VERSION "HNNBNNNYNNNNNNNNNNNNNNNNNNNNNNNNNNNNNNNNNN/4/%%%/4/'%**4NNN///"

NS_ :

BS_:

BU_: BAP_Tester BCM Gateway_Max TSGGen3_BFS TSGGen3_FS TSGGen3_HBFS TSGGen3_HFS WLC_01_CFD

BO_ 2621577104 DIA_VIP_HFS_Resp_FD: 64 BCM
 SG_ DIA_VIP_HFS_Resp_FD_Data : 0|512@1+ (1.0,0.0) [0.0|13407807929942597099574024998205846127479365820592393377723561443721764030073546976801874298166903427690031858186486050853753882811946569946433649006084095] ""  Gateway_Max

BO_ 2549880398 DIA_VIP_Req: 8 Gateway_Max
 SG_ DIA_VIP_Req_Data : 0|64@1+ (1.0,0.0) [0.0|18446744073709551615] ""  BCM

BO_ 2621445710 DIA_VIP_Req_FD: 64 Gateway_Max
 SG_ DIA_VIP_Req_FD_Data : 0|512@1+ (1.0,0.0) [0.0|13407807929942597099574024998205846127479365820592393377723561443721764030073546976801874298166903427690031858186486050853753882811946569946433649006084095] ""  BCM

BO_ 2550011470 DIA_VIP_Resp: 8 BCM
 SG_ DIA_VIP_Resp_Data : 0|64@1+ (1.0,0.0) [0.0|18446744073709551615] ""  Gateway_Max

BO_ 2621576782 DIA_VIP_Resp_FD: 64 BCM
 SG_ DIA_VIP_Resp_FD_Data : 0|512@1+ (1.0,0.0) [0.0|13407807929942597099574024998205846127479365820592393377723561443721764030073546976801874298166903427690031858186486050853753882811946569946433649006084095] ""  Gateway_Max

BO_ 2549880679 DIA_WiBli_L_Req: 8 Gateway_Max
 SG_ DIA_WiBli_L_Req : 0|64@1+ (1.0,0.0) [0.0|18446744073709551615] ""  BCM

BO_ 2550011751 DIA_WiBli_L_Resp: 8 BCM
 SG_ DIA_WiBli_L_Resp : 0|64@1+ (1.0,0.0) [0.0|18446744073709551615] ""  Gateway_Max

BO_ 2549880680 DIA_WiBli_R_Req: 8 Gateway_Max
 SG_ DIA_WiBli_R_Req : 0|64@1+ (1.0,0.0) [0.0|18446744073709551615] ""  BCM

BO_ 2550011752 DIA_WiBli_R_Resp: 8 BCM
 SG_ DIA_WiBli_R_Resp : 0|64@1+ (1.0,0.0) [0.0|18446744073709551615] ""  Gateway_Max

BO_ 2549880321 DIA_WWS_Req: 8 Gateway_Max
 SG_ DIA_WWS_Req_Data : 0|64@1+ (1.0,0.0) [0.0|18446744073709551615] ""  BCM

BO_ 2621445633 DIA_WWS_Req_FD: 64 Gateway_Max
 SG_ DIA_WWS_Req_FD_Data : 0|512@1+ (1.0,0.0) [0.0|13407807929942597099574024998205846127479365820592393377723561443721764030073546976801874298166903427690031858186486050853753882811946569946433649006084095] ""  BCM

BO_ 2550011393 DIA_WWS_Resp: 8 BCM
 SG_ DIA_WWS_Resp_Data : 0|64@1+ (1.0,0.0) [0.0|18446744073709551615] ""  Gateway_Max

BO_ 2621576705 DIA_WWS_Resp_FD: 64 BCM
 SG_ DIA_WWS_Resp_FD_Data : 0|512@1+ (1.0,0.0) [0.0|13407807929942597099574024998205846127479365820592393377723561443721764030073546976801874298166903427690031858186486050853753882811946569946433649006084095] ""  Gateway_Max

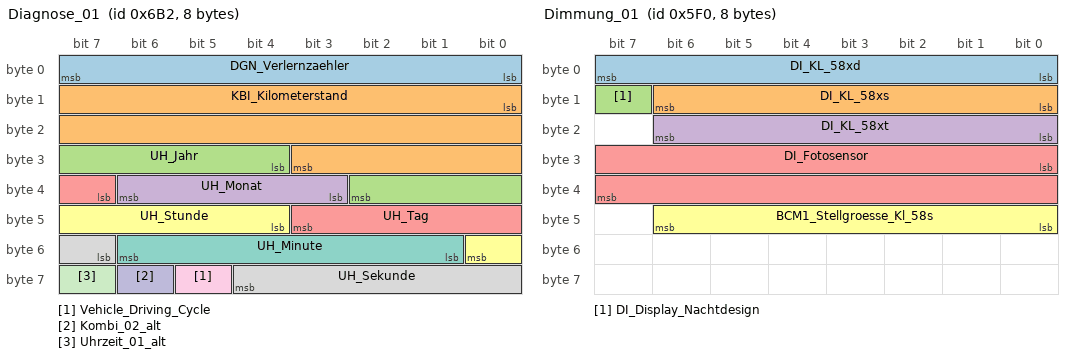
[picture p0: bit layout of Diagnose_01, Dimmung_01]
BO_ 1714 Diagnose_01: 8 Gateway_Max
 SG_ DGN_Verlernzaehler : 0|8@1+ (1,0) [0|254] ""  BCM,TSGGen3_BFS,TSGGen3_FS,TSGGen3_HBFS,TSGGen3_HFS,WLC_01_CFD
 SG_ KBI_Kilometerstand : 8|20@1+ (1,0) [0|1048573] "Unit_KiloMeter"  BCM,TSGGen3_BFS,TSGGen3_FS,TSGGen3_HBFS,TSGGen3_HFS,WLC_01_CFD
 SG_ UH_Jahr : 28|7@1+ (1,2000) [2000|2127] "Unit_Year"  BCM,TSGGen3_BFS,TSGGen3_FS,TSGGen3_HBFS,TSGGen3_HFS,WLC_01_CFD
 SG_ UH_Monat : 35|4@1+ (1,0) [1|12] "Unit_Month"  BCM,TSGGen3_BFS,TSGGen3_FS,TSGGen3_HBFS,TSGGen3_HFS,WLC_01_CFD
 SG_ UH_Tag : 39|5@1+ (1,0) [1|31] "Unit_Day"  BCM,TSGGen3_BFS,TSGGen3_FS,TSGGen3_HBFS,TSGGen3_HFS,WLC_01_CFD
 SG_ UH_Stunde : 44|5@1+ (1,0) [0|23] "Unit_Hours"  BCM,TSGGen3_BFS,TSGGen3_FS,TSGGen3_HBFS,TSGGen3_HFS,WLC_01_CFD
 SG_ UH_Minute : 49|6@1+ (1,0) [0|59] "Unit_Minut"  BCM,TSGGen3_BFS,TSGGen3_FS,TSGGen3_HBFS,TSGGen3_HFS,WLC_01_CFD
 SG_ UH_Sekunde : 55|6@1+ (1,0) [0|59] "Unit_Secon"  BCM,TSGGen3_BFS,TSGGen3_FS,TSGGen3_HBFS,TSGGen3_HFS,WLC_01_CFD
 SG_ Vehicle_Driving_Cycle : 61|1@1+ (1.0,0.0) [0.0|1] ""  BCM
 SG_ Kombi_02_alt : 62|1@1+ (1.0,0.0) [0.0|1] ""  BCM
 SG_ Uhrzeit_01_alt : 63|1@1+ (1.0,0.0) [0.0|1] ""  BCM

BO_ 851 DiETa_01: 8 BCM
 SG_ DiETas_01_CRC : 0|8@1+ (1,0) [0|255] ""  Gateway_Max
 SG_ DiETas_01_BZ : 8|4@1+ (1,0) [0|15] ""  Gateway_Max
 SG_ DiETa_Reserve_Byte2_4 : 12|1@1+ (1.0,0.0) [0.0|1] ""  Gateway_Max
 SG_ DiETa_Status : 13|2@1+ (1.0,0.0) [0.0|3] ""  Gateway_Max
 SG_ DiETa_ResponseError : 15|1@1+ (1.0,0.0) [0.0|1] ""  Gateway_Max
 SG_ DiETa_Car : 16|2@1+ (1.0,0.0) [0.0|3] ""  Gateway_Max
 SG_ DiETa_Klima : 18|2@1+ (1.0,0.0) [0.0|3] ""  Gateway_Max
 SG_ DiETa_Mode : 20|2@1+ (1.0,0.0) [0.0|3] ""  Gateway_Max
 SG_ DiETa_Parken : 22|2@1+ (1.0,0.0) [0.0|3] ""  Gateway_Max
 SG_ DiETa_FSH_Taste : 24|2@1+ (1.0,0.0) [0.0|3] ""  Gateway_Max
 SG_ DiETa_HSH_Taste : 26|2@1+ (1.0,0.0) [0.0|3] ""  Gateway_Max
 SG_ DiETa_Warnblink_Taste : 28|2@1+ (1.0,0.0) [0.0|3] ""  Gateway_Max
 SG_ DiETa_FAS_Stufe : 30|2@1+ (1.0,0.0) [0.0|3] ""  Gateway_Max
 SG_ DiETa_PAO_ON_Status : 32|2@1+ (1.0,0.0) [0.0|3] ""  Gateway_Max
 SG_ DiETa_PAO_OFF_Status : 34|2@1+ (1.0,0.0) [0.0|3] ""  Gateway_Max
 SG_ DiETa_Defrost_Taste : 36|2@1+ (1.0,0.0) [0.0|3] ""  Gateway_Max
 SG_ DiETa_Mode2 : 38|2@1+ (1.0,0.0) [0.0|3] ""  Gateway_Max
 SG_ DiETa_Lock_Unlock_Taste : 40|3@1+ (1.0,0.0) [0.0|7] ""  Gateway_Max
 SG_ DiETa_Mode_roh : 43|1@1+ (1.0,0.0) [0.0|1] ""  Gateway_Max
 SG_ ESP_Off_Taster : 44|2@1+ (1.0,0.0) [0.0|3] ""  Gateway_Max
 SG_ DiETa_Reserve_Byte6_6 : 46|2@1+ (1.0,0.0) [0.0|3] ""  Gateway_Max
 SG_ DiETa_Touch_Event : 48|4@1+ (1.0,0.0) [0.0|15] ""  Gateway_Max
 SG_ DiETa_Reserve_Byte7_4 : 52|4@1+ (1.0,0.0) [0.0|15] ""  Gateway_Max
 SG_ DiETa_Reserve_Byte8 : 56|8@1+ (1.0,0.0) [0.0|255] ""  Gateway_Max

BO_ 1520 Dimmung_01: 8 BCM
 SG_ DI_KL_58xd : 0|8@1+ (1,0) [0|253] ""  Gateway_Max,TSGGen3_BFS,TSGGen3_FS,TSGGen3_HBFS,TSGGen3_HFS
 SG_ DI_KL_58xs : 8|7@1+ (1,0) [0|100] "Unit_PerCent"  Gateway_Max,TSGGen3_BFS,TSGGen3_FS,TSGGen3_HBFS,TSGGen3_HFS
 SG_ DI_Display_Nachtdesign : 15|1@1+ (1.0,0.0) [0.0|1] ""  Gateway_Max
 SG_ DI_KL_58xt : 16|7@1+ (1,0) [0|100] "Unit_PerCent"  Gateway_Max,TSGGen3_BFS,TSGGen3_FS,TSGGen3_HBFS,TSGGen3_HFS
 SG_ DI_Fotosensor : 24|16@1+ (1,0) [0|65535] ""  Gateway_Max
 SG_ BCM1_Stellgroesse_Kl_58s : 40|7@1+ (1,0) [0|100] ""  Gateway_Max

BO_ 2463978728 DoorFunctions_BFS_01: 48 TSGGen3_BFS
 SG_ DoorFunctions_BFS_01_CRC : 0|8@1+ (1,0) [0|255] ""  Gateway_Max,TSGGen3_FS,TSGGen3_HBFS,TSGGen3_HFS
 SG_ DoorFunctions_BFS_01_BZ : 8|4@1+ (1,0) [0|15] ""  Gateway_Max,TSGGen3_FS,TSGGen3_HBFS,TSGGen3_HFS
 SG_ eTAB_BFS_Oeffnen_Betaet : 12|1@1+ (1.0,0.0) [0.0|1] ""  Gateway_Max
 SG_ eTAB_BFS_Oeffnen_Annaeh : 13|1@1+ (1.0,0.0) [0.0|1] ""  Gateway_Max
 SG_ eTAB_BFS_Schliessen_Betaet : 14|1@1+ (1.0,0.0) [0.0|1] ""  Gateway_Max
 SG_ eTAB_BFS_Schliessen_Annaeh : 15|1@1+ (1.0,0.0) [0.0|1] ""  Gateway_Max
 SG_ BT_Tuer_geoeffnet : 16|1@1+ (1.0,0.0) [0.0|1] ""  Gateway_Max,TSGGen3_FS
 SG_ BT_verriegelt : 17|1@1+ (1.0,0.0) [0.0|1] ""  Gateway_Max,TSGGen3_FS
 SG_ BT_gesafet : 18|1@1+ (1.0,0.0) [0.0|1] ""  Gateway_Max
 SG_ BT_Schluesselschalter_auf : 19|1@1+ (1.0,0.0) [0.0|1] ""  Gateway_Max
 SG_ BT_Schluesselschalter_zu : 20|1@1+ (1.0,0.0) [0.0|1] ""  Gateway_Max
 SG_ BT_Unlock_Taster : 21|1@1+ (1.0,0.0) [0.0|1] ""  Gateway_Max,TSGGen3_FS
 SG_ BT_Lock_Taster : 22|1@1+ (1.0,0.0) [0.0|1] ""  Gateway_Max,TSGGen3_FS
 SG_ BT_Sperrklinke : 23|1@1+ (1.0,0.0) [0.0|1] ""  Gateway_Max
 SG_ BT_TAG_betaetigt : 24|1@1+ (1.0,0.0) [0.0|1] ""  Gateway_Max,TSGGen3_FS
 SG_ BT_TIG_betaetigt : 25|1@1+ (1.0,0.0) [0.0|1] ""  Gateway_Max,TSGGen3_FS
 SG_ BT_EC_Spiegel_Helligkeit : 26|5@1+ (3.125,0) [0.000|96.875] "Unit_PerCent"  Gateway_Max,TSGGen3_FS
 SG_ BT_Sp_Heizung_Anf : 31|1@1+ (100,0) [0|100] "Unit_PerCent"  Gateway_Max
 SG_ BT_Tuer_Status : 32|2@1+ (1.0,0.0) [0.0|3] ""  Gateway_Max,TSGGen3_FS
 SG_ BT_TSG_hinten_verbaut : 34|1@1+ (1.0,0.0) [0.0|1] ""  Gateway_Max,TSGGen3_HBFS
 SG_ BT_Sp_Blk_def : 35|1@1+ (1.0,0.0) [0.0|1] ""  Gateway_Max,TSGGen3_FS
 SG_ BT_FH_S_ManHoch : 36|1@1+ (1.0,0.0) [0.0|1] ""  Gateway_Max
 SG_ BT_FH_S_AutoHoch : 37|1@1+ (1.0,0.0) [0.0|1] ""  Gateway_Max
 SG_ BT_FH_S_ManTief : 38|1@1+ (1.0,0.0) [0.0|1] ""  Gateway_Max
 SG_ BT_FH_S_AutoTief : 39|1@1+ (1.0,0.0) [0.0|1] ""  Gateway_Max
 SG_ BT_FH_Oeffnung : 40|8@1+ (0.5,0) [0.0|100.0] "Unit_PerCent"  Gateway_Max,TSGGen3_FS
 SG_ BT_FH_Bew_hoch : 48|1@1+ (1.0,0.0) [0.0|1] ""  Gateway_Max,TSGGen3_FS
 SG_ BT_FH_Bew_tief : 49|1@1+ (1.0,0.0) [0.0|1] ""  Gateway_Max,TSGGen3_FS
 SG_ BT_FH_Fang : 50|1@1+ (1.0,0.0) [0.0|1] ""  Gateway_Max
 SG_ BT_FH_Block : 51|1@1+ (1.0,0.0) [0.0|1] ""  Gateway_Max
 SG_ BT_FH_Thermo : 52|1@1+ (1.0,0.0) [0.0|1] ""  Gateway_Max
 SG_ BT_UEKB_aktiviert : 53|1@1+ (1.0,0.0) [0.0|1] ""  Gateway_Max
 SG_ BT_Kisi_Fehler : 54|1@1+ (1.0,0.0) [0.0|1] ""  Gateway_Max,TSGGen3_FS
 SG_ BT_FH_normiert : 55|1@1+ (1.0,0.0) [0.0|1] ""  Gateway_Max,TSGGen3_FS
 SG_ BT_Schliesstaster : 56|1@1+ (1.0,0.0) [0.0|1] ""  Gateway_Max
 SG_ BT_Zuziehhilfe_aktiv : 57|1@1+ (1.0,0.0) [0.0|1] ""  Gateway_Max
 SG_ BT_SP_ausgerastet : 58|1@1+ (1.0,0.0) [0.0|1] ""  Gateway_Max,TSGGen3_FS
 SG_ BT_SP_lr_aktiv : 59|1@1+ (1.0,0.0) [0.0|1] ""  Gateway_Max,TSGGen3_FS
 SG_ BT_SP_ht_aktiv : 60|1@1+ (1.0,0.0) [0.0|1] ""  Gateway_Max,TSGGen3_FS
 SG_ BT_SP_Heizung_aktiv : 61|1@1+ (1.0,0.0) [0.0|1] ""  Gateway_Max
 SG_ BT_Oben_Block_erw : 62|1@1+ (1.0,0.0) [0.0|1] ""  Gateway_Max,TSGGen3_FS,TSGGen3_HBFS,TSGGen3_HFS
 SG_ BT_Unten_Block_erw : 63|1@1+ (1.0,0.0) [0.0|1] ""  Gateway_Max,TSGGen3_FS,TSGGen3_HBFS,TSGGen3_HFS
 SG_ BT_Tuer_Status_QBit : 64|1@1+ (1.0,0.0) [0.0|1] ""  Gateway_Max,TSGGen3_FS
 SG_ BFS_Status_eTAG : 65|2@1+ (1.0,0.0) [0.0|3] ""  Gateway_Max,TSGGen3_FS
 SG_ BT_TCR_Mode_aktiv : 67|1@1+ (1.0,0.0) [0.0|1] ""  Gateway_Max,TSGGen3_FS,TSGGen3_HBFS,TSGGen3_HFS
 SG_ BT_Lock_Unlock_Taster : 68|1@1+ (1.0,0.0) [0.0|1] ""  Gateway_Max
 SG_ BT_SP_Heizung_Status : 71|1@1+ (1.0,0.0) [0.0|1] ""  Gateway_Max,TSGGen3_FS
 SG_ ASW_Warnung_aktiv_BFS : 72|1@1+ (1.0,0.0) [0.0|1] ""  Gateway_Max
 SG_ BT_FH_Pos_oben : 73|1@1+ (1.0,0.0) [0.0|1] ""  Gateway_Max,TSGGen3_FS,TSGGen3_HBFS,TSGGen3_HFS
 SG_ BT_Tuerschloss_defekt : 74|1@1+ (1.0,0.0) [0.0|1] ""  Gateway_Max,TSGGen3_FS,TSGGen3_HBFS,TSGGen3_HFS
 SG_ BT_Tueroeffnen_Warnung : 75|1@1+ (1.0,0.0) [0.0|1] ""  Gateway_Max
 SG_ BT_Lock_Taster_inv : 76|1@1+ (1.0,0.0) [0.0|1] ""  Gateway_Max
 SG_ BT_Schluesselschalter_zu_inv : 77|1@1+ (1.0,0.0) [0.0|1] ""  Gateway_Max
 SG_ BT_SWA_HMI_defekt : 78|1@1+ (1.0,0.0) [0.0|1] ""  Gateway_Max,TSGGen3_FS
 SG_ BT_ASW_HMI_defekt : 79|1@1+ (1.0,0.0) [0.0|1] ""  Gateway_Max,TSGGen3_FS
 SG_ BT_Schloss_oeffnen_Ansteuerung : 92|2@1+ (1.0,0.0) [0.0|3] ""  Gateway_Max
 SG_ BT_Schloss_Status_OeH_Motor : 94|2@1+ (1.0,0.0) [0.0|3] ""  Gateway_Max
 SG_ MTBT_Pos1 : 96|1@1+ (1.0,0.0) [0.0|1] ""  Gateway_Max
 SG_ MTBT_Pos2 : 97|1@1+ (1.0,0.0) [0.0|1] ""  Gateway_Max
 SG_ MTBT_Pos3 : 98|1@1+ (1.0,0.0) [0.0|1] ""  Gateway_Max
 SG_ MTBT_Pos4 : 99|1@1+ (1.0,0.0) [0.0|1] ""  Gateway_Max
 SG_ MTBT_On_Off : 100|1@1+ (1.0,0.0) [0.0|1] ""  Gateway_Max
 SG_ MTBT_M_Taste : 103|1@1+ (1.0,0.0) [0.0|1] ""  Gateway_Max
 SG_ TSG_FlHz_BFS_Unterbrech_HzK_B : 151|1@1+ (1.0,0.0) [0.0|1] ""  Gateway_Max
 SG_ TSG_FlHz_BFS_NTC_A : 152|7@1+ (1,-40) [-40|80] "Unit_DegreCelsi"  Gateway_Max
 SG_ TSG_FlHz_BFS_FnAbbruchHzKreis_A : 159|1@1+ (1.0,0.0) [0.0|1] ""  Gateway_Max
 SG_ TSG_FlHz_BFS_NTC_B : 160|7@1+ (1,-40) [-40|80] "Unit_DegreCelsi"  Gateway_Max
 SG_ TSG_FlHz_BFS_FnAbbruchHzKreis_B : 167|1@1+ (1.0,0.0) [0.0|1] ""  Gateway_Max
 SG_ SSA_BFT_ASP_Spiegelglas_Fehler : 168|3@1+ (1.0,0.0) [0.0|7] ""  Gateway_Max
 SG_ SSA_BFT_ASW_Fehler : 171|3@1+ (1.0,0.0) [0.0|7] ""  Gateway_Max,TSGGen3_FS,TSGGen3_HBFS,TSGGen3_HFS
 SG_ SSA_BFT_ASW_Status : 174|2@1+ (1.0,0.0) [0.0|3] ""  Gateway_Max
 SG_ SSA_BFT_el_Tuerantrieb_Fehler : 176|3@1+ (1.0,0.0) [0.0|7] ""  Gateway_Max
 SG_ SSA_BFT_FH_Bewegungsrichutng : 179|2@1+ (1.0,0.0) [0.0|3] ""  Gateway_Max
 SG_ SSA_BFT_FH_Fehler : 181|3@1+ (1.0,0.0) [0.0|7] ""  Gateway_Max
 SG_ SSA_BFT_Tuerverschluss_Status : 184|2@1+ (1.0,0.0) [0.0|3] ""  Gateway_Max
 SG_ SSA_BFT_ZZH_Fehler : 186|3@1+ (1.0,0.0) [0.0|7] ""  Gateway_Max
 SG_ SSA_BFT_ZZH_Status : 189|1@1+ (1.0,0.0) [0.0|1] ""  Gateway_Max
 SG_ BFT_HSK_Taste : 190|1@1+ (1.0,0.0) [0.0|1] ""  Gateway_Max
 SG_ SSA_BFT_ASP_Klappung_Status : 192|2@1+ (1.0,0.0) [0.0|3] ""  Gateway_Max
 SG_ SSA_BFT_ASP_Spiegelglas_Pos_Y : 200|7@1+ (1,0) [0|100] "Unit_PerCent"  Gateway_Max
 SG_ SSA_BFT_ZV_Ansteuern : 208|8@1+ (1.0,0.0) [0.0|255] ""  Gateway_Max
 SG_ SSA_BFT_FH_Thermoschutz : 216|1@1+ (1.0,0.0) [0.0|1] ""  Gateway_Max
 SG_ SSA_BFT_Amb_Bel_Status : 217|2@1+ (1.0,0.0) [0.0|3] ""  Gateway_Max
 SG_ SSA_BFT_Tuerverschluss_Fehler : 219|3@1+ (1.0,0.0) [0.0|7] ""  Gateway_Max
 SG_ SSA_BFT_FH_Normierung : 222|1@1+ (1.0,0.0) [0.0|1] ""  Gateway_Max
 SG_ SSA_BFT_el_Tuerantrieb_Status : 223|2@1+ (1.0,0.0) [0.0|3] ""  Gateway_Max
 SG_ SSA_BFT_ASP_Klappung_Fehler : 225|3@1+ (1.0,0.0) [0.0|7] ""  Gateway_Max
 SG_ SSA_BFT_ZV_Fehler : 228|3@1+ (1.0,0.0) [0.0|7] ""  Gateway_Max
 SG_ SSA_BFT_Amb_Bel_Fehler : 231|3@1+ (1.0,0.0) [0.0|7] ""  Gateway_Max
 SG_ ASW_Warnung_Aussenlicht_BFS_Li : 234|1@1+ (1.0,0.0) [0.0|1] ""  Gateway_Max
 SG_ ASW_Warnung_Aussenlicht_BFS_Re : 235|1@1+ (1.0,0.0) [0.0|1] ""  Gateway_Max
 SG_ SSA_BFT_ASP_Heizung_Fehler : 236|3@1+ (1.0,0.0) [0.0|7] ""  Gateway_Max
 SG_ BT_ASW_Warnton : 239|2@1+ (1.0,0.0) [0.0|3] ""  Gateway_Max
 SG_ BT_ASW_Warnung_Aussenlicht : 241|2@1+ (1.0,0.0) [0.0|3] ""  Gateway_Max
 SG_ BFS_Push_Tuergriff : 245|1@1+ (1.0,0.0) [0.0|1] ""  Gateway_Max
 SG_ BFS_Status_eTAG_ext : 246|3@1+ (1.0,0.0) [0.0|7] ""  Gateway_Max
 SG_ SOK_Doorfunctions_BFS_01_Sign000 : 352|32@1+ (1.0,0.0) [0.0|4294967295] ""  Gateway_Max

BO_ 2463978714 DoorFunctions_FS_01: 64 TSGGen3_FS
 SG_ DoorFunctions_FS_01_CRC : 0|8@1+ (1,0) [0|255] ""  Gateway_Max,TSGGen3_BFS,TSGGen3_HBFS,TSGGen3_HFS
 SG_ DoorFunctions_FS_01_BZ : 8|4@1+ (1,0) [0|15] ""  Gateway_Max,TSGGen3_BFS,TSGGen3_HBFS,TSGGen3_HFS
 SG_ eTAB_FS_Oeffnen_Annaeh : 12|1@1+ (1.0,0.0) [0.0|1] ""  Gateway_Max
 SG_ eTAB_FS_Oeffnen_Betaet : 13|1@1+ (1.0,0.0) [0.0|1] ""  Gateway_Max
 SG_ eTAB_FS_Schliessen_Annaeh : 14|1@1+ (1.0,0.0) [0.0|1] ""  Gateway_Max
 SG_ eTAB_FS_Schliessen_Betaet : 15|1@1+ (1.0,0.0) [0.0|1] ""  Gateway_Max
 SG_ FT_Tuer_geoeffnet : 16|1@1+ (1.0,0.0) [0.0|1] ""  Gateway_Max,TSGGen3_BFS,TSGGen3_HBFS,TSGGen3_HFS
 SG_ FT_verriegelt : 17|1@1+ (1.0,0.0) [0.0|1] ""  Gateway_Max,TSGGen3_BFS,TSGGen3_HBFS,TSGGen3_HFS
 SG_ FT_gesafet : 18|1@1+ (1.0,0.0) [0.0|1] ""  Gateway_Max,TSGGen3_BFS,TSGGen3_HBFS,TSGGen3_HFS
 SG_ FT_Schluesselschalter_auf : 19|1@1+ (1.0,0.0) [0.0|1] ""  Gateway_Max,TSGGen3_BFS,TSGGen3_HBFS,TSGGen3_HFS
 SG_ FT_Schluesselschalter_zu : 20|1@1+ (1.0,0.0) [0.0|1] ""  Gateway_Max,TSGGen3_BFS,TSGGen3_HBFS,TSGGen3_HFS
 SG_ FT_Unlock_Taster : 21|1@1+ (1.0,0.0) [0.0|1] ""  Gateway_Max,TSGGen3_BFS,TSGGen3_HBFS,TSGGen3_HFS
 SG_ FT_Lock_Taster : 22|1@1+ (1.0,0.0) [0.0|1] ""  Gateway_Max,TSGGen3_BFS,TSGGen3_HBFS,TSGGen3_HFS
 SG_ FT_Sperrklinke : 23|1@1+ (1.0,0.0) [0.0|1] ""  Gateway_Max
 SG_ FT_TAG_betaetigt : 24|1@1+ (1.0,0.0) [0.0|1] ""  Gateway_Max
 SG_ FT_TIG_betaetigt : 25|1@1+ (1.0,0.0) [0.0|1] ""  Gateway_Max
 SG_ FT_IRUE_Taste : 26|1@1+ (1.0,0.0) [0.0|1] ""  Gateway_Max
 SG_ FT_HD_Taste : 27|1@1+ (1.0,0.0) [0.0|1] ""  Gateway_Max
 SG_ FT_TD_Taste_Fehler : 28|1@1+ (1.0,0.0) [0.0|1] ""  Gateway_Max
 SG_ FT_TD_Taste : 29|1@1+ (1.0,0.0) [0.0|1] ""  Gateway_Max
 SG_ eTAB_FS_Bowdenzug_Auswerfen : 30|1@1+ (1.0,0.0) [0.0|1] ""  Gateway_Max
 SG_ FT_Sp_Heizung_Anf : 31|1@1+ (100,0) [0|100] "Unit_PerCent"  Gateway_Max
 SG_ FT_HD_Taste_2 : 32|1@1+ (1.0,0.0) [0.0|1] ""  Gateway_Max
 SG_ FT_Lock_Unlock_Taster : 33|1@1+ (1.0,0.0) [0.0|1] ""  Gateway_Max
 SG_ FT_TSG_hinten_verbaut : 34|1@1+ (1.0,0.0) [0.0|1] ""  Gateway_Max,TSGGen3_HFS
 SG_ FT_Sp_Blk_def : 35|1@1+ (1.0,0.0) [0.0|1] ""  Gateway_Max
 SG_ FT_FH_S_ManHoch : 36|1@1+ (1.0,0.0) [0.0|1] ""  Gateway_Max
 SG_ FT_FH_S_AutoHoch : 37|1@1+ (1.0,0.0) [0.0|1] ""  Gateway_Max
 SG_ FT_FH_S_ManTief : 38|1@1+ (1.0,0.0) [0.0|1] ""  Gateway_Max
 SG_ FT_FH_S_AutoTief : 39|1@1+ (1.0,0.0) [0.0|1] ""  Gateway_Max
 SG_ FT_FH_Oeffnung : 40|8@1+ (0.5,0) [0.0|100.0] "Unit_PerCent"  Gateway_Max
 SG_ FT_FH_Bew_hoch : 48|1@1+ (1.0,0.0) [0.0|1] ""  Gateway_Max,TSGGen3_BFS,TSGGen3_HBFS
 SG_ FT_FH_Bew_tief : 49|1@1+ (1.0,0.0) [0.0|1] ""  Gateway_Max,TSGGen3_BFS,TSGGen3_HBFS
 SG_ FT_FH_Fang : 50|1@1+ (1.0,0.0) [0.0|1] ""  Gateway_Max
 SG_ FT_FH_Block : 51|1@1+ (1.0,0.0) [0.0|1] ""  Gateway_Max
 SG_ FT_FH_Thermo : 52|1@1+ (1.0,0.0) [0.0|1] ""  Gateway_Max
 SG_ FT_UEKB_aktiviert : 53|1@1+ (1.0,0.0) [0.0|1] ""  Gateway_Max
 SG_ ASW_HMI_defekt : 54|1@1+ (1.0,0.0) [0.0|1] ""  Gateway_Max
 SG_ FT_FH_normiert : 55|1@1+ (1.0,0.0) [0.0|1] ""  Gateway_Max
 SG_ FT_Schliesstaster : 56|1@1+ (1.0,0.0) [0.0|1] ""  Gateway_Max
 SG_ FT_Zuziehhilfe_aktiv : 57|1@1+ (1.0,0.0) [0.0|1] ""  Gateway_Max
 SG_ FT_SP_ausgerastet : 58|1@1+ (1.0,0.0) [0.0|1] ""  Gateway_Max
 SG_ FT_SP_lr_aktiv : 59|1@1+ (1.0,0.0) [0.0|1] ""  Gateway_Max
 SG_ FT_SP_ht_aktiv : 60|1@1+ (1.0,0.0) [0.0|1] ""  Gateway_Max
 SG_ ASW_wakeup : 61|1@1+ (1.0,0.0) [0.0|1] ""  Gateway_Max,TSGGen3_BFS,TSGGen3_HBFS,TSGGen3_HFS
 SG_ FT_Oben_Block_erw : 62|1@1+ (1.0,0.0) [0.0|1] ""  Gateway_Max,TSGGen3_BFS,TSGGen3_HBFS,TSGGen3_HFS
 SG_ FT_Unten_Block_erw : 63|1@1+ (1.0,0.0) [0.0|1] ""  Gateway_Max,TSGGen3_BFS,TSGGen3_HBFS,TSGGen3_HFS
 SG_ FT_Kisi_li_aktiv : 64|1@1+ (1.0,0.0) [0.0|1] ""  Gateway_Max,TSGGen3_BFS,TSGGen3_HBFS,TSGGen3_HFS
 SG_ FT_Kisi_re_aktiv : 65|1@1+ (1.0,0.0) [0.0|1] ""  Gateway_Max,TSGGen3_BFS,TSGGen3_HBFS,TSGGen3_HFS
 SG_ FT_Kisi_Taster_li : 66|1@1+ (1.0,0.0) [0.0|1] ""  Gateway_Max,TSGGen3_BFS,TSGGen3_HBFS,TSGGen3_HFS
 SG_ FT_Kisi_Taster_re : 67|1@1+ (1.0,0.0) [0.0|1] ""  Gateway_Max,TSGGen3_BFS,TSGGen3_HBFS,TSGGen3_HFS
 SG_ FT_BFS_Fond_Freigabe : 68|1@1+ (1.0,0.0) [0.0|1] ""  Gateway_Max,TSGGen3_BFS,TSGGen3_HBFS,TSGGen3_HFS
 SG_ FT_Kisi_Fehler : 69|1@1+ (1.0,0.0) [0.0|1] ""  Gateway_Max
 SG_ FT_Daemmglas : 70|1@1+ (1.0,0.0) [0.0|1] ""  Gateway_Max
 SG_ FT_SP_Heizung_Status : 71|1@1+ (1.0,0.0) [0.0|1] ""  Gateway_Max,TSGGen3_BFS,TSGGen3_HBFS,TSGGen3_HFS
 SG_ ASW_Warnung_aktiv_FS : 72|1@1+ (1.0,0.0) [0.0|1] ""  Gateway_Max
 SG_ FT_FH_Pos_oben : 73|1@1+ (1.0,0.0) [0.0|1] ""  Gateway_Max
 SG_ FT_Tuerschloss_defekt : 74|1@1+ (1.0,0.0) [0.0|1] ""  Gateway_Max,TSGGen3_BFS,TSGGen3_HBFS,TSGGen3_HFS
 SG_ FT_SWA_Taster : 75|1@1+ (1.0,0.0) [0.0|1] ""  Gateway_Max
 SG_ SWA_HMI_Diagnose : 76|2@1+ (1.0,0.0) [0.0|3] ""  Gateway_Max
 SG_ FS_Status_eTAG : 78|2@1+ (1.0,0.0) [0.0|3] ""  Gateway_Max,TSGGen3_BFS,TSGGen3_HBFS
 SG_ FT_Schloss_oeffnen_Ansteuerung : 92|2@1+ (1.0,0.0) [0.0|3] ""  Gateway_Max
 SG_ FT_Schloss_Status_OeH_Motor : 94|2@1+ (1.0,0.0) [0.0|3] ""  Gateway_Max
 SG_ MTFT_Pos1_EE : 96|1@1+ (1.0,0.0) [0.0|1] ""  Gateway_Max
 SG_ MTFT_Pos2 : 97|1@1+ (1.0,0.0) [0.0|1] ""  Gateway_Max
 SG_ MTFT_Pos3 : 98|1@1+ (1.0,0.0) [0.0|1] ""  Gateway_Max
 SG_ MTFT_Pos4 : 99|1@1+ (1.0,0.0) [0.0|1] ""  Gateway_Max
 SG_ MTFT_On_Off : 100|1@1+ (1.0,0.0) [0.0|1] ""  Gateway_Max
 SG_ MTFT_Verst_akt : 101|1@1+ (1.0,0.0) [0.0|1] ""  Gateway_Max
 SG_ MTFT_M_Taste : 103|1@1+ (1.0,0.0) [0.0|1] ""  Gateway_Max
 SG_ TSG_FlHz_FS_Unterbrech_HzK_A : 150|1@1+ (1.0,0.0) [0.0|1] ""  Gateway_Max
 SG_ TSG_FlHz_FS_Unterbrech_HzK_B : 151|1@1+ (1.0,0.0) [0.0|1] ""  Gateway_Max
 SG_ TSG_FlHz_FS_NTC_A : 152|7@1+ (1,-40) [-40|80] "Unit_DegreCelsi"  Gateway_Max
 SG_ TSG_FlHz_FS_FnAbbruchHzKreis_A : 159|1@1+ (1.0,0.0) [0.0|1] ""  Gateway_Max
 SG_ TSG_FlHz_FS_NTC_B : 160|7@1+ (1,-40) [-40|80] "Unit_DegreCelsi"  Gateway_Max
 SG_ TSG_FlHz_FS_FnAbbruchHzKreis_B : 167|1@1+ (1.0,0.0) [0.0|1] ""  Gateway_Max
 SG_ SSA_FT_ASP_Klappung_Fehler : 168|3@1+ (1.0,0.0) [0.0|7] ""  Gateway_Max
 SG_ SSA_FT_ASP_Spiegelglas_Fehler : 171|3@1+ (1.0,0.0) [0.0|7] ""  Gateway_Max
 SG_ SSA_FT_ASW_Fehler : 174|3@1+ (1.0,0.0) [0.0|7] ""  Gateway_Max
 SG_ SSA_FT_ASW_Status : 177|2@1+ (1.0,0.0) [0.0|3] ""  Gateway_Max
 SG_ SSA_FT_el_Tuerantrieb_Fehler : 179|3@1+ (1.0,0.0) [0.0|7] ""  Gateway_Max
 SG_ SSA_FT_el_Tuerantrieb_Status : 182|2@1+ (1.0,0.0) [0.0|3] ""  Gateway_Max
 SG_ SSA_FT_FH_Bewegungsrichutng : 184|2@1+ (1.0,0.0) [0.0|3] ""  Gateway_Max
 SG_ SSA_FT_FH_Fehler : 186|3@1+ (1.0,0.0) [0.0|7] ""  Gateway_Max
 SG_ SSA_FT_FH_Normierung : 189|1@1+ (1.0,0.0) [0.0|1] ""  Gateway_Max
 SG_ SSA_FT_FH_Thermoschutz : 190|1@1+ (1.0,0.0) [0.0|1] ""  Gateway_Max
 SG_ SSA_FT_Tuerverschluss_Status : 191|2@1+ (1.0,0.0) [0.0|3] ""  Gateway_Max
 SG_ SSA_FT_ZZH_Fehler : 193|3@1+ (1.0,0.0) [0.0|7] ""  Gateway_Max
 SG_ SSA_FT_ZZH_Status : 196|1@1+ (1.0,0.0) [0.0|1] ""  Gateway_Max
 SG_ SSR_Temp_Freigabe : 197|1@1+ (1.0,0.0) [0.0|1] ""  Gateway_Max,TSGGen3_HBFS,TSGGen3_HFS
 SG_ ASW_Warnung_Aussenlicht_FS_Li : 198|1@1+ (1.0,0.0) [0.0|1] ""  Gateway_Max
 SG_ ASW_Warnung_Aussenlicht_FS_Re : 199|1@1+ (1.0,0.0) [0.0|1] ""  Gateway_Max
 SG_ MemFT_Pos3 : 210|2@1+ (1.0,0.0) [0.0|3] ""  Gateway_Max
 SG_ FT_ASW_Warnton : 212|2@1+ (1.0,0.0) [0.0|3] ""  Gateway_Max
 SG_ FT_ASW_Warnung_Aussenlicht : 214|2@1+ (1.0,0.0) [0.0|3] ""  Gateway_Max
 SG_ MemFT_Pos2 : 216|2@1+ (1.0,0.0) [0.0|3] ""  Gateway_Max
 SG_ MemFT_Pos4 : 221|2@1+ (1.0,0.0) [0.0|3] ""  Gateway_Max
 SG_ MemFT_Pos1_EE : 223|2@1+ (1.0,0.0) [0.0|3] ""  Gateway_Max
 SG_ SP_FT_oben : 280|1@1+ (1.0,0.0) [0.0|1] ""  Gateway_Max,TSGGen3_BFS
 SG_ SP_FT_unten : 281|1@1+ (1.0,0.0) [0.0|1] ""  Gateway_Max,TSGGen3_BFS
 SG_ SP_FT_links : 282|1@1+ (1.0,0.0) [0.0|1] ""  Gateway_Max,TSGGen3_BFS
 SG_ SP_FT_rechts : 283|1@1+ (1.0,0.0) [0.0|1] ""  Gateway_Max,TSGGen3_BFS
 SG_ SP_BT_oben : 284|1@1+ (1.0,0.0) [0.0|1] ""  Gateway_Max,TSGGen3_BFS
 SG_ SP_BT_unten : 285|1@1+ (1.0,0.0) [0.0|1] ""  Gateway_Max,TSGGen3_BFS
 SG_ SP_BT_links : 286|1@1+ (1.0,0.0) [0.0|1] ""  Gateway_Max,TSGGen3_BFS
 SG_ SP_BT_rechts : 287|1@1+ (1.0,0.0) [0.0|1] ""  Gateway_Max,TSGGen3_BFS
 SG_ SP_abklappen : 288|1@1+ (1.0,0.0) [0.0|1] ""  Gateway_Max,TSGGen3_BFS
 SG_ SP_anklappen : 289|1@1+ (1.0,0.0) [0.0|1] ""  Gateway_Max,TSGGen3_BFS
 SG_ SP_normieren : 290|1@1+ (1.0,0.0) [0.0|1] ""  Gateway_Max,TSGGen3_BFS
 SG_ SP_Spg_Verstellschalter_Fehler : 291|1@1+ (1.0,0.0) [0.0|1] ""  Gateway_Max
 SG_ SP_Hzg_Taster : 292|1@1+ (1.0,0.0) [0.0|1] ""  Gateway_Max,TSGGen3_BFS
 SG_ SP_Bordsteinfunktion : 293|2@1+ (1.0,0.0) [0.0|3] ""  Gateway_Max,TSGGen3_BFS
 SG_ SP_S_oben : 296|1@1+ (1.0,0.0) [0.0|1] ""  Gateway_Max,TSGGen3_BFS
 SG_ SP_S_unten : 297|1@1+ (1.0,0.0) [0.0|1] ""  Gateway_Max,TSGGen3_BFS
 SG_ SP_S_links : 298|1@1+ (1.0,0.0) [0.0|1] ""  Gateway_Max,TSGGen3_BFS
 SG_ SP_S_rechts : 299|1@1+ (1.0,0.0) [0.0|1] ""  Gateway_Max,TSGGen3_BFS
 SG_ SP_Auswahl_li : 300|1@1+ (1.0,0.0) [0.0|1] ""  Gateway_Max,TSGGen3_BFS
 SG_ SP_Auswahl_re : 301|1@1+ (1.0,0.0) [0.0|1] ""  Gateway_Max,TSGGen3_BFS
 SG_ SP_ARA_Status : 302|1@1+ (1.0,0.0) [0.0|1] ""  Gateway_Max,TSGGen3_BFS
 SG_ SP_S_Klappen : 303|1@1+ (1.0,0.0) [0.0|1] ""  Gateway_Max,TSGGen3_BFS
 SG_ SP_Verstellschalter_Fehler : 304|1@1+ (1.0,0.0) [0.0|1] ""  Gateway_Max
 SG_ FT_Tuer_Status : 340|2@1+ (1.0,0.0) [0.0|3] ""  Gateway_Max
 SG_ FT_Tuer_Status_QBit : 342|1@1+ (1.0,0.0) [0.0|1] ""  Gateway_Max
 SG_ FT_BFS_Tuer_Status : 345|2@1+ (1.0,0.0) [0.0|3] ""  Gateway_Max
 SG_ FT_HBFS_Tuer_Status : 347|2@1+ (1.0,0.0) [0.0|3] ""  Gateway_Max
 SG_ FT_HFS_Tuer_Status : 349|2@1+ (1.0,0.0) [0.0|3] ""  Gateway_Max
 SG_ FT_Tueroeffnen_Warnung : 351|1@1+ (1.0,0.0) [0.0|1] ""  Gateway_Max
 SG_ FT_SP_Heizung_ein : 352|1@1+ (1.0,0.0) [0.0|1] ""  Gateway_Max,TSGGen3_BFS
 SG_ FT_Kisi_Taster_li_02 : 353|1@1+ (1.0,0.0) [0.0|1] ""  Gateway_Max,TSGGen3_BFS,TSGGen3_HBFS,TSGGen3_HFS
 SG_ FT_Kisi_Taster_re_02 : 354|1@1+ (1.0,0.0) [0.0|1] ""  Gateway_Max,TSGGen3_BFS,TSGGen3_HBFS,TSGGen3_HFS
 SG_ FT_TD_Taste_Status : 355|2@1+ (1.0,0.0) [0.0|3] ""  Gateway_Max
 SG_ FT_TCR_Mode_aktiv : 357|1@1+ (1.0,0.0) [0.0|1] ""  Gateway_Max,TSGGen3_BFS,TSGGen3_HBFS,TSGGen3_HFS
 SG_ TBF_FS_Touch_Event : 358|4@1+ (1.0,0.0) [0.0|15] ""  Gateway_Max
 SG_ FT_KiSi_Status_Soll_HBFS : 362|1@1+ (1.0,0.0) [0.0|1] ""  Gateway_Max
 SG_ FT_KiSi_Status_Soll_HFS : 363|1@1+ (1.0,0.0) [0.0|1] ""  Gateway_Max
 SG_ FS_Push_Tuergriff : 364|1@1+ (1.0,0.0) [0.0|1] ""  Gateway_Max
 SG_ TSG_FS_Spiegel_angeklappt : 365|1@1+ (1.0,0.0) [0.0|1] ""  Gateway_Max
 SG_ FT_Cargolock_bet : 366|1@1+ (1.0,0.0) [0.0|1] ""  Gateway_Max
 SG_ SSA_FT_ASP_Heizung_Fehler : 384|3@1+ (1.0,0.0) [0.0|7] ""  Gateway_Max
 SG_ SSA_FT_Amb_Bel_Fehler : 387|3@1+ (1.0,0.0) [0.0|7] ""  Gateway_Max
 SG_ SSA_FT_Amb_Bel_Status : 390|2@1+ (1.0,0.0) [0.0|3] ""  Gateway_Max
 SG_ SSA_FT_ASP_Spiegelglas_Pos_X : 392|7@1+ (1,0) [0|100] "Unit_PerCent"  Gateway_Max
 SG_ SSA_FT_ZV_Status : 408|4@1+ (1.0,0.0) [0.0|15] ""  Gateway_Max
 SG_ FS_Status_eTAG_ext : 412|3@1+ (1.0,0.0) [0.0|7] ""  Gateway_Max
 SG_ SSA_FT_Tuerverschluss_Fehler : 416|3@1+ (1.0,0.0) [0.0|7] ""  Gateway_Max
 SG_ SSA_FT_ZV_Fehler : 419|3@1+ (1.0,0.0) [0.0|7] ""  Gateway_Max
 SG_ FT_HD_Taste_auf : 422|1@1+ (1.0,0.0) [0.0|1] ""  Gateway_Max
 SG_ FT_HD_Taste_zu : 423|1@1+ (1.0,0.0) [0.0|1] ""  Gateway_Max
 SG_ SOK_Doorfunctions_FS_01_Signatur : 480|32@1+ (1.0,0.0) [0.0|4294967295] ""  Gateway_Max

CM_ BO_ 2549880321 "LIN Flashen Wischwinkelsteuerung (DK2F)";
CM_ BO_ 2550011393 "LIN Flashen Wischwinkelsteuerung (DK2F)";
CM_ BO_ 1520 "ab MQB nach abgestimmten FLH Dimmung";

CM_ SG_ 2621577104 DIA_VIP_HFS_Resp_FD_Data "Diagnose Response FD VIP_HFS";

CM_ SG_ 2549880398 DIA_VIP_Req_Data "Diagnose Request VIP";

CM_ SG_ 2621445710 DIA_VIP_Req_FD_Data "Diagnose Request FD VIP";

CM_ SG_ 2550011470 DIA_VIP_Resp_Data "Diagnose Response Flashen VIP";

CM_ SG_ 2621576782 DIA_VIP_Resp_FD_Data "Diagnose Response FD VIP";

CM_ SG_ 2549880679 DIA_WiBli_L_Req "DK2F Flash Diagnosezugriff";

CM_ SG_ 2550011751 DIA_WiBli_L_Resp "DK2F Flash Diagnosezugriff";

CM_ SG_ 2549880680 DIA_WiBli_R_Req "DK2F Flash Diagnosezugriff";

CM_ SG_ 2550011752 DIA_WiBli_R_Resp "DK2F Flash Diagnosezugriff";

CM_ SG_ 2549880321 DIA_WWS_Req_Data "Diagnose Request Flashen WWS";

CM_ SG_ 2621445633 DIA_WWS_Req_FD_Data "Diagnose Request  FD WWS";

CM_ SG_ 2550011393 DIA_WWS_Resp_Data "Diagnose Response Flashen WWS";

CM_ SG_ 2621576705 DIA_WWS_Resp_FD_Data "Diagnose Response FD WWS";

CM_ SG_ 1714 DGN_Verlernzaehler "wrap around 254 --> 0";
CM_ SG_ 1714 KBI_Kilometerstand "Fehler wird ausgegeben, falls Kilometerstand nicht restaurierbar
";
CM_ SG_ 1714 UH_Minute "0x3C- 0x3f = Werte ungültig";
CM_ SG_ 1714 UH_Monat "0x0D, 0xF =  Werte ungültig
0x0E = Relatives Datum (nur VW)";
CM_ SG_ 1714 UH_Sekunde "0x3C- 0x3f = Werte ungültig";
CM_ SG_ 1714 UH_Stunde "0x18 - 0x1F = Werte ungültig";
CM_ SG_ 1714 UH_Tag "0x0: reserviert bei VW";
CM_ SG_ 1714 Uhrzeit_01_alt "
";
CM_ SG_ 1714 Vehicle_Driving_Cycle "Optimierung der Inbetriebnahme von Steuergeräten in einem Teilverbau in der Produktion.
Siehe VW80114. Signal bildet (durch eine Gateway-Funktion) den Inhalt des Signals OBD_Driving_Cycle ab.";

CM_ SG_ 851 DiETa_Car "Status Car-Taste";
CM_ SG_ 851 DiETa_Defrost_Taste "Max. Defrost AN/AUS";
CM_ SG_ 851 DiETa_FAS_Stufe "Status FAS-Taste";
CM_ SG_ 851 DiETa_FSH_Taste "Frontscheibenheizung AN/AUS";
CM_ SG_ 851 DiETa_HSH_Taste "Heckscheibenheizung AN/AUS";
CM_ SG_ 851 DiETa_Klima "Status Klimataste";
CM_ SG_ 851 DiETa_Lock_Unlock_Taste "Lock-/Unlock-Taste";
CM_ SG_ 851 DiETa_Mode "Status Modetaste";
CM_ SG_ 851 DiETa_Mode2 "Status Mode2taste (GTE-Taster im VW380 PHEV)";
CM_ SG_ 851 DiETa_Mode_roh "Erweitertes SIgnal zur Erfüllung der OBD-Relevanz für die Funktion Mode auf der DiETa";
CM_ SG_ 851 DiETa_PAO_OFF_Status "Istwert für LED 'OFF' in Anzeige Passenger Airbag On/Off";
CM_ SG_ 851 DiETa_PAO_ON_Status "Istwert für LED 'ON' in Anzeige Passenger Airbag On/Off";
CM_ SG_ 851 DiETa_Parken "Status Parkentaste";
CM_ SG_ 851 DiETa_Reserve_Byte2_4 "Vorhalt, Initialisierung mit '0'";
CM_ SG_ 851 DiETa_Reserve_Byte6_6 "Vorhalt, Initialisierung mit '0'";
CM_ SG_ 851 DiETa_Reserve_Byte7_4 "Vorhalt, Initialisierung mit '0'";
CM_ SG_ 851 DiETa_Reserve_Byte8 "Vorhalt, Initialisierung mit '0'";
CM_ SG_ 851 DiETa_ResponseError "siehe LIN2.0-Specification
(Darf nicht über ein Fehlergueltigkeitsbit abgesichtert werden!)";
CM_ SG_ 851 DiETa_Status "Betriebszustand Direkteinstiegstasten";
CM_ SG_ 851 DiETa_Touch_Event "Touch_Events für Informationen einer Funktionsauslösung auf DiETa, welches dann für bspw. ein akustisches Signal zentral umgesetzt werden können.";
CM_ SG_ 851 DiETa_Warnblink_Taste "Status Warnblinktaster";
CM_ SG_ 851 DiETas_01_BZ "4bit Botschaftszähler, wird mit jeder Sendebotschaft inkrementiert";
CM_ SG_ 851 DiETas_01_CRC "Für MLB:
Berechnung siehe Lastenheft 'Kommunikationsabsicherung für FlexRay und CAN'
Ab MQB und MLBevo:
Berechnung siehe Lastenheft 'End-to-End Kommunikationsabsicherung'

Endwerte siehe Begleitdokument 'S-PDU Kennungsfolgen'";
CM_ SG_ 851 ESP_Off_Taster "Das Signal beschreibt den Zustand der ESP Taste, die im MLBevo vom BCM1 eingelesen wird.
";

CM_ SG_ 1520 BCM1_Stellgroesse_Kl_58s "Rohwert Dimmpoti";
CM_ SG_ 1520 DI_Display_Nachtdesign "Für Displays sind oft  automatische Umschaltungen von Tag-/Nachtdesign vorgesehen.
Es gibt jedoch Zustände, an denen auch tagsüber das Abblendlicht eingeschaltet ist.
z.B. Dauerfahrlicht, Geschwindigkeitsabhängiges 'Licht-An-Bei-Autobahn', 'Regenlicht',";
CM_ SG_ 1520 DI_Fotosensor "Helligkeitswert Fotosensor
Für die Dimmung relevanter Wert zur Sensierung der Umgebungshelligkeit
Im Detail beschrieben im 'Funktionslastenheft Dimmung MQB'.";
CM_ SG_ 1520 DI_KL_58xd "Klemme 58xd Display- und Funktionsbeleuchtung
Mit der Klemme 58xd wird die Helligkeit der Display- und der Funktionsbeleuchtungen der Schalter gesteuert.
Im Detail beschrieben im 'Funktionslastenheft Dimmung MQB'.";
CM_ SG_ 1520 DI_KL_58xs "Suchbeleuchtung Schalter
EIN-AUS-Schaltalgorithmus der allgemeinen Schaltersuchbeleuchtung. 
Im Detail beschrieben im 'Funktionslastenheft Dimmung MQB'.
";
CM_ SG_ 1520 DI_KL_58xt "Timergesteuerte Suchbeleuchtung
Der EIN-AUS-Schaltalgorithmus für die vor- und nachlaufende Schaltersuchbeleuchtungen beim Ein- & Aussteigen; z.B.: Start/Stop-Taster.
Im Detail beschrieben im 'Funktionslastenheft Dimmung MQB'.";

CM_ SG_ 2463978728 ASW_Warnung_aktiv_BFS "Abschaltung der Ambientefunktion Beifahrertür bei aktiver ASW Warnung an der Fahrertür";
CM_ SG_ 2463978728 ASW_Warnung_Aussenlicht_BFS_Li "Anzeige Ausstiegwarnung nach aussen, z.B. Heckleuchte";
CM_ SG_ 2463978728 ASW_Warnung_Aussenlicht_BFS_Re "Anzeige Ausstiegwarnung nach aussen, z.B. Heckleuchte";
CM_ SG_ 2463978728 BFS_Push_Tuergriff "Push zum Ausfahren der Flush-Tuergriffe";
CM_ SG_ 2463978728 BFS_Status_eTAG "Status des elektrischen Tueraussengriffes Beifahrertuer";
CM_ SG_ 2463978728 BFS_Status_eTAG_ext "erweitert um den Wert 'verfährt'";
CM_ SG_ 2463978728 BFT_HSK_Taste "Taster zum Öffnen des Handschufachkasten";
CM_ SG_ 2463978728 BT_ASW_HMI_defekt "Zeigt an, ob die ASW-Anzeige defekt ist.";
CM_ SG_ 2463978728 BT_ASW_Warnton "erzeugt ein Warnton bei AS Warnung";
CM_ SG_ 2463978728 BT_ASW_Warnung_Aussenlicht "zeigt in den Heckleuchte ein Symbol an";
CM_ SG_ 2463978728 BT_EC_Spiegel_Helligkeit "Dimmung für den Aussenspiegel in %";
CM_ SG_ 2463978728 BT_FH_Bew_hoch "Fensterheber in Bewegung Richtung hoch";
CM_ SG_ 2463978728 BT_FH_Bew_tief "Fensterheber in Bewegung Richtung tief";
CM_ SG_ 2463978728 BT_FH_Block "Fensterscheibe befindet sich im mechanischen Block (oben oder unten)";
CM_ SG_ 2463978728 BT_FH_Fang "Fangbereich ist 4mm von oberer Lippendichtung";
CM_ SG_ 2463978728 BT_FH_normiert "Die Position der Fensterheberscheibe ist bekannt";
CM_ SG_ 2463978728 BT_FH_Oeffnung "Gibt den Fensteröffnungswert in % an.";
CM_ SG_ 2463978728 BT_FH_S_AutoHoch "FH Schalter automatisch hoch gedrückt";
CM_ SG_ 2463978728 BT_FH_S_AutoTief "FH Schalter automatisch tief gedrückt";
CM_ SG_ 2463978728 BT_FH_S_ManHoch "FH Schalter manuell hoch gedrückt";
CM_ SG_ 2463978728 BT_FH_S_ManTief "FH Schalter manuell tief gedrückt";
CM_ SG_ 2463978728 BT_FH_Thermo "gibt an ob Fensterheber im Thermoschutz ist";
CM_ SG_ 2463978728 BT_gesafet "Im Zustand Safe wird auch das Signal BT_verriegelt = 1 gesendet";
CM_ SG_ 2463978728 BT_Kisi_Fehler "Fehlerstatus Kindersicherungsfunktion";
CM_ SG_ 2463978728 BT_Lock_Taster "Verriegelungstaster";
CM_ SG_ 2463978728 BT_Lock_Taster_inv "Lock Taster nicht betätigt";
CM_ SG_ 2463978728 BT_Lock_Unlock_Taster "ZV Funktion Lock Unlock mit Toggle-Logik";
CM_ SG_ 2463978728 BT_Oben_Block_erw "Fensterheber in Blockerwartung oben";
CM_ SG_ 2463978728 BT_Schliesstaster "Schliesstaster Beifahrertür";
CM_ SG_ 2463978728 BT_Schloss_oeffnen_Ansteuerung "Hier wird die Ansteuerung der  Schlossoeffnung angezeigt. Bei mechanischen Schloessern wird Init gesendet.";
CM_ SG_ 2463978728 BT_Schloss_Status_OeH_Motor "Schossstatus 
Bei Schloss mit frueherem Stand als eSchloss2.0 wird init geschickt";
CM_ SG_ 2463978728 BT_Schluesselschalter_auf "Schlüsselschalter Richtung auf betätigt";
CM_ SG_ 2463978728 BT_Schluesselschalter_zu "Schluesselschalter Richtung zu betaetigt";
CM_ SG_ 2463978728 BT_Schluesselschalter_zu_inv "Schluesselschalter zu nicht betaetigt";
CM_ SG_ 2463978728 BT_SP_ausgerastet "Spiegel ausgerastet";
CM_ SG_ 2463978728 BT_Sp_Blk_def "Blinker am Spiegel defekt";
CM_ SG_ 2463978728 BT_SP_Heizung_aktiv "Zustand Spiegelheizung Beifahrertür";
CM_ SG_ 2463978728 BT_Sp_Heizung_Anf "Kundenanforderung der Außenspiegelheizung Beifahrertür";
CM_ SG_ 2463978728 BT_SP_Heizung_Status "Status der Spiegelheizung";
CM_ SG_ 2463978728 BT_SP_ht_aktiv "Spiegelverstellung in Richtung hoch/tief aktiv";
CM_ SG_ 2463978728 BT_SP_lr_aktiv "Spiegelverstellung in Richtung links/rechts aktiv";
CM_ SG_ 2463978728 BT_Sperrklinke "Vorraste für Schloß

zwischen Vor- und Hauptraste Signal kurz auf 1, danach wieder auf 0 wenn Tür in Hauptraste (Tür ist sicher zu wenn Sperrklinke und Türkontakt auf 0 sind)";
CM_ SG_ 2463978728 BT_SWA_HMI_defekt "Zeigt an, ob die SWA-Anzeige defekt ist.";
CM_ SG_ 2463978728 BT_TAG_betaetigt "Türaussengriff";
CM_ SG_ 2463978728 BT_TCR_Mode_aktiv "Signal zeigt eine aktive mechanische Redundanz am Türschloss an.";
CM_ SG_ 2463978728 BT_TIG_betaetigt "Türinnengriff";
CM_ SG_ 2463978728 BT_Tuer_geoeffnet "Zeigt eine geöffnete Tür an";
CM_ SG_ 2463978728 BT_Tuer_Status "Türstatus mit Fehler und Initwert";
CM_ SG_ 2463978728 BT_Tuer_Status_QBit "Dieses Bit gibt die Zuverlässigkeit des Türkontakts an. Ein auf dieses Bit folgender Fehlereintrag ist mit dem Sender des Bits abzustimmen (gültig ab PPE).";
CM_ SG_ 2463978728 BT_Tueroeffnen_Warnung "Bit wird gesetzt, wenn Tür während der Fahrt geoeffnet werden soll.";
CM_ SG_ 2463978728 BT_Tuerschloss_defekt "Das Beifahrertürschloss ist nicht mehr funktionsfähig.";
CM_ SG_ 2463978728 BT_UEKB_aktiviert "Überschutzbegrenzungskraft bei Reversieren";
CM_ SG_ 2463978728 BT_Unlock_Taster "Entriegelungstaster betätigt";
CM_ SG_ 2463978728 BT_Unten_Block_erw "Fensterheber in Blockerwartung unten";
CM_ SG_ 2463978728 BT_verriegelt "Zeigt eine verriegelte Tür an ( Status wird erst nach vollständiger Schlossansteuerung ausgegeben (<=1,5sek))";
CM_ SG_ 2463978728 BT_Zuziehhilfe_aktiv "Zuziehhilfe aktiv";
CM_ SG_ 2463978728 DoorFunctions_BFS_01_BZ "4bit Botschaftszähler, wird mit jeder Sendebotschaft inkrementiert";
CM_ SG_ 2463978728 DoorFunctions_BFS_01_CRC "Für MLB:
Berechnung siehe Lastenheft 'Kommunikationsabsicherung für FlexRay und CAN'
Ab MQB und MLBevo:
Berechnung siehe Lastenheft 'End-to-End Kommunikationsabsicherung'

Endwerte siehe Begleitdokument 'S-PDU Kennungsfolgen'";
CM_ SG_ 2463978728 eTAB_BFS_Oeffnen_Annaeh "Der Türgriffsensor hat eine Annaeherung zum Oeffnen erkannt.";
CM_ SG_ 2463978728 eTAB_BFS_Oeffnen_Betaet "Der Türgriffsensor hat eine Betaetigung zum Oeffnen erkannt.";
CM_ SG_ 2463978728 eTAB_BFS_Schliessen_Annaeh "Der Türgriffsensor hat eine Annaeherung zum Schliessen erkannt.";
CM_ SG_ 2463978728 eTAB_BFS_Schliessen_Betaet "Der Türgriffsensor hat eine Betaetigung zum Schliessen erkannt.";
CM_ SG_ 2463978728 MTBT_M_Taste "Betätigung M-Taste BT";
CM_ SG_ 2463978728 MTBT_On_Off "Betätigung On-Off Taste BT";
CM_ SG_ 2463978728 MTBT_Pos1 "Betätigung Postionstaste 1 BT";
CM_ SG_ 2463978728 MTBT_Pos2 "Betätigung Postionstaste 2 BT";
CM_ SG_ 2463978728 MTBT_Pos3 "Betätigung Postionstaste 3 BT";
CM_ SG_ 2463978728 MTBT_Pos4 "Betätigung Postionstaste 4 BT";
CM_ SG_ 2463978728 SOK_Doorfunctions_BFS_01_Sign000 "Signatur im Rahmen des SOK.

Geschützte Funktion:	Türfunktionen Beifahrerseite
Geschützte Signale:  	";
CM_ SG_ 2463978728 SSA_BFT_Amb_Bel_Fehler "SmartSensorActor:
Rückmeldung des Fehlerzustand der Ambiente Beleuchtung";
CM_ SG_ 2463978728 SSA_BFT_Amb_Bel_Status "SmartSensorActor:
Rückmeldung des Status der Ambiente Beleuchtung";
CM_ SG_ 2463978728 SSA_BFT_ASP_Heizung_Fehler "SmartSensorActor:
Rückmeldung des Fehlerzustand der Spiegelglasheizung";
CM_ SG_ 2463978728 SSA_BFT_ASP_Klappung_Fehler "SmartSensorActor:
Rückmeldung des Fehlerzustandes der Spiegelklappung Aussenspiegel";
CM_ SG_ 2463978728 SSA_BFT_ASP_Klappung_Status "SmartSensorActor:
Spiegelt die Position und Ansteuerug der Antriebs für die Speigelklappung wieder";
CM_ SG_ 2463978728 SSA_BFT_ASP_Spiegelglas_Fehler "SmartSensorActor:
Rückmeldung des Fehlerzustand der Spiegelglasverstellung auf der Beifahrerseite";
CM_ SG_ 2463978728 SSA_BFT_ASP_Spiegelglas_Pos_Y "SmartSensorActor:
Rückmeldung der Position des Spiegelglases auf der Y-Achse";
CM_ SG_ 2463978728 SSA_BFT_ASW_Fehler "SmartSensorActor:
Rückmeldung des Fehlerzustand des Ausstiegswarners";
CM_ SG_ 2463978728 SSA_BFT_ASW_Status "SmartSensorActor:
Rückmeldung des Status der ASW Anzyeige.";
CM_ SG_ 2463978728 SSA_BFT_el_Tuerantrieb_Fehler "SmartSensorActor:
Rückmeldung des Fehlerzustand des el. Tuerantriebs";
CM_ SG_ 2463978728 SSA_BFT_el_Tuerantrieb_Status "SmartSensorActor:
Rückmeldung des Status des el. Tuerantriebes";
CM_ SG_ 2463978728 SSA_BFT_FH_Bewegungsrichutng "SmartSensorActor:
Rückmeldung der Bewegungsrichtung der Seitenscheibe";
CM_ SG_ 2463978728 SSA_BFT_FH_Fehler "SmartSensorActor:
Rückmeldung des Fehlerzustandes der Fensterheberfunktion";
CM_ SG_ 2463978728 SSA_BFT_FH_Normierung "SmartSensorActor:
Rückmeldung des Normierungszustandes des Fensterhebers";
CM_ SG_ 2463978728 SSA_BFT_FH_Thermoschutz "SmartSensorActor:
Rückmeldung Status Thermoschutz";
CM_ SG_ 2463978728 SSA_BFT_Tuerverschluss_Fehler "SmartSensorActor:
Fehlerzustand der Beifahrertür";
CM_ SG_ 2463978728 SSA_BFT_Tuerverschluss_Status "SmartSensorActor:
Türstatus der Beifahrertür (geschlossen, geöffnet)";
CM_ SG_ 2463978728 SSA_BFT_ZV_Ansteuern "SmartSensorActor:
Kommando zur Ansteuerung des Türschlosses der Beifahrertür";
CM_ SG_ 2463978728 SSA_BFT_ZV_Fehler "SmartSensorActor:
Rückmeldung des Fehlerzustandes des Türschlosses der Beifahrertür";
CM_ SG_ 2463978728 SSA_BFT_ZZH_Fehler "SmartSensorActor:
Rückmeldung des Fehlerzustandes des ZZH Systems";
CM_ SG_ 2463978728 SSA_BFT_ZZH_Status "SmartSensorActor:
Status des ZZH Motors";
CM_ SG_ 2463978728 TSG_FlHz_BFS_FnAbbruchHzKreis_A "Flächenheizung: Status";
CM_ SG_ 2463978728 TSG_FlHz_BFS_FnAbbruchHzKreis_B "Flächenheizung: Status";
CM_ SG_ 2463978728 TSG_FlHz_BFS_NTC_A "Flächenheizung: Temperatur und Fehlerwert des Heizaktors";
CM_ SG_ 2463978728 TSG_FlHz_BFS_NTC_B "Flächenheizung: Temperatur und Fehlerwert des Heizaktors";
CM_ SG_ 2463978728 TSG_FlHz_BFS_Unterbrech_HzK_B "Flächenheizung: Unterbrechungsstatus Heizkreis";

CM_ SG_ 2463978714 ASW_HMI_defekt "HMI Status der Funktion AusstiegsWarnung (ASW). HMI wird durch das TSG angesteuert.";
CM_ SG_ 2463978714 ASW_wakeup "Trigger Start Nachlaufzeit t_1 für die Funktion Ausstieswarnung (ASW)";
CM_ SG_ 2463978714 ASW_Warnung_aktiv_FS "Abschaltung der Ambientefunktion Fahrertür bei aktiver ASW Warnung an der Fahrertür";
CM_ SG_ 2463978714 ASW_Warnung_Aussenlicht_FS_Li "Anzeige Ausstiegwarnung nach aussen, z.B. Heckleuchte";
CM_ SG_ 2463978714 ASW_Warnung_Aussenlicht_FS_Re "Anzeige Ausstiegwarnung nach aussen, z.B. Heckleuchte";
CM_ SG_ 2463978714 DoorFunctions_FS_01_BZ "4bit Botschaftszähler, wird mit jeder Sendebotschaft inkrementiert";
CM_ SG_ 2463978714 DoorFunctions_FS_01_CRC "Für MLB:
Berechnung siehe Lastenheft 'Kommunikationsabsicherung für FlexRay und CAN'
Ab MQB und MLBevo:
Berechnung siehe Lastenheft 'End-to-End Kommunikationsabsicherung'

Endwerte siehe Begleitdokument 'S-PDU Kennungsfolgen'";
CM_ SG_ 2463978714 eTAB_FS_Bowdenzug_Auswerfen "Soll den Bowdenzug für die mechanische Redundanz";
CM_ SG_ 2463978714 eTAB_FS_Oeffnen_Annaeh "Der Türgriffsensor hat eine Annaeherung zum Oeffnen erkannt.";
CM_ SG_ 2463978714 eTAB_FS_Oeffnen_Betaet "Der Türgriffsensor hat eine Betaetigung zum Oeffnen erkannt.";
CM_ SG_ 2463978714 eTAB_FS_Schliessen_Annaeh "Der Türgriffsensor hat eine Annaeherung zum Schliessen erkannt.";
CM_ SG_ 2463978714 eTAB_FS_Schliessen_Betaet "Der Türgriffsensor hat eine Betaetigung zum Schliessen erkannt.";
CM_ SG_ 2463978714 FS_Push_Tuergriff "Push zum Ausfahren der Flush-Tuergriffe";
CM_ SG_ 2463978714 FS_Status_eTAG "Status des elektrischen Tueraussengriffes Fahrertuer";
CM_ SG_ 2463978714 FS_Status_eTAG_ext "erweitert um den Wert 'verfährt'";
CM_ SG_ 2463978714 FT_ASW_Warnton "erzeugt ein Warnton bei AS Warnung";
CM_ SG_ 2463978714 FT_ASW_Warnung_Aussenlicht "zeigt in den Heckleuchte ein Symbol an";
CM_ SG_ 2463978714 FT_BFS_Fond_Freigabe "Freigabe für Fondverstellung";
CM_ SG_ 2463978714 FT_BFS_Tuer_Status "Gesammelte Türstatusbotschaft";
CM_ SG_ 2463978714 FT_Cargolock_bet "CargoLock-Taste betätigt";
CM_ SG_ 2463978714 FT_Daemmglas "Daemmglas verbaut";
CM_ SG_ 2463978714 FT_FH_Bew_hoch "Fensterheber in Bewegung Richtung hoch";
CM_ SG_ 2463978714 FT_FH_Bew_tief "Fensterheber in Bewegung Richtung tief";
CM_ SG_ 2463978714 FT_FH_Block "Fensterscheibe befindet sich im mechanischen Block (oben oder unten)";
CM_ SG_ 2463978714 FT_FH_Fang "Fangbereich ist 4mm von oberer Lippendichtung";
CM_ SG_ 2463978714 FT_FH_normiert "Die Position der Fensterheberscheibe ist bekannt";
CM_ SG_ 2463978714 FT_FH_Oeffnung "Gibt den Fensteröffnungswert in % an.";
CM_ SG_ 2463978714 FT_FH_S_AutoHoch "FH Schalter automatisch hoch gedrückt";
CM_ SG_ 2463978714 FT_FH_S_AutoTief "FH Schalter automatisch tief gedrückt";
CM_ SG_ 2463978714 FT_FH_S_ManHoch "FH Schalter manuell hoch gedrückt";
CM_ SG_ 2463978714 FT_FH_S_ManTief "FH Schalter manuell tief gedrückt";
CM_ SG_ 2463978714 FT_FH_Thermo "gibt an ob Fensterheber im Thermoschutz ist";
CM_ SG_ 2463978714 FT_gesafet "Im Zustand Safe wird auch das Signal FT_verriegelt = 1 gesendet";
CM_ SG_ 2463978714 FT_HBFS_Tuer_Status "Türstatus mit Fehler und Initwert";
CM_ SG_ 2463978714 FT_HD_Taste "Taste in der Fahrertür zum Öffnen des Heckschlosses";
CM_ SG_ 2463978714 FT_HD_Taste_2 "2. HD-Taste im Bedienfeld 
Funktion: Heckdeckel schließen";
CM_ SG_ 2463978714 FT_HD_Taste_auf "2. HD-Taste im Bedienfeld: Heckdeckel oeffnen";
CM_ SG_ 2463978714 FT_HD_Taste_zu "2. HD-Taste im Bedienfeld 
Funktion: Heckdeckel schließen";
CM_ SG_ 2463978714 FT_HFS_Tuer_Status "Türstatus mit Fehler und Initwert";
CM_ SG_ 2463978714 FT_IRUE_Taste "Betätigung IRUE-Taster (Innenraumüberwachung)
MQB: Bei Verbau eines einzelnen Taster zur Deaktivierung von IRUE und NGS wird dieses Signal als Deaktivierungsanforderung beider DWA-Alarmquellen gesendet.";
CM_ SG_ 2463978714 FT_Kisi_Fehler "Fehlerstatus Kindersicherungsfunktion";
CM_ SG_ 2463978714 FT_Kisi_li_aktiv "Aktivierungsstatus der Kindersicherung links";
CM_ SG_ 2463978714 FT_Kisi_re_aktiv "Aktivierungsstatus der Kindersicherung rechts";
CM_ SG_ 2463978714 FT_KiSi_Status_Soll_HBFS "Soll KiSi Status HBFS";
CM_ SG_ 2463978714 FT_KiSi_Status_Soll_HFS "Soll Status der KiSi HFS";
CM_ SG_ 2463978714 FT_Kisi_Taster_li "Linker Kisi Taster betaetigt";
CM_ SG_ 2463978714 FT_Kisi_Taster_li_02 "Der Kindersicherungstaster hinten links aktiv.";
CM_ SG_ 2463978714 FT_Kisi_Taster_re "Rechter Kisi Taster betaetigt";
CM_ SG_ 2463978714 FT_Kisi_Taster_re_02 "Der Kindersicherungstaster hinten rechts aktiv.";
CM_ SG_ 2463978714 FT_Lock_Taster "Verriegelungstaster betätigt";
CM_ SG_ 2463978714 FT_Lock_Unlock_Taster "ZV Funktion Lock Unlock mit Toggle-Logik";
CM_ SG_ 2463978714 FT_Oben_Block_erw "Fensterheber in Blockerwartung oben";
CM_ SG_ 2463978714 FT_Schliesstaster "Vorhalt";
CM_ SG_ 2463978714 FT_Schloss_oeffnen_Ansteuerung "Hier wird die Ansteuerung der  Schlossoeffnung angezeigt. Bei mechanischen Schloessern wird Init gesendet.";
CM_ SG_ 2463978714 FT_Schloss_Status_OeH_Motor "Schossstatus 
Bei Schloss mit frueherem Stand als eSchloss2.0 wird init geschickt";
CM_ SG_ 2463978714 FT_Schluesselschalter_auf "Schlüsselschalter Richtung auf betätigt";
CM_ SG_ 2463978714 FT_SP_ausgerastet "Spiegel ausgerastet";
CM_ SG_ 2463978714 FT_Sp_Blk_def "Blinker am Spiegel defekt";
CM_ SG_ 2463978714 FT_Sp_Heizung_Anf "Kundenanforderung der Außenspiegelheizung Fahrertür";
CM_ SG_ 2463978714 FT_SP_Heizung_ein "Dieses Signal zeigt die tatsächliche Ansteuerung der  Spiegelheizung incl. PWM an. 
Zudem wird aufgrund des Teilnetzbetriebs das Signal zur Ansteuerung der Beifahrer-Spiegelheizung benutzt.

";
CM_ SG_ 2463978714 FT_SP_Heizung_Status "Status der Spiegelheizung";
CM_ SG_ 2463978714 FT_SP_ht_aktiv "Spiegelverstellung in Richtung hoch/tief aktiv";
CM_ SG_ 2463978714 FT_SP_lr_aktiv "Spiegelverstellung in Richtung links/rechts aktiv";
CM_ SG_ 2463978714 FT_Sperrklinke "Vorraste für Schloß

zwischen Vor- und Hauptraste Signal kurz auf 1, danach wieder auf 0 wenn Tür in Hauptraste (Tür ist sicher zu wenn Sperrklinke und Türkontakt auf 0 sind)";
CM_ SG_ 2463978714 FT_SWA_Taster "SWA/ASW Taster Fahrertür";
CM_ SG_ 2463978714 FT_TAG_betaetigt "Türaussengriff

wird nicht im MLB-B8 verwendet";
CM_ SG_ 2463978714 FT_TCR_Mode_aktiv "Signal zeigt eine aktive mechanische Redundanz am Türschloss an.";
CM_ SG_ 2463978714 FT_TD_Taste "Tankdeckelentriegelungs-Taste betätigt";
CM_ SG_ 2463978714 FT_TD_Taste_Fehler "Fehlerstatus des Tankdeckelentriegelungstasters. Wird bei Drucktankkonzepten vom MSG zusammen mit dem Signal FT_TD_Taste ausgewertet, um Tankbereitschaft herzustellen.
Der Fehler beschreibt einen hängenden TD_Taster. Ein Kurzschluss oder Leitungsunterbre";
CM_ SG_ 2463978714 FT_TD_Taste_Status "Status Taste für Tankdeckel";
CM_ SG_ 2463978714 FT_TIG_betaetigt "Türinnengriff

wird nicht im MLB-B8 verwendet";
CM_ SG_ 2463978714 FT_Tuer_geoeffnet "Zeigt eine geöffnete Tür an";
CM_ SG_ 2463978714 FT_Tuer_Status "Tür geöffnet oder Tür geschlossen";
CM_ SG_ 2463978714 FT_Tuer_Status_QBit "Dieses Bit gibt die Zuverlässigkeit des Türkontakts an. Ein auf dieses Bit folgender Fehlereintrag ist mit dem Sender des Bits abzustimmen (gültig ab PPE).";
CM_ SG_ 2463978714 FT_Tueroeffnen_Warnung "Bit wird gesetzt, wenn Tür während der Fahrt geoeffnet werden soll.";
CM_ SG_ 2463978714 FT_Tuerschloss_defekt "Das Fahrertürschloss ist nicht mehr funktionsfähig.";
CM_ SG_ 2463978714 FT_UEKB_aktiviert "Überschutzbegrenzungskraft bei Reversieren";
CM_ SG_ 2463978714 FT_Unlock_Taster "Entriegelungstaster betätigt";
CM_ SG_ 2463978714 FT_Unten_Block_erw "Fensterheber in Blockerwartung unten";
CM_ SG_ 2463978714 FT_verriegelt "Zeigt eine verriegelte Tür an ( Status wird erst nach vollständiger Schlossansteuerung ausgegeben (<=1,5sek))";
CM_ SG_ 2463978714 FT_Zuziehhilfe_aktiv "Zuziehhilfe aktiv";
CM_ SG_ 2463978714 MemFT_Pos1_EE "Betätigung Postionstaste 1 FT";
CM_ SG_ 2463978714 MemFT_Pos2 "Betätigung Postionstaste 2 FT";
CM_ SG_ 2463978714 MemFT_Pos3 "Betätigung Postionstaste 3 FT";
CM_ SG_ 2463978714 MemFT_Pos4 "Betätigung Postionstaste 4 FT";
CM_ SG_ 2463978714 MTFT_M_Taste "Betätigung M-Taste FT";
CM_ SG_ 2463978714 MTFT_On_Off "Betätigung On-Off Taste FT";
CM_ SG_ 2463978714 MTFT_Pos1_EE "Betätigung Postionstaste 1 FT";
CM_ SG_ 2463978714 MTFT_Pos2 "Betätigung Postionstaste 2 FT";
CM_ SG_ 2463978714 MTFT_Pos3 "Betätigung Postionstaste 3 FT";
CM_ SG_ 2463978714 MTFT_Pos4 "Betätigung Postionstaste 4 FT";
CM_ SG_ 2463978714 MTFT_Verst_akt "Mem Taster Verstellung aktiv";
CM_ SG_ 2463978714 SOK_Doorfunctions_FS_01_Signatur "Signatur im Rahmen des SOK.

Geschützte Funktion:	Türfunktionen Fahrerseite
Geschützte Signale:  	";
CM_ SG_ 2463978714 SP_abklappen "Spiegel abklappen";
CM_ SG_ 2463978714 SP_anklappen "Spiegel anklappen";
CM_ SG_ 2463978714 SP_ARA_Status "Rückkanal TSG im ARA-Modus";
CM_ SG_ 2463978714 SP_Auswahl_li "Spiegelschalter in Stellung Auswahl links";
CM_ SG_ 2463978714 SP_Auswahl_re "Spiegelschalter in Stellung Auswahl rechts";
CM_ SG_ 2463978714 SP_Bordsteinfunktion "Bordsteinfunktion Status";
CM_ SG_ 2463978714 SP_BT_links "Spiegel Beifahrertür nach links";
CM_ SG_ 2463978714 SP_BT_oben "Spiegel Beifahrertür nach oben";
CM_ SG_ 2463978714 SP_BT_rechts "Spiegel Beifahrertür nach rechts";
CM_ SG_ 2463978714 SP_BT_unten "Spiegel Beifahrertür nach unten";
CM_ SG_ 2463978714 SP_FT_links "Spiegel Fahrertür nach links";
CM_ SG_ 2463978714 SP_FT_oben "Spiegel Fahrertür nach oben";
CM_ SG_ 2463978714 SP_FT_rechts "Spiegel Fahrertür nach rechts";
CM_ SG_ 2463978714 SP_FT_unten "Spiegel Fahrertür nach unten";
CM_ SG_ 2463978714 SP_Hzg_Taster "Heizungstaster/schalter aktiv";
CM_ SG_ 2463978714 SP_normieren "Spiegel normieren";
CM_ SG_ 2463978714 SP_S_Klappen "Spiegelschalter in Stellung Klappen";
CM_ SG_ 2463978714 SP_S_links "Spiegelschalter in Stellung links";
CM_ SG_ 2463978714 SP_S_oben "Spiegelschalter in Stellung oben";
CM_ SG_ 2463978714 SP_S_rechts "Spiegelschalter in Stellung rechts";
CM_ SG_ 2463978714 SP_S_unten "Spiegelschalter in Stellung unten";
CM_ SG_ 2463978714 SP_Spg_Verstellschalter_Fehler "Erkennung eines hängenden Spiegelverstellschalters";
CM_ SG_ 2463978714 SP_Verstellschalter_Fehler "Erkennung eines hängenden Spiegelverstellschalters";
CM_ SG_ 2463978714 SSA_FT_Amb_Bel_Fehler "SmartSensorActor:
Rückmeldung des Fehlerzustand der Ambiente Beleuchtung";
CM_ SG_ 2463978714 SSA_FT_Amb_Bel_Status "SmartSensorActor:
Rückmeldung des Status der Ambiente Beleuchtung";
CM_ SG_ 2463978714 SSA_FT_ASP_Heizung_Fehler "SmartSensorActor:
Rückmeldung des Fehlerzustand der Spiegelglasheizung";
CM_ SG_ 2463978714 SSA_FT_ASP_Klappung_Fehler "SmartSensorActor:
Rückmeldung des Fehlerzustandes der Spiegelklappung Aussenspiegel";
CM_ SG_ 2463978714 SSA_FT_ASP_Spiegelglas_Fehler "SmartSensorActor:
Rückmeldung des Fehlerzustand der Spiegelglasverstellung auf der Fahrerseite";
CM_ SG_ 2463978714 SSA_FT_ASP_Spiegelglas_Pos_X "SmartSensorActor:
Rückmeldung der Position des Spiegelglases auf der X-Achse";
CM_ SG_ 2463978714 SSA_FT_ASW_Fehler "SmartSensorActor:
Rückmeldung des Fehlerzustand des Ausstiegswarners";
CM_ SG_ 2463978714 SSA_FT_ASW_Status "SmartSensorActor:
Rückmeldung des Status der ASW Anzeige.";
CM_ SG_ 2463978714 SSA_FT_el_Tuerantrieb_Fehler "SmartSensorActor:
Rückmeldung des Fehlerzustand des el. Tuerantriebs";
CM_ SG_ 2463978714 SSA_FT_el_Tuerantrieb_Status "SmartSensorActor:
Rückmeldung des Status des el. Tuerantriebes";
CM_ SG_ 2463978714 SSA_FT_FH_Bewegungsrichutng "SmartSensorActor:
Rückmeldung der Bewegungsrichtung der Seitenscheibe";
CM_ SG_ 2463978714 SSA_FT_FH_Fehler "SmartSensorActor:
Rückmeldung des Fehlerzustandes der Fensterheberfunktion";
CM_ SG_ 2463978714 SSA_FT_FH_Normierung "SmartSensorActor:
Rückmeldung des Normierungszustandes des Fensterhebers";
CM_ SG_ 2463978714 SSA_FT_FH_Thermoschutz "SmartSensorActor:
Rückmeldung Status Thermoschutz";
CM_ SG_ 2463978714 SSA_FT_Tuerverschluss_Fehler "SmartSensorActor:
Fehlerzustand der Fahrertür";
CM_ SG_ 2463978714 SSA_FT_Tuerverschluss_Status "SmartSensorActor:
Türstatus der Fahrertür (geschlossen, geöffnet)";
CM_ SG_ 2463978714 SSA_FT_ZV_Fehler "SmartSensorActor:
Rückmeldung des Fehlerzustandes des Türschlosses der Fahrertür";
CM_ SG_ 2463978714 SSA_FT_ZV_Status "SmartSensorActor:
Zustand des Türschlosses der Fahrertür";
CM_ SG_ 2463978714 SSA_FT_ZZH_Fehler "SmartSensorActor:
Rückmeldung des Fehlerzustandes des ZZH Systems";
CM_ SG_ 2463978714 SSA_FT_ZZH_Status "SmartSensorActor:
Status des ZZH Motors";
CM_ SG_ 2463978714 SSR_Temp_Freigabe "Freigabe des Seitenscheibenrollos. Bit wird  für die Deaktivierung des SSR bei Innenraumtemperaturen kleiner -10 Grad verwendet.";
CM_ SG_ 2463978714 SWA_HMI_Diagnose "SWA HMI Diagnose beim TSG";
CM_ SG_ 2463978714 TBF_FS_Touch_Event "Touch_Events für Informationen einer Funktionsauslösung auf dem TBF, welche dann für bspw. ein akustisches Signal zentral umgesetzt werden können.";
CM_ SG_ 2463978714 TSG_FlHz_FS_FnAbbruchHzKreis_A "Flächenheizung: Status";
CM_ SG_ 2463978714 TSG_FlHz_FS_FnAbbruchHzKreis_B "Flächenheizung: Status";
CM_ SG_ 2463978714 TSG_FlHz_FS_NTC_A "Flächenheizung: Temperatur und Fehlerwert des Heizaktors";
CM_ SG_ 2463978714 TSG_FlHz_FS_NTC_B "Flächenheizung: Temperatur und Fehlerwert des Heizaktors";
CM_ SG_ 2463978714 TSG_FlHz_FS_Unterbrech_HzK_A "Flächenheizung: Unterbrechungsstatus Heizkreis";
CM_ SG_ 2463978714 TSG_FlHz_FS_Unterbrech_HzK_B "Flächenheizung: Unterbrechungsstatus Heizkreis";
CM_ SG_ 2463978714 TSG_FS_Spiegel_angeklappt "Funktionsrückmeldung TSG_FS über Spiegelstellung angeklappt";
BA_DEF_REL_ BU_SG_REL_  "GenSigTimeoutTime" INT 0 65535;
BA_DEF_ BO_  "DiagRequest" ENUM "No", "Yes";
BA_DEF_ BO_  "DiagResponse" ENUM "No", "Yes";
BA_DEF_ BO_  "DiagState" ENUM "No", "Yes";
BA_DEF_ BO_  "GenMsgChkConstant" HEX 0 4095;
BA_DEF_ BO_  "GenMsgCycleTime" INT 0 65535;
BA_DEF_ BO_  "GenMsgCycleTimeFast" INT 0 65535;
BA_DEF_ BO_  "GenMsgDelayTime" INT 0 100000;
BA_DEF_ BO_  "GenMsgILSupport" ENUM "No", "Yes";
BA_DEF_ BO_  "GenMsgNrOfRepetition" INT 0 100;
BA_DEF_ BO_  "GenMsgPDUConstants" STRING;
BA_DEF_ BO_  "GenMsgSendType" ENUM "Cyclic", "not_used", "not_used", "not_used", "not_used", "not_used", "not_used", "IfActive", "NoMsgSendType";
BA_DEF_ BO_  "GenMsgStartDelayTime" INT 0 100000;
BA_DEF_ BO_  "NmMessage" ENUM "No", "Yes";
BA_DEF_ BO_  "NmhMessage" ENUM "No", "Yes";
BA_DEF_ BO_  "MsgType" ENUM "Application", "NM ", "NMH", "TP2.0", "ISO-TP ", "BAP", "EID", "KS", "XCP_PRE_CONFIGURED", "XCP_RUNTIME_CONFIGURED";
BA_DEF_ BO_  "VAGTP20_API" HEX 0 255;
BA_DEF_ BO_  "VAGTP20_DynConnection" ENUM "No", "Yes";
BA_DEF_ BO_  "VAGTP20_DynSetup" ENUM "No", "Yes";
BA_DEF_ BO_  "VAGTP20_StatConnection" ENUM "No", "Yes";
BA_DEF_ BO_  "CANFD_BRS" ENUM "0", "1";
BA_DEF_ BO_  "VFrameFormat" ENUM "StandardCAN", "ExtendedCAN", "reserved", "reserved", "reserved", "reserved", "reserved", "reserved", "reserved", "reserved", "reserved", "reserved", "reserved", "reserved", "StandardCAN_FD", "ExtendedCAN_FD";
BA_DEF_ SG_  "GenSigActiveRepetitions" INT -2147483648 2147483647;
BA_DEF_ SG_  "GenSigInactiveValue" INT -2147483648 2147483647;
BA_DEF_ SG_  "GenSigSendType" ENUM "Cyclic", "OnWrite", "OnWriteWithRepetition", "OnChange", "OnChangeWithRepetition", "IfActive", "IfActiveWithRepetition", "NoSigSendType", "OnChangeAndIfActive", "OnChangeAndIfActiveWithRepetition";
BA_DEF_ SG_  "GenSigStartValue" INT -2147483648 2147483647;
BA_DEF_ SG_  "NWM-WakeupAllowed" ENUM "No", "Yes";
BA_DEF_ SG_  "GenSigFuncType" ENUM "NoFunction", "MsgCounter", "CRC-8", "XOR", "XOR-2", "DatedBit", "SW-Kl15", "CHK", "Constant", "Protocol", "CRC-8-SAE_J1850", "CRC-32", "DataLength", "DataID", "MsgCounter16", "SOK-Signatur", "Cluster";
BA_DEF_ SG_  "GenSigSwitchedByIgnition" ENUM "No", "Yes";
BA_DEF_ SG_  "Fehlerwert" HEX 0 2147483647;
BA_DEF_ SG_  "GenSigMissingSourceValue" HEX 0 2147483647;
BA_DEF_DEF_REL_  "GenSigTimeoutTime" 0;
BA_DEF_DEF_  "DiagRequest" "No";
BA_DEF_DEF_  "DiagResponse" "No";
BA_DEF_DEF_  "DiagState" "No";
BA_DEF_DEF_  "GenMsgChkConstant" 0;
BA_DEF_DEF_  "GenMsgCycleTime" 0;
BA_DEF_DEF_  "GenMsgCycleTimeFast" 0;
BA_DEF_DEF_  "GenMsgDelayTime" 0;
BA_DEF_DEF_  "GenMsgILSupport" "No";
BA_DEF_DEF_  "GenMsgNrOfRepetition" 0;
BA_DEF_DEF_  "GenMsgPDUConstants" "";
BA_DEF_DEF_  "GenMsgSendType" "NoMsgSendType";
BA_DEF_DEF_  "GenMsgStartDelayTime" 0;
BA_DEF_DEF_  "NmMessage" "No";
BA_DEF_DEF_  "NmhMessage" "No";
BA_DEF_DEF_  "MsgType" "Application";
BA_DEF_DEF_  "VAGTP20_API" 0;
BA_DEF_DEF_  "VAGTP20_DynConnection" "No";
BA_DEF_DEF_  "VAGTP20_DynSetup" "No";
BA_DEF_DEF_  "VAGTP20_StatConnection" "No";
BA_DEF_DEF_  "CANFD_BRS" "1";
BA_DEF_DEF_  "VFrameFormat" "StandardCAN";
BA_DEF_DEF_  "GenSigActiveRepetitions" 0;
BA_DEF_DEF_  "GenSigInactiveValue" 0;
BA_DEF_DEF_  "GenSigSendType" "NoSigSendType";
BA_DEF_DEF_  "GenSigStartValue" 0;
BA_DEF_DEF_  "NWM-WakeupAllowed" "No";
BA_DEF_DEF_  "GenSigFuncType" "NoFunction";
BA_DEF_DEF_  "GenSigSwitchedByIgnition" "Yes";
BA_DEF_DEF_  "Fehlerwert" 0;
BA_DEF_DEF_  "GenSigMissingSourceValue" 0;
BA_ "DiagResponse" BO_ 2621577104 1;
BA_ "MsgType" BO_ 2621577104 4;
BA_ "CANFD_BRS" BO_ 2621577104 0;
BA_ "VFrameFormat" BO_ 2621577104 15;
BA_ "DiagRequest" BO_ 2549880398 1;
BA_ "MsgType" BO_ 2549880398 4;
BA_ "CANFD_BRS" BO_ 2549880398 0;
BA_ "VFrameFormat" BO_ 2549880398 15;
BA_ "DiagRequest" BO_ 2621445710 1;
BA_ "MsgType" BO_ 2621445710 4;
BA_ "CANFD_BRS" BO_ 2621445710 0;
BA_ "VFrameFormat" BO_ 2621445710 15;
BA_ "DiagResponse" BO_ 2550011470 1;
BA_ "MsgType" BO_ 2550011470 4;
BA_ "CANFD_BRS" BO_ 2550011470 0;
BA_ "VFrameFormat" BO_ 2550011470 15;
BA_ "DiagResponse" BO_ 2621576782 1;
BA_ "MsgType" BO_ 2621576782 4;
BA_ "CANFD_BRS" BO_ 2621576782 0;
BA_ "VFrameFormat" BO_ 2621576782 15;
BA_ "DiagRequest" BO_ 2549880679 1;
BA_ "MsgType" BO_ 2549880679 4;
BA_ "CANFD_BRS" BO_ 2549880679 0;
BA_ "VFrameFormat" BO_ 2549880679 15;
BA_ "DiagResponse" BO_ 2550011751 1;
BA_ "MsgType" BO_ 2550011751 4;
BA_ "CANFD_BRS" BO_ 2550011751 0;
BA_ "VFrameFormat" BO_ 2550011751 15;
BA_ "DiagRequest" BO_ 2549880680 1;
BA_ "MsgType" BO_ 2549880680 4;
BA_ "CANFD_BRS" BO_ 2549880680 0;
BA_ "VFrameFormat" BO_ 2549880680 15;
BA_ "DiagResponse" BO_ 2550011752 1;
BA_ "MsgType" BO_ 2550011752 4;
BA_ "CANFD_BRS" BO_ 2550011752 0;
BA_ "VFrameFormat" BO_ 2550011752 15;
BA_ "DiagRequest" BO_ 2549880321 1;
BA_ "MsgType" BO_ 2549880321 4;
BA_ "CANFD_BRS" BO_ 2549880321 0;
BA_ "VFrameFormat" BO_ 2549880321 15;
BA_ "DiagRequest" BO_ 2621445633 1;
BA_ "MsgType" BO_ 2621445633 4;
BA_ "CANFD_BRS" BO_ 2621445633 0;
BA_ "VFrameFormat" BO_ 2621445633 15;
BA_ "DiagResponse" BO_ 2550011393 1;
BA_ "MsgType" BO_ 2550011393 4;
BA_ "CANFD_BRS" BO_ 2550011393 0;
BA_ "VFrameFormat" BO_ 2550011393 15;
BA_ "DiagResponse" BO_ 2621576705 1;
BA_ "MsgType" BO_ 2621576705 4;
BA_ "CANFD_BRS" BO_ 2621576705 0;
BA_ "VFrameFormat" BO_ 2621576705 15;
BA_ "GenMsgCycleTime" BO_ 1714 1000;
BA_ "GenMsgILSupport" BO_ 1714 1;
BA_ "GenMsgSendType" BO_ 1714 0;
BA_ "CANFD_BRS" BO_ 1714 0;
BA_ "VFrameFormat" BO_ 1714 14;
BA_ "GenMsgCycleTime" BO_ 851 80;
BA_ "GenMsgILSupport" BO_ 851 1;
BA_ "GenMsgPDUConstants" BO_ 851 "0x3a,0x97,0x6b,0x70,0x1e,0x84,0xe1,0xb4,0xde,0xb8,0x03,0xe7,0x33,0x20,0x3f,0x7c";
BA_ "GenMsgSendType" BO_ 851 0;
BA_ "CANFD_BRS" BO_ 851 0;
BA_ "VFrameFormat" BO_ 851 14;
BA_ "GenMsgCycleTime" BO_ 1520 200;
BA_ "GenMsgDelayTime" BO_ 1520 50;
BA_ "GenMsgILSupport" BO_ 1520 1;
BA_ "GenMsgSendType" BO_ 1520 0;
BA_ "CANFD_BRS" BO_ 1520 0;
BA_ "VFrameFormat" BO_ 1520 14;
BA_ "GenMsgCycleTime" BO_ 2463978728 100;
BA_ "GenMsgCycleTimeFast" BO_ 2463978728 20;
BA_ "GenMsgDelayTime" BO_ 2463978728 20;
BA_ "GenMsgILSupport" BO_ 2463978728 1;
BA_ "GenMsgNrOfRepetition" BO_ 2463978728 10;
BA_ "GenMsgPDUConstants" BO_ 2463978728 "0x79,0xdb,0x11,0x86,0xb6,0x29,0x9c,0x0d,0xdc,0x1c,0x4a,0xbd,0xb8,0x2d,0xc1,0xab";
BA_ "GenMsgSendType" BO_ 2463978728 0;
BA_ "CANFD_BRS" BO_ 2463978728 0;
BA_ "VFrameFormat" BO_ 2463978728 15;
BA_ "GenMsgCycleTime" BO_ 2463978714 100;
BA_ "GenMsgCycleTimeFast" BO_ 2463978714 20;
BA_ "GenMsgDelayTime" BO_ 2463978714 20;
BA_ "GenMsgILSupport" BO_ 2463978714 1;
BA_ "GenMsgNrOfRepetition" BO_ 2463978714 10;
BA_ "GenMsgPDUConstants" BO_ 2463978714 "0xe0,0x30,0x5a,0xf5,0xe6,0x04,0x6b,0x10,0xdb,0x58,0x21,0x4c,0x7c,0x3e,0xed,0xaa";
BA_ "GenMsgSendType" BO_ 2463978714 0;
BA_ "CANFD_BRS" BO_ 2463978714 0;
BA_ "VFrameFormat" BO_ 2463978714 15;
BA_ "GenSigSendType" SG_ 2621577104 DIA_VIP_HFS_Resp_FD_Data 3;
BA_ "GenSigFuncType" SG_ 2621577104 DIA_VIP_HFS_Resp_FD_Data 9;
BA_ "GenSigSwitchedByIgnition" SG_ 2621577104 DIA_VIP_HFS_Resp_FD_Data 0;
BA_ "GenSigSendType" SG_ 2549880398 DIA_VIP_Req_Data 3;
BA_ "GenSigFuncType" SG_ 2549880398 DIA_VIP_Req_Data 9;
BA_ "GenSigSwitchedByIgnition" SG_ 2549880398 DIA_VIP_Req_Data 0;
BA_ "GenSigSendType" SG_ 2621445710 DIA_VIP_Req_FD_Data 3;
BA_ "GenSigFuncType" SG_ 2621445710 DIA_VIP_Req_FD_Data 9;
BA_ "GenSigSwitchedByIgnition" SG_ 2621445710 DIA_VIP_Req_FD_Data 0;
BA_ "GenSigSendType" SG_ 2550011470 DIA_VIP_Resp_Data 3;
BA_ "GenSigFuncType" SG_ 2550011470 DIA_VIP_Resp_Data 9;
BA_ "GenSigSwitchedByIgnition" SG_ 2550011470 DIA_VIP_Resp_Data 0;
BA_ "GenSigSendType" SG_ 2621576782 DIA_VIP_Resp_FD_Data 3;
BA_ "GenSigFuncType" SG_ 2621576782 DIA_VIP_Resp_FD_Data 9;
BA_ "GenSigSwitchedByIgnition" SG_ 2621576782 DIA_VIP_Resp_FD_Data 0;
BA_ "GenSigSendType" SG_ 2549880679 DIA_WiBli_L_Req 3;
BA_ "GenSigFuncType" SG_ 2549880679 DIA_WiBli_L_Req 9;
BA_ "GenSigSwitchedByIgnition" SG_ 2549880679 DIA_WiBli_L_Req 0;
BA_ "GenSigSendType" SG_ 2550011751 DIA_WiBli_L_Resp 3;
BA_ "GenSigFuncType" SG_ 2550011751 DIA_WiBli_L_Resp 9;
BA_ "GenSigSwitchedByIgnition" SG_ 2550011751 DIA_WiBli_L_Resp 0;
BA_ "GenSigSendType" SG_ 2549880680 DIA_WiBli_R_Req 3;
BA_ "GenSigFuncType" SG_ 2549880680 DIA_WiBli_R_Req 9;
BA_ "GenSigSwitchedByIgnition" SG_ 2549880680 DIA_WiBli_R_Req 0;
BA_ "GenSigSendType" SG_ 2550011752 DIA_WiBli_R_Resp 3;
BA_ "GenSigFuncType" SG_ 2550011752 DIA_WiBli_R_Resp 9;
BA_ "GenSigSwitchedByIgnition" SG_ 2550011752 DIA_WiBli_R_Resp 0;
BA_ "GenSigSendType" SG_ 2549880321 DIA_WWS_Req_Data 3;
BA_ "GenSigFuncType" SG_ 2549880321 DIA_WWS_Req_Data 9;
BA_ "GenSigSwitchedByIgnition" SG_ 2549880321 DIA_WWS_Req_Data 0;
BA_ "GenSigSendType" SG_ 2621445633 DIA_WWS_Req_FD_Data 3;
BA_ "GenSigFuncType" SG_ 2621445633 DIA_WWS_Req_FD_Data 9;
BA_ "GenSigSwitchedByIgnition" SG_ 2621445633 DIA_WWS_Req_FD_Data 0;
BA_ "GenSigSendType" SG_ 2550011393 DIA_WWS_Resp_Data 3;
BA_ "GenSigFuncType" SG_ 2550011393 DIA_WWS_Resp_Data 9;
BA_ "GenSigSwitchedByIgnition" SG_ 2550011393 DIA_WWS_Resp_Data 0;
BA_ "GenSigSendType" SG_ 2621576705 DIA_WWS_Resp_FD_Data 3;
BA_ "GenSigFuncType" SG_ 2621576705 DIA_WWS_Resp_FD_Data 9;
BA_ "GenSigSwitchedByIgnition" SG_ 2621576705 DIA_WWS_Resp_FD_Data 0;
BA_ "GenSigSendType" SG_ 1714 DGN_Verlernzaehler 0;
BA_ "GenSigSwitchedByIgnition" SG_ 1714 DGN_Verlernzaehler 0;
BA_ "GenSigSendType" SG_ 1714 KBI_Kilometerstand 0;
BA_ "GenSigStartValue" SG_ 1714 KBI_Kilometerstand 1048574;
BA_ "GenSigSwitchedByIgnition" SG_ 1714 KBI_Kilometerstand 0;
BA_ "Fehlerwert" SG_ 1714 KBI_Kilometerstand 1048575;
BA_ "GenSigSendType" SG_ 1714 Kombi_02_alt 0;
BA_ "GenSigStartValue" SG_ 1714 Kombi_02_alt 1;
BA_ "GenSigFuncType" SG_ 1714 Kombi_02_alt 5;
BA_ "GenSigSwitchedByIgnition" SG_ 1714 Kombi_02_alt 0;
BA_ "GenSigSendType" SG_ 1714 UH_Jahr 0;
BA_ "GenSigSwitchedByIgnition" SG_ 1714 UH_Jahr 0;
BA_ "GenSigSendType" SG_ 1714 UH_Minute 0;
BA_ "GenSigSwitchedByIgnition" SG_ 1714 UH_Minute 0;
BA_ "GenSigSendType" SG_ 1714 UH_Monat 0;
BA_ "GenSigSwitchedByIgnition" SG_ 1714 UH_Monat 0;
BA_ "Fehlerwert" SG_ 1714 UH_Monat 15;
BA_ "GenSigSendType" SG_ 1714 UH_Sekunde 0;
BA_ "GenSigSwitchedByIgnition" SG_ 1714 UH_Sekunde 0;
BA_ "GenSigSendType" SG_ 1714 UH_Stunde 0;
BA_ "GenSigSwitchedByIgnition" SG_ 1714 UH_Stunde 0;
BA_ "GenSigSendType" SG_ 1714 UH_Tag 0;
BA_ "GenSigSwitchedByIgnition" SG_ 1714 UH_Tag 0;
BA_ "GenSigSendType" SG_ 1714 Uhrzeit_01_alt 0;
BA_ "GenSigStartValue" SG_ 1714 Uhrzeit_01_alt 1;
BA_ "GenSigFuncType" SG_ 1714 Uhrzeit_01_alt 5;
BA_ "GenSigSwitchedByIgnition" SG_ 1714 Uhrzeit_01_alt 0;
BA_ "GenSigSendType" SG_ 1714 Vehicle_Driving_Cycle 0;
BA_ "GenSigSwitchedByIgnition" SG_ 1714 Vehicle_Driving_Cycle 0;
BA_ "GenSigSendType" SG_ 851 DiETa_Car 0;
BA_ "GenSigSwitchedByIgnition" SG_ 851 DiETa_Car 0;
BA_ "Fehlerwert" SG_ 851 DiETa_Car 3;
BA_ "GenSigSendType" SG_ 851 DiETa_Defrost_Taste 0;
BA_ "GenSigSwitchedByIgnition" SG_ 851 DiETa_Defrost_Taste 0;
BA_ "Fehlerwert" SG_ 851 DiETa_Defrost_Taste 3;
BA_ "GenSigSendType" SG_ 851 DiETa_FAS_Stufe 0;
BA_ "GenSigSwitchedByIgnition" SG_ 851 DiETa_FAS_Stufe 0;
BA_ "Fehlerwert" SG_ 851 DiETa_FAS_Stufe 3;
BA_ "GenSigSendType" SG_ 851 DiETa_FSH_Taste 0;
BA_ "GenSigSwitchedByIgnition" SG_ 851 DiETa_FSH_Taste 0;
BA_ "Fehlerwert" SG_ 851 DiETa_FSH_Taste 3;
BA_ "GenSigSendType" SG_ 851 DiETa_HSH_Taste 0;
BA_ "GenSigSwitchedByIgnition" SG_ 851 DiETa_HSH_Taste 0;
BA_ "Fehlerwert" SG_ 851 DiETa_HSH_Taste 3;
BA_ "GenSigSendType" SG_ 851 DiETa_Klima 0;
BA_ "GenSigSwitchedByIgnition" SG_ 851 DiETa_Klima 0;
BA_ "Fehlerwert" SG_ 851 DiETa_Klima 3;
BA_ "GenSigSendType" SG_ 851 DiETa_Lock_Unlock_Taste 0;
BA_ "GenSigSwitchedByIgnition" SG_ 851 DiETa_Lock_Unlock_Taste 0;
BA_ "Fehlerwert" SG_ 851 DiETa_Lock_Unlock_Taste 7;
BA_ "GenSigSendType" SG_ 851 DiETa_Mode 0;
BA_ "GenSigSwitchedByIgnition" SG_ 851 DiETa_Mode 0;
BA_ "Fehlerwert" SG_ 851 DiETa_Mode 3;
BA_ "GenSigSendType" SG_ 851 DiETa_Mode2 0;
BA_ "GenSigSwitchedByIgnition" SG_ 851 DiETa_Mode2 0;
BA_ "Fehlerwert" SG_ 851 DiETa_Mode2 3;
BA_ "GenSigSendType" SG_ 851 DiETa_Mode_roh 0;
BA_ "GenSigSwitchedByIgnition" SG_ 851 DiETa_Mode_roh 0;
BA_ "GenSigSendType" SG_ 851 DiETa_PAO_OFF_Status 0;
BA_ "GenSigSwitchedByIgnition" SG_ 851 DiETa_PAO_OFF_Status 0;
BA_ "GenSigSendType" SG_ 851 DiETa_PAO_ON_Status 0;
BA_ "GenSigSwitchedByIgnition" SG_ 851 DiETa_PAO_ON_Status 0;
BA_ "GenSigSendType" SG_ 851 DiETa_Parken 0;
BA_ "GenSigSwitchedByIgnition" SG_ 851 DiETa_Parken 0;
BA_ "Fehlerwert" SG_ 851 DiETa_Parken 3;
BA_ "GenSigSendType" SG_ 851 DiETa_Reserve_Byte2_4 0;
BA_ "GenSigSwitchedByIgnition" SG_ 851 DiETa_Reserve_Byte2_4 0;
BA_ "GenSigSendType" SG_ 851 DiETa_Reserve_Byte6_6 0;
BA_ "GenSigSwitchedByIgnition" SG_ 851 DiETa_Reserve_Byte6_6 0;
BA_ "GenSigSendType" SG_ 851 DiETa_Reserve_Byte7_4 0;
BA_ "GenSigSwitchedByIgnition" SG_ 851 DiETa_Reserve_Byte7_4 0;
BA_ "GenSigSendType" SG_ 851 DiETa_Reserve_Byte8 0;
BA_ "GenSigSwitchedByIgnition" SG_ 851 DiETa_Reserve_Byte8 0;
BA_ "GenSigSendType" SG_ 851 DiETa_ResponseError 0;
BA_ "GenSigSwitchedByIgnition" SG_ 851 DiETa_ResponseError 0;
BA_ "Fehlerwert" SG_ 851 DiETa_ResponseError 1;
BA_ "GenSigSendType" SG_ 851 DiETa_Status 0;
BA_ "GenSigStartValue" SG_ 851 DiETa_Status 2;
BA_ "GenSigSwitchedByIgnition" SG_ 851 DiETa_Status 0;
BA_ "GenSigSendType" SG_ 851 DiETa_Touch_Event 0;
BA_ "GenSigSwitchedByIgnition" SG_ 851 DiETa_Touch_Event 0;
BA_ "Fehlerwert" SG_ 851 DiETa_Touch_Event 15;
BA_ "GenSigSendType" SG_ 851 DiETa_Warnblink_Taste 0;
BA_ "GenSigSwitchedByIgnition" SG_ 851 DiETa_Warnblink_Taste 0;
BA_ "Fehlerwert" SG_ 851 DiETa_Warnblink_Taste 3;
BA_ "GenSigSendType" SG_ 851 DiETas_01_BZ 0;
BA_ "GenSigFuncType" SG_ 851 DiETas_01_BZ 1;
BA_ "GenSigSwitchedByIgnition" SG_ 851 DiETas_01_BZ 0;
BA_ "GenSigSendType" SG_ 851 DiETas_01_CRC 0;
BA_ "GenSigFuncType" SG_ 851 DiETas_01_CRC 2;
BA_ "GenSigSwitchedByIgnition" SG_ 851 DiETas_01_CRC 0;
BA_ "GenSigSendType" SG_ 851 ESP_Off_Taster 0;
BA_ "GenSigStartValue" SG_ 851 ESP_Off_Taster 2;
BA_ "GenSigSwitchedByIgnition" SG_ 851 ESP_Off_Taster 0;
BA_ "Fehlerwert" SG_ 851 ESP_Off_Taster 3;
BA_ "GenSigSendType" SG_ 1520 BCM1_Stellgroesse_Kl_58s 3;
BA_ "GenSigStartValue" SG_ 1520 BCM1_Stellgroesse_Kl_58s 126;
BA_ "GenSigSwitchedByIgnition" SG_ 1520 BCM1_Stellgroesse_Kl_58s 0;
BA_ "Fehlerwert" SG_ 1520 BCM1_Stellgroesse_Kl_58s 127;
BA_ "GenSigSendType" SG_ 1520 DI_Display_Nachtdesign 3;
BA_ "GenSigSwitchedByIgnition" SG_ 1520 DI_Display_Nachtdesign 0;
BA_ "GenSigSendType" SG_ 1520 DI_Fotosensor 3;
BA_ "GenSigSwitchedByIgnition" SG_ 1520 DI_Fotosensor 0;
BA_ "GenSigSendType" SG_ 1520 DI_KL_58xd 3;
BA_ "GenSigStartValue" SG_ 1520 DI_KL_58xd 254;
BA_ "GenSigSwitchedByIgnition" SG_ 1520 DI_KL_58xd 0;
BA_ "Fehlerwert" SG_ 1520 DI_KL_58xd 255;
BA_ "GenSigSendType" SG_ 1520 DI_KL_58xs 3;
BA_ "GenSigStartValue" SG_ 1520 DI_KL_58xs 126;
BA_ "GenSigSwitchedByIgnition" SG_ 1520 DI_KL_58xs 0;
BA_ "Fehlerwert" SG_ 1520 DI_KL_58xs 127;
BA_ "GenSigSendType" SG_ 1520 DI_KL_58xt 3;
BA_ "GenSigStartValue" SG_ 1520 DI_KL_58xt 126;
BA_ "GenSigSwitchedByIgnition" SG_ 1520 DI_KL_58xt 0;
BA_ "Fehlerwert" SG_ 1520 DI_KL_58xt 127;
BA_ "GenSigSendType" SG_ 2463978728 ASW_Warnung_aktiv_BFS 3;
BA_ "GenSigSwitchedByIgnition" SG_ 2463978728 ASW_Warnung_aktiv_BFS 0;
BA_ "GenSigSendType" SG_ 2463978728 ASW_Warnung_Aussenlicht_BFS_Li 3;
BA_ "GenSigSwitchedByIgnition" SG_ 2463978728 ASW_Warnung_Aussenlicht_BFS_Li 0;
BA_ "GenSigSendType" SG_ 2463978728 ASW_Warnung_Aussenlicht_BFS_Re 3;
BA_ "GenSigSwitchedByIgnition" SG_ 2463978728 ASW_Warnung_Aussenlicht_BFS_Re 0;
BA_ "GenSigSendType" SG_ 2463978728 BFS_Push_Tuergriff 3;
BA_ "GenSigSwitchedByIgnition" SG_ 2463978728 BFS_Push_Tuergriff 0;
BA_ "GenSigSendType" SG_ 2463978728 BFS_Status_eTAG 3;
BA_ "GenSigSwitchedByIgnition" SG_ 2463978728 BFS_Status_eTAG 0;
BA_ "Fehlerwert" SG_ 2463978728 BFS_Status_eTAG 3;
BA_ "GenSigSendType" SG_ 2463978728 BFS_Status_eTAG_ext 3;
BA_ "GenSigStartValue" SG_ 2463978728 BFS_Status_eTAG_ext 3;
BA_ "GenSigSwitchedByIgnition" SG_ 2463978728 BFS_Status_eTAG_ext 0;
BA_ "Fehlerwert" SG_ 2463978728 BFS_Status_eTAG_ext 4;
BA_ "GenSigSendType" SG_ 2463978728 BFT_HSK_Taste 4;
BA_ "GenSigSwitchedByIgnition" SG_ 2463978728 BFT_HSK_Taste 0;
BA_ "GenSigSendType" SG_ 2463978728 BT_ASW_HMI_defekt 0;
BA_ "GenSigSwitchedByIgnition" SG_ 2463978728 BT_ASW_HMI_defekt 0;
BA_ "GenSigSendType" SG_ 2463978728 BT_ASW_Warnton 3;
BA_ "GenSigSwitchedByIgnition" SG_ 2463978728 BT_ASW_Warnton 0;
BA_ "Fehlerwert" SG_ 2463978728 BT_ASW_Warnton 3;
BA_ "GenSigSendType" SG_ 2463978728 BT_ASW_Warnung_Aussenlicht 3;
BA_ "GenSigSwitchedByIgnition" SG_ 2463978728 BT_ASW_Warnung_Aussenlicht 0;
BA_ "Fehlerwert" SG_ 2463978728 BT_ASW_Warnung_Aussenlicht 3;
BA_ "GenSigSendType" SG_ 2463978728 BT_EC_Spiegel_Helligkeit 3;
BA_ "GenSigSwitchedByIgnition" SG_ 2463978728 BT_EC_Spiegel_Helligkeit 0;
BA_ "GenSigSendType" SG_ 2463978728 BT_FH_Bew_hoch 9;
BA_ "GenSigSwitchedByIgnition" SG_ 2463978728 BT_FH_Bew_hoch 0;
BA_ "GenSigSendType" SG_ 2463978728 BT_FH_Bew_tief 9;
BA_ "GenSigSwitchedByIgnition" SG_ 2463978728 BT_FH_Bew_tief 0;
BA_ "GenSigSendType" SG_ 2463978728 BT_FH_Block 9;
BA_ "GenSigSwitchedByIgnition" SG_ 2463978728 BT_FH_Block 0;
BA_ "GenSigSendType" SG_ 2463978728 BT_FH_Fang 9;
BA_ "GenSigSwitchedByIgnition" SG_ 2463978728 BT_FH_Fang 0;
BA_ "GenSigSendType" SG_ 2463978728 BT_FH_normiert 9;
BA_ "GenSigSwitchedByIgnition" SG_ 2463978728 BT_FH_normiert 0;
BA_ "GenSigSendType" SG_ 2463978728 BT_FH_Oeffnung 9;
BA_ "GenSigSwitchedByIgnition" SG_ 2463978728 BT_FH_Oeffnung 0;
BA_ "GenSigSendType" SG_ 2463978728 BT_FH_Pos_oben 9;
BA_ "GenSigSwitchedByIgnition" SG_ 2463978728 BT_FH_Pos_oben 0;
BA_ "GenSigSendType" SG_ 2463978728 BT_FH_S_AutoHoch 9;
BA_ "GenSigSwitchedByIgnition" SG_ 2463978728 BT_FH_S_AutoHoch 0;
BA_ "GenSigSendType" SG_ 2463978728 BT_FH_S_AutoTief 9;
BA_ "GenSigSwitchedByIgnition" SG_ 2463978728 BT_FH_S_AutoTief 0;
BA_ "GenSigSendType" SG_ 2463978728 BT_FH_S_ManHoch 9;
BA_ "GenSigSwitchedByIgnition" SG_ 2463978728 BT_FH_S_ManHoch 0;
BA_ "GenSigSendType" SG_ 2463978728 BT_FH_S_ManTief 9;
BA_ "GenSigSwitchedByIgnition" SG_ 2463978728 BT_FH_S_ManTief 0;
BA_ "GenSigSendType" SG_ 2463978728 BT_FH_Thermo 9;
BA_ "GenSigSwitchedByIgnition" SG_ 2463978728 BT_FH_Thermo 0;
BA_ "GenSigSendType" SG_ 2463978728 BT_gesafet 3;
BA_ "GenSigSwitchedByIgnition" SG_ 2463978728 BT_gesafet 0;
BA_ "GenSigSendType" SG_ 2463978728 BT_Kisi_Fehler 0;
BA_ "GenSigSwitchedByIgnition" SG_ 2463978728 BT_Kisi_Fehler 0;
BA_ "Fehlerwert" SG_ 2463978728 BT_Kisi_Fehler 1;
BA_ "GenSigSendType" SG_ 2463978728 BT_Lock_Taster 3;
BA_ "GenSigSwitchedByIgnition" SG_ 2463978728 BT_Lock_Taster 0;
BA_ "GenSigSendType" SG_ 2463978728 BT_Lock_Taster_inv 3;
BA_ "GenSigSwitchedByIgnition" SG_ 2463978728 BT_Lock_Taster_inv 0;
BA_ "GenSigSendType" SG_ 2463978728 BT_Lock_Unlock_Taster 3;
BA_ "GenSigSwitchedByIgnition" SG_ 2463978728 BT_Lock_Unlock_Taster 0;
BA_ "GenSigSendType" SG_ 2463978728 BT_Oben_Block_erw 3;
BA_ "GenSigSwitchedByIgnition" SG_ 2463978728 BT_Oben_Block_erw 0;
BA_ "GenSigSendType" SG_ 2463978728 BT_Schliesstaster 3;
BA_ "GenSigSwitchedByIgnition" SG_ 2463978728 BT_Schliesstaster 0;
BA_ "GenSigSendType" SG_ 2463978728 BT_Schloss_oeffnen_Ansteuerung 3;
BA_ "GenSigSwitchedByIgnition" SG_ 2463978728 BT_Schloss_oeffnen_Ansteuerung 0;
BA_ "Fehlerwert" SG_ 2463978728 BT_Schloss_oeffnen_Ansteuerung 3;
BA_ "GenSigSendType" SG_ 2463978728 BT_Schloss_Status_OeH_Motor 3;
BA_ "GenSigSwitchedByIgnition" SG_ 2463978728 BT_Schloss_Status_OeH_Motor 0;
BA_ "Fehlerwert" SG_ 2463978728 BT_Schloss_Status_OeH_Motor 3;
BA_ "GenSigSendType" SG_ 2463978728 BT_Schluesselschalter_auf 3;
BA_ "GenSigSwitchedByIgnition" SG_ 2463978728 BT_Schluesselschalter_auf 0;
BA_ "GenSigSendType" SG_ 2463978728 BT_Schluesselschalter_zu 3;
BA_ "GenSigSwitchedByIgnition" SG_ 2463978728 BT_Schluesselschalter_zu 0;
BA_ "GenSigSendType" SG_ 2463978728 BT_Schluesselschalter_zu_inv 3;
BA_ "GenSigSwitchedByIgnition" SG_ 2463978728 BT_Schluesselschalter_zu_inv 0;
BA_ "GenSigSendType" SG_ 2463978728 BT_SP_ausgerastet 9;
BA_ "GenSigSwitchedByIgnition" SG_ 2463978728 BT_SP_ausgerastet 0;
BA_ "GenSigSendType" SG_ 2463978728 BT_Sp_Blk_def 0;
BA_ "GenSigSwitchedByIgnition" SG_ 2463978728 BT_Sp_Blk_def 0;
BA_ "GenSigSendType" SG_ 2463978728 BT_SP_Heizung_aktiv 9;
BA_ "GenSigSwitchedByIgnition" SG_ 2463978728 BT_SP_Heizung_aktiv 0;
BA_ "GenSigSendType" SG_ 2463978728 BT_Sp_Heizung_Anf 3;
BA_ "GenSigSwitchedByIgnition" SG_ 2463978728 BT_Sp_Heizung_Anf 0;
BA_ "GenSigSendType" SG_ 2463978728 BT_SP_Heizung_Status 9;
BA_ "GenSigSwitchedByIgnition" SG_ 2463978728 BT_SP_Heizung_Status 0;
BA_ "GenSigSendType" SG_ 2463978728 BT_SP_ht_aktiv 9;
BA_ "GenSigSwitchedByIgnition" SG_ 2463978728 BT_SP_ht_aktiv 0;
BA_ "GenSigSendType" SG_ 2463978728 BT_SP_lr_aktiv 9;
BA_ "GenSigSwitchedByIgnition" SG_ 2463978728 BT_SP_lr_aktiv 0;
BA_ "GenSigSendType" SG_ 2463978728 BT_Sperrklinke 3;
BA_ "GenSigSwitchedByIgnition" SG_ 2463978728 BT_Sperrklinke 0;
BA_ "GenSigSendType" SG_ 2463978728 BT_SWA_HMI_defekt 0;
BA_ "GenSigSwitchedByIgnition" SG_ 2463978728 BT_SWA_HMI_defekt 0;
BA_ "GenSigSendType" SG_ 2463978728 BT_TAG_betaetigt 3;
BA_ "GenSigSwitchedByIgnition" SG_ 2463978728 BT_TAG_betaetigt 0;
BA_ "GenSigSendType" SG_ 2463978728 BT_TCR_Mode_aktiv 3;
BA_ "GenSigSwitchedByIgnition" SG_ 2463978728 BT_TCR_Mode_aktiv 0;
BA_ "GenSigSendType" SG_ 2463978728 BT_TIG_betaetigt 3;
BA_ "GenSigSwitchedByIgnition" SG_ 2463978728 BT_TIG_betaetigt 0;
BA_ "GenSigSendType" SG_ 2463978728 BT_TSG_hinten_verbaut 3;
BA_ "GenSigSwitchedByIgnition" SG_ 2463978728 BT_TSG_hinten_verbaut 0;
BA_ "GenSigSendType" SG_ 2463978728 BT_Tuer_geoeffnet 3;
BA_ "GenSigSwitchedByIgnition" SG_ 2463978728 BT_Tuer_geoeffnet 0;
BA_ "GenSigSendType" SG_ 2463978728 BT_Tuer_Status 3;
BA_ "GenSigSwitchedByIgnition" SG_ 2463978728 BT_Tuer_Status 0;
BA_ "Fehlerwert" SG_ 2463978728 BT_Tuer_Status 3;
BA_ "GenSigSendType" SG_ 2463978728 BT_Tuer_Status_QBit 3;
BA_ "GenSigSwitchedByIgnition" SG_ 2463978728 BT_Tuer_Status_QBit 0;
BA_ "GenSigSendType" SG_ 2463978728 BT_Tueroeffnen_Warnung 3;
BA_ "GenSigSwitchedByIgnition" SG_ 2463978728 BT_Tueroeffnen_Warnung 0;
BA_ "GenSigSendType" SG_ 2463978728 BT_Tuerschloss_defekt 0;
BA_ "GenSigSwitchedByIgnition" SG_ 2463978728 BT_Tuerschloss_defekt 0;
BA_ "GenSigSendType" SG_ 2463978728 BT_UEKB_aktiviert 3;
BA_ "GenSigSwitchedByIgnition" SG_ 2463978728 BT_UEKB_aktiviert 0;
BA_ "GenSigSendType" SG_ 2463978728 BT_Unlock_Taster 3;
BA_ "GenSigSwitchedByIgnition" SG_ 2463978728 BT_Unlock_Taster 0;
BA_ "GenSigSendType" SG_ 2463978728 BT_Unten_Block_erw 3;
BA_ "GenSigSwitchedByIgnition" SG_ 2463978728 BT_Unten_Block_erw 0;
BA_ "GenSigSendType" SG_ 2463978728 BT_verriegelt 3;
BA_ "GenSigSwitchedByIgnition" SG_ 2463978728 BT_verriegelt 0;
BA_ "GenSigSendType" SG_ 2463978728 BT_Zuziehhilfe_aktiv 3;
BA_ "GenSigSwitchedByIgnition" SG_ 2463978728 BT_Zuziehhilfe_aktiv 0;
BA_ "GenSigSendType" SG_ 2463978728 DoorFunctions_BFS_01_BZ 0;
BA_ "GenSigFuncType" SG_ 2463978728 DoorFunctions_BFS_01_BZ 1;
BA_ "GenSigSwitchedByIgnition" SG_ 2463978728 DoorFunctions_BFS_01_BZ 0;
BA_ "GenSigSendType" SG_ 2463978728 DoorFunctions_BFS_01_CRC 0;
BA_ "GenSigFuncType" SG_ 2463978728 DoorFunctions_BFS_01_CRC 2;
BA_ "GenSigSwitchedByIgnition" SG_ 2463978728 DoorFunctions_BFS_01_CRC 0;
BA_ "GenSigSendType" SG_ 2463978728 eTAB_BFS_Oeffnen_Annaeh 0;
BA_ "GenSigSwitchedByIgnition" SG_ 2463978728 eTAB_BFS_Oeffnen_Annaeh 0;
BA_ "GenSigSendType" SG_ 2463978728 eTAB_BFS_Oeffnen_Betaet 0;
BA_ "GenSigSwitchedByIgnition" SG_ 2463978728 eTAB_BFS_Oeffnen_Betaet 0;
BA_ "GenSigSendType" SG_ 2463978728 eTAB_BFS_Schliessen_Annaeh 0;
BA_ "GenSigSwitchedByIgnition" SG_ 2463978728 eTAB_BFS_Schliessen_Annaeh 0;
BA_ "GenSigSendType" SG_ 2463978728 eTAB_BFS_Schliessen_Betaet 0;
BA_ "GenSigSwitchedByIgnition" SG_ 2463978728 eTAB_BFS_Schliessen_Betaet 0;
BA_ "GenSigSendType" SG_ 2463978728 MTBT_M_Taste 4;
BA_ "GenSigSwitchedByIgnition" SG_ 2463978728 MTBT_M_Taste 0;
BA_ "GenSigSendType" SG_ 2463978728 MTBT_On_Off 4;
BA_ "GenSigSwitchedByIgnition" SG_ 2463978728 MTBT_On_Off 0;
BA_ "GenSigSendType" SG_ 2463978728 MTBT_Pos1 4;
BA_ "GenSigSwitchedByIgnition" SG_ 2463978728 MTBT_Pos1 0;
BA_ "GenSigSendType" SG_ 2463978728 MTBT_Pos2 4;
BA_ "GenSigSwitchedByIgnition" SG_ 2463978728 MTBT_Pos2 0;
BA_ "GenSigSendType" SG_ 2463978728 MTBT_Pos3 4;
BA_ "GenSigSwitchedByIgnition" SG_ 2463978728 MTBT_Pos3 0;
BA_ "GenSigSendType" SG_ 2463978728 MTBT_Pos4 4;
BA_ "GenSigSwitchedByIgnition" SG_ 2463978728 MTBT_Pos4 0;
BA_ "GenSigSendType" SG_ 2463978728 SOK_Doorfunctions_BFS_01_Sign000 0;
BA_ "GenSigFuncType" SG_ 2463978728 SOK_Doorfunctions_BFS_01_Sign000 15;
BA_ "GenSigSwitchedByIgnition" SG_ 2463978728 SOK_Doorfunctions_BFS_01_Sign000 0;
BA_ "GenSigSendType" SG_ 2463978728 SSA_BFT_Amb_Bel_Fehler 0;
BA_ "GenSigSwitchedByIgnition" SG_ 2463978728 SSA_BFT_Amb_Bel_Fehler 0;
BA_ "GenSigSendType" SG_ 2463978728 SSA_BFT_Amb_Bel_Status 0;
BA_ "GenSigSwitchedByIgnition" SG_ 2463978728 SSA_BFT_Amb_Bel_Status 0;
BA_ "GenSigSendType" SG_ 2463978728 SSA_BFT_ASP_Heizung_Fehler 0;
BA_ "GenSigSwitchedByIgnition" SG_ 2463978728 SSA_BFT_ASP_Heizung_Fehler 0;
BA_ "GenSigSendType" SG_ 2463978728 SSA_BFT_ASP_Klappung_Fehler 0;
BA_ "GenSigSwitchedByIgnition" SG_ 2463978728 SSA_BFT_ASP_Klappung_Fehler 0;
BA_ "GenSigSendType" SG_ 2463978728 SSA_BFT_ASP_Klappung_Status 0;
BA_ "GenSigSwitchedByIgnition" SG_ 2463978728 SSA_BFT_ASP_Klappung_Status 0;
BA_ "GenSigSendType" SG_ 2463978728 SSA_BFT_ASP_Spiegelglas_Fehler 0;
BA_ "GenSigSwitchedByIgnition" SG_ 2463978728 SSA_BFT_ASP_Spiegelglas_Fehler 0;
BA_ "GenSigSendType" SG_ 2463978728 SSA_BFT_ASP_Spiegelglas_Pos_Y 0;
BA_ "GenSigSwitchedByIgnition" SG_ 2463978728 SSA_BFT_ASP_Spiegelglas_Pos_Y 0;
BA_ "Fehlerwert" SG_ 2463978728 SSA_BFT_ASP_Spiegelglas_Pos_Y 127;
BA_ "GenSigSendType" SG_ 2463978728 SSA_BFT_ASW_Fehler 0;
BA_ "GenSigSwitchedByIgnition" SG_ 2463978728 SSA_BFT_ASW_Fehler 0;
BA_ "GenSigSendType" SG_ 2463978728 SSA_BFT_ASW_Status 3;
BA_ "GenSigSwitchedByIgnition" SG_ 2463978728 SSA_BFT_ASW_Status 0;
BA_ "GenSigSendType" SG_ 2463978728 SSA_BFT_el_Tuerantrieb_Fehler 0;
BA_ "GenSigSwitchedByIgnition" SG_ 2463978728 SSA_BFT_el_Tuerantrieb_Fehler 0;
BA_ "GenSigSendType" SG_ 2463978728 SSA_BFT_el_Tuerantrieb_Status 0;
BA_ "GenSigSwitchedByIgnition" SG_ 2463978728 SSA_BFT_el_Tuerantrieb_Status 0;
BA_ "GenSigSendType" SG_ 2463978728 SSA_BFT_FH_Bewegungsrichutng 3;
BA_ "GenSigSwitchedByIgnition" SG_ 2463978728 SSA_BFT_FH_Bewegungsrichutng 0;
BA_ "GenSigSendType" SG_ 2463978728 SSA_BFT_FH_Fehler 0;
BA_ "GenSigSwitchedByIgnition" SG_ 2463978728 SSA_BFT_FH_Fehler 0;
BA_ "GenSigSendType" SG_ 2463978728 SSA_BFT_FH_Normierung 0;
BA_ "GenSigSwitchedByIgnition" SG_ 2463978728 SSA_BFT_FH_Normierung 0;
BA_ "GenSigSendType" SG_ 2463978728 SSA_BFT_FH_Thermoschutz 0;
BA_ "GenSigSwitchedByIgnition" SG_ 2463978728 SSA_BFT_FH_Thermoschutz 0;
BA_ "GenSigSendType" SG_ 2463978728 SSA_BFT_Tuerverschluss_Fehler 0;
BA_ "GenSigSwitchedByIgnition" SG_ 2463978728 SSA_BFT_Tuerverschluss_Fehler 0;
BA_ "GenSigSendType" SG_ 2463978728 SSA_BFT_Tuerverschluss_Status 3;
BA_ "GenSigSwitchedByIgnition" SG_ 2463978728 SSA_BFT_Tuerverschluss_Status 0;
BA_ "GenSigSendType" SG_ 2463978728 SSA_BFT_ZV_Ansteuern 0;
BA_ "GenSigSwitchedByIgnition" SG_ 2463978728 SSA_BFT_ZV_Ansteuern 0;
BA_ "Fehlerwert" SG_ 2463978728 SSA_BFT_ZV_Ansteuern 255;
BA_ "GenSigSendType" SG_ 2463978728 SSA_BFT_ZV_Fehler 0;
BA_ "GenSigSwitchedByIgnition" SG_ 2463978728 SSA_BFT_ZV_Fehler 0;
BA_ "GenSigSendType" SG_ 2463978728 SSA_BFT_ZZH_Fehler 0;
BA_ "GenSigSwitchedByIgnition" SG_ 2463978728 SSA_BFT_ZZH_Fehler 0;
BA_ "GenSigSendType" SG_ 2463978728 SSA_BFT_ZZH_Status 3;
BA_ "GenSigSwitchedByIgnition" SG_ 2463978728 SSA_BFT_ZZH_Status 0;
BA_ "GenSigSendType" SG_ 2463978728 TSG_FlHz_BFS_FnAbbruchHzKreis_A 0;
BA_ "GenSigSwitchedByIgnition" SG_ 2463978728 TSG_FlHz_BFS_FnAbbruchHzKreis_A 0;
BA_ "GenSigSendType" SG_ 2463978728 TSG_FlHz_BFS_FnAbbruchHzKreis_B 0;
BA_ "GenSigSwitchedByIgnition" SG_ 2463978728 TSG_FlHz_BFS_FnAbbruchHzKreis_B 0;
BA_ "GenSigSendType" SG_ 2463978728 TSG_FlHz_BFS_NTC_A 0;
BA_ "GenSigStartValue" SG_ 2463978728 TSG_FlHz_BFS_NTC_A 127;
BA_ "GenSigSwitchedByIgnition" SG_ 2463978728 TSG_FlHz_BFS_NTC_A 0;
BA_ "GenSigSendType" SG_ 2463978728 TSG_FlHz_BFS_NTC_B 0;
BA_ "GenSigStartValue" SG_ 2463978728 TSG_FlHz_BFS_NTC_B 127;
BA_ "GenSigSwitchedByIgnition" SG_ 2463978728 TSG_FlHz_BFS_NTC_B 0;
BA_ "GenSigSendType" SG_ 2463978728 TSG_FlHz_BFS_Unterbrech_HzK_B 3;
BA_ "GenSigSwitchedByIgnition" SG_ 2463978728 TSG_FlHz_BFS_Unterbrech_HzK_B 0;
BA_ "GenSigSendType" SG_ 2463978714 ASW_HMI_defekt 0;
BA_ "GenSigSwitchedByIgnition" SG_ 2463978714 ASW_HMI_defekt 0;
BA_ "GenSigSendType" SG_ 2463978714 ASW_wakeup 3;
BA_ "GenSigSwitchedByIgnition" SG_ 2463978714 ASW_wakeup 0;
BA_ "GenSigSendType" SG_ 2463978714 ASW_Warnung_aktiv_FS 3;
BA_ "GenSigSwitchedByIgnition" SG_ 2463978714 ASW_Warnung_aktiv_FS 0;
BA_ "GenSigSendType" SG_ 2463978714 ASW_Warnung_Aussenlicht_FS_Li 3;
BA_ "GenSigSwitchedByIgnition" SG_ 2463978714 ASW_Warnung_Aussenlicht_FS_Li 0;
BA_ "GenSigSendType" SG_ 2463978714 ASW_Warnung_Aussenlicht_FS_Re 3;
BA_ "GenSigSwitchedByIgnition" SG_ 2463978714 ASW_Warnung_Aussenlicht_FS_Re 0;
BA_ "GenSigSendType" SG_ 2463978714 DoorFunctions_FS_01_BZ 0;
BA_ "GenSigFuncType" SG_ 2463978714 DoorFunctions_FS_01_BZ 1;
BA_ "GenSigSwitchedByIgnition" SG_ 2463978714 DoorFunctions_FS_01_BZ 0;
BA_ "GenSigSendType" SG_ 2463978714 DoorFunctions_FS_01_CRC 0;
BA_ "GenSigFuncType" SG_ 2463978714 DoorFunctions_FS_01_CRC 2;
BA_ "GenSigSwitchedByIgnition" SG_ 2463978714 DoorFunctions_FS_01_CRC 0;
BA_ "GenSigSendType" SG_ 2463978714 eTAB_FS_Bowdenzug_Auswerfen 3;
BA_ "GenSigSwitchedByIgnition" SG_ 2463978714 eTAB_FS_Bowdenzug_Auswerfen 0;
BA_ "GenSigSendType" SG_ 2463978714 eTAB_FS_Oeffnen_Annaeh 0;
BA_ "GenSigSwitchedByIgnition" SG_ 2463978714 eTAB_FS_Oeffnen_Annaeh 0;
BA_ "GenSigSendType" SG_ 2463978714 eTAB_FS_Oeffnen_Betaet 0;
BA_ "GenSigSwitchedByIgnition" SG_ 2463978714 eTAB_FS_Oeffnen_Betaet 0;
BA_ "GenSigSendType" SG_ 2463978714 eTAB_FS_Schliessen_Annaeh 0;
BA_ "GenSigSwitchedByIgnition" SG_ 2463978714 eTAB_FS_Schliessen_Annaeh 0;
BA_ "GenSigSendType" SG_ 2463978714 eTAB_FS_Schliessen_Betaet 0;
BA_ "GenSigSwitchedByIgnition" SG_ 2463978714 eTAB_FS_Schliessen_Betaet 0;
BA_ "GenSigSendType" SG_ 2463978714 FS_Push_Tuergriff 3;
BA_ "GenSigSwitchedByIgnition" SG_ 2463978714 FS_Push_Tuergriff 0;
BA_ "GenSigSendType" SG_ 2463978714 FS_Status_eTAG 3;
BA_ "GenSigSwitchedByIgnition" SG_ 2463978714 FS_Status_eTAG 0;
BA_ "Fehlerwert" SG_ 2463978714 FS_Status_eTAG 3;
BA_ "GenSigSendType" SG_ 2463978714 FS_Status_eTAG_ext 3;
BA_ "GenSigStartValue" SG_ 2463978714 FS_Status_eTAG_ext 3;
BA_ "GenSigSwitchedByIgnition" SG_ 2463978714 FS_Status_eTAG_ext 0;
BA_ "Fehlerwert" SG_ 2463978714 FS_Status_eTAG_ext 4;
BA_ "GenSigSendType" SG_ 2463978714 FT_ASW_Warnton 3;
BA_ "GenSigSwitchedByIgnition" SG_ 2463978714 FT_ASW_Warnton 0;
BA_ "Fehlerwert" SG_ 2463978714 FT_ASW_Warnton 3;
BA_ "GenSigSendType" SG_ 2463978714 FT_ASW_Warnung_Aussenlicht 3;
BA_ "GenSigSwitchedByIgnition" SG_ 2463978714 FT_ASW_Warnung_Aussenlicht 0;
BA_ "Fehlerwert" SG_ 2463978714 FT_ASW_Warnung_Aussenlicht 3;
BA_ "GenSigSendType" SG_ 2463978714 FT_BFS_Fond_Freigabe 3;
BA_ "GenSigSwitchedByIgnition" SG_ 2463978714 FT_BFS_Fond_Freigabe 0;
BA_ "GenSigSendType" SG_ 2463978714 FT_BFS_Tuer_Status 3;
BA_ "GenSigSwitchedByIgnition" SG_ 2463978714 FT_BFS_Tuer_Status 0;
BA_ "Fehlerwert" SG_ 2463978714 FT_BFS_Tuer_Status 3;
BA_ "GenSigSendType" SG_ 2463978714 FT_Cargolock_bet 3;
BA_ "GenSigSwitchedByIgnition" SG_ 2463978714 FT_Cargolock_bet 0;
BA_ "GenSigSendType" SG_ 2463978714 FT_Daemmglas 0;
BA_ "GenSigSwitchedByIgnition" SG_ 2463978714 FT_Daemmglas 0;
BA_ "GenSigSendType" SG_ 2463978714 FT_FH_Bew_hoch 3;
BA_ "GenSigSwitchedByIgnition" SG_ 2463978714 FT_FH_Bew_hoch 0;
BA_ "GenSigSendType" SG_ 2463978714 FT_FH_Bew_tief 3;
BA_ "GenSigSwitchedByIgnition" SG_ 2463978714 FT_FH_Bew_tief 0;
BA_ "GenSigSendType" SG_ 2463978714 FT_FH_Block 3;
BA_ "GenSigSwitchedByIgnition" SG_ 2463978714 FT_FH_Block 0;
BA_ "GenSigSendType" SG_ 2463978714 FT_FH_Fang 3;
BA_ "GenSigSwitchedByIgnition" SG_ 2463978714 FT_FH_Fang 0;
BA_ "GenSigSendType" SG_ 2463978714 FT_FH_normiert 3;
BA_ "GenSigSwitchedByIgnition" SG_ 2463978714 FT_FH_normiert 0;
BA_ "GenSigSendType" SG_ 2463978714 FT_FH_Oeffnung 3;
BA_ "GenSigSwitchedByIgnition" SG_ 2463978714 FT_FH_Oeffnung 0;
BA_ "GenSigSendType" SG_ 2463978714 FT_FH_Pos_oben 3;
BA_ "GenSigSwitchedByIgnition" SG_ 2463978714 FT_FH_Pos_oben 0;
BA_ "GenSigSendType" SG_ 2463978714 FT_FH_S_AutoHoch 3;
BA_ "GenSigSwitchedByIgnition" SG_ 2463978714 FT_FH_S_AutoHoch 0;
BA_ "GenSigSendType" SG_ 2463978714 FT_FH_S_AutoTief 3;
BA_ "GenSigSwitchedByIgnition" SG_ 2463978714 FT_FH_S_AutoTief 0;
BA_ "GenSigSendType" SG_ 2463978714 FT_FH_S_ManHoch 3;
BA_ "GenSigSwitchedByIgnition" SG_ 2463978714 FT_FH_S_ManHoch 0;
BA_ "GenSigSendType" SG_ 2463978714 FT_FH_S_ManTief 3;
BA_ "GenSigSwitchedByIgnition" SG_ 2463978714 FT_FH_S_ManTief 0;
BA_ "GenSigSendType" SG_ 2463978714 FT_FH_Thermo 3;
BA_ "GenSigSwitchedByIgnition" SG_ 2463978714 FT_FH_Thermo 0;
BA_ "GenSigSendType" SG_ 2463978714 FT_gesafet 3;
BA_ "GenSigSwitchedByIgnition" SG_ 2463978714 FT_gesafet 0;
BA_ "GenSigSendType" SG_ 2463978714 FT_HBFS_Tuer_Status 3;
BA_ "GenSigSwitchedByIgnition" SG_ 2463978714 FT_HBFS_Tuer_Status 0;
BA_ "Fehlerwert" SG_ 2463978714 FT_HBFS_Tuer_Status 3;
BA_ "GenSigSendType" SG_ 2463978714 FT_HD_Taste 3;
BA_ "GenSigSwitchedByIgnition" SG_ 2463978714 FT_HD_Taste 0;
BA_ "GenSigSendType" SG_ 2463978714 FT_HD_Taste_2 3;
BA_ "GenSigSwitchedByIgnition" SG_ 2463978714 FT_HD_Taste_2 0;
BA_ "GenSigSendType" SG_ 2463978714 FT_HD_Taste_auf 5;
BA_ "GenSigSwitchedByIgnition" SG_ 2463978714 FT_HD_Taste_auf 0;
BA_ "GenSigSendType" SG_ 2463978714 FT_HD_Taste_zu 5;
BA_ "GenSigSwitchedByIgnition" SG_ 2463978714 FT_HD_Taste_zu 0;
BA_ "GenSigSendType" SG_ 2463978714 FT_HFS_Tuer_Status 3;
BA_ "GenSigSwitchedByIgnition" SG_ 2463978714 FT_HFS_Tuer_Status 0;
BA_ "Fehlerwert" SG_ 2463978714 FT_HFS_Tuer_Status 3;
BA_ "GenSigSendType" SG_ 2463978714 FT_IRUE_Taste 3;
BA_ "GenSigSwitchedByIgnition" SG_ 2463978714 FT_IRUE_Taste 0;
BA_ "GenSigSendType" SG_ 2463978714 FT_Kisi_Fehler 0;
BA_ "GenSigSwitchedByIgnition" SG_ 2463978714 FT_Kisi_Fehler 0;
BA_ "Fehlerwert" SG_ 2463978714 FT_Kisi_Fehler 1;
BA_ "GenSigSendType" SG_ 2463978714 FT_Kisi_li_aktiv 3;
BA_ "GenSigSwitchedByIgnition" SG_ 2463978714 FT_Kisi_li_aktiv 0;
BA_ "GenSigSendType" SG_ 2463978714 FT_Kisi_re_aktiv 3;
BA_ "GenSigSwitchedByIgnition" SG_ 2463978714 FT_Kisi_re_aktiv 0;
BA_ "GenSigSendType" SG_ 2463978714 FT_KiSi_Status_Soll_HBFS 3;
BA_ "GenSigSwitchedByIgnition" SG_ 2463978714 FT_KiSi_Status_Soll_HBFS 0;
BA_ "GenSigSendType" SG_ 2463978714 FT_KiSi_Status_Soll_HFS 3;
BA_ "GenSigSwitchedByIgnition" SG_ 2463978714 FT_KiSi_Status_Soll_HFS 0;
BA_ "GenSigSendType" SG_ 2463978714 FT_Kisi_Taster_li 3;
BA_ "GenSigSwitchedByIgnition" SG_ 2463978714 FT_Kisi_Taster_li 0;
BA_ "GenSigSendType" SG_ 2463978714 FT_Kisi_Taster_li_02 3;
BA_ "GenSigSwitchedByIgnition" SG_ 2463978714 FT_Kisi_Taster_li_02 0;
BA_ "GenSigSendType" SG_ 2463978714 FT_Kisi_Taster_re 3;
BA_ "GenSigSwitchedByIgnition" SG_ 2463978714 FT_Kisi_Taster_re 0;
BA_ "GenSigSendType" SG_ 2463978714 FT_Kisi_Taster_re_02 3;
BA_ "GenSigSwitchedByIgnition" SG_ 2463978714 FT_Kisi_Taster_re_02 0;
BA_ "GenSigSendType" SG_ 2463978714 FT_Lock_Taster 3;
BA_ "GenSigSwitchedByIgnition" SG_ 2463978714 FT_Lock_Taster 0;
BA_ "GenSigSendType" SG_ 2463978714 FT_Lock_Unlock_Taster 3;
BA_ "GenSigSwitchedByIgnition" SG_ 2463978714 FT_Lock_Unlock_Taster 0;
BA_ "GenSigSendType" SG_ 2463978714 FT_Oben_Block_erw 3;
BA_ "GenSigSwitchedByIgnition" SG_ 2463978714 FT_Oben_Block_erw 0;
BA_ "GenSigSendType" SG_ 2463978714 FT_Schliesstaster 3;
BA_ "GenSigSwitchedByIgnition" SG_ 2463978714 FT_Schliesstaster 0;
BA_ "GenSigSendType" SG_ 2463978714 FT_Schloss_oeffnen_Ansteuerung 3;
BA_ "GenSigSwitchedByIgnition" SG_ 2463978714 FT_Schloss_oeffnen_Ansteuerung 0;
BA_ "Fehlerwert" SG_ 2463978714 FT_Schloss_oeffnen_Ansteuerung 3;
BA_ "GenSigSendType" SG_ 2463978714 FT_Schloss_Status_OeH_Motor 3;
BA_ "GenSigSwitchedByIgnition" SG_ 2463978714 FT_Schloss_Status_OeH_Motor 0;
BA_ "Fehlerwert" SG_ 2463978714 FT_Schloss_Status_OeH_Motor 3;
BA_ "GenSigSendType" SG_ 2463978714 FT_Schluesselschalter_auf 3;
BA_ "GenSigSwitchedByIgnition" SG_ 2463978714 FT_Schluesselschalter_auf 0;
BA_ "GenSigSendType" SG_ 2463978714 FT_Schluesselschalter_zu 3;
BA_ "GenSigSwitchedByIgnition" SG_ 2463978714 FT_Schluesselschalter_zu 0;
BA_ "GenSigSendType" SG_ 2463978714 FT_SP_ausgerastet 3;
BA_ "GenSigSwitchedByIgnition" SG_ 2463978714 FT_SP_ausgerastet 0;
BA_ "GenSigSendType" SG_ 2463978714 FT_Sp_Blk_def 0;
BA_ "GenSigSwitchedByIgnition" SG_ 2463978714 FT_Sp_Blk_def 0;
BA_ "GenSigSendType" SG_ 2463978714 FT_Sp_Heizung_Anf 3;
BA_ "GenSigSwitchedByIgnition" SG_ 2463978714 FT_Sp_Heizung_Anf 0;
BA_ "GenSigSendType" SG_ 2463978714 FT_SP_Heizung_ein 3;
BA_ "GenSigSwitchedByIgnition" SG_ 2463978714 FT_SP_Heizung_ein 0;
BA_ "GenSigSendType" SG_ 2463978714 FT_SP_Heizung_Status 3;
BA_ "GenSigSwitchedByIgnition" SG_ 2463978714 FT_SP_Heizung_Status 0;
BA_ "GenSigSendType" SG_ 2463978714 FT_SP_ht_aktiv 3;
BA_ "GenSigSwitchedByIgnition" SG_ 2463978714 FT_SP_ht_aktiv 0;
BA_ "GenSigSendType" SG_ 2463978714 FT_SP_lr_aktiv 3;
BA_ "GenSigSwitchedByIgnition" SG_ 2463978714 FT_SP_lr_aktiv 0;
BA_ "GenSigSendType" SG_ 2463978714 FT_Sperrklinke 3;
BA_ "GenSigSwitchedByIgnition" SG_ 2463978714 FT_Sperrklinke 0;
BA_ "GenSigSendType" SG_ 2463978714 FT_SWA_Taster 3;
BA_ "GenSigSwitchedByIgnition" SG_ 2463978714 FT_SWA_Taster 0;
BA_ "GenSigSendType" SG_ 2463978714 FT_TAG_betaetigt 3;
BA_ "GenSigSwitchedByIgnition" SG_ 2463978714 FT_TAG_betaetigt 0;
BA_ "GenSigSendType" SG_ 2463978714 FT_TCR_Mode_aktiv 3;
BA_ "GenSigSwitchedByIgnition" SG_ 2463978714 FT_TCR_Mode_aktiv 0;
BA_ "GenSigSendType" SG_ 2463978714 FT_TD_Taste 3;
BA_ "GenSigSwitchedByIgnition" SG_ 2463978714 FT_TD_Taste 0;
BA_ "GenSigSendType" SG_ 2463978714 FT_TD_Taste_Fehler 0;
BA_ "GenSigSwitchedByIgnition" SG_ 2463978714 FT_TD_Taste_Fehler 0;
BA_ "GenSigSendType" SG_ 2463978714 FT_TD_Taste_Status 3;
BA_ "GenSigSwitchedByIgnition" SG_ 2463978714 FT_TD_Taste_Status 0;
BA_ "GenSigSendType" SG_ 2463978714 FT_TIG_betaetigt 3;
BA_ "GenSigSwitchedByIgnition" SG_ 2463978714 FT_TIG_betaetigt 0;
BA_ "GenSigSendType" SG_ 2463978714 FT_TSG_hinten_verbaut 0;
BA_ "GenSigSwitchedByIgnition" SG_ 2463978714 FT_TSG_hinten_verbaut 0;
BA_ "GenSigSendType" SG_ 2463978714 FT_Tuer_geoeffnet 3;
BA_ "GenSigSwitchedByIgnition" SG_ 2463978714 FT_Tuer_geoeffnet 0;
BA_ "GenSigSendType" SG_ 2463978714 FT_Tuer_Status 3;
BA_ "GenSigSwitchedByIgnition" SG_ 2463978714 FT_Tuer_Status 0;
BA_ "Fehlerwert" SG_ 2463978714 FT_Tuer_Status 3;
BA_ "GenSigSendType" SG_ 2463978714 FT_Tuer_Status_QBit 3;
BA_ "GenSigSwitchedByIgnition" SG_ 2463978714 FT_Tuer_Status_QBit 0;
BA_ "GenSigSendType" SG_ 2463978714 FT_Tueroeffnen_Warnung 3;
BA_ "GenSigSwitchedByIgnition" SG_ 2463978714 FT_Tueroeffnen_Warnung 0;
BA_ "GenSigSendType" SG_ 2463978714 FT_Tuerschloss_defekt 0;
BA_ "GenSigSwitchedByIgnition" SG_ 2463978714 FT_Tuerschloss_defekt 0;
BA_ "GenSigSendType" SG_ 2463978714 FT_UEKB_aktiviert 3;
BA_ "GenSigSwitchedByIgnition" SG_ 2463978714 FT_UEKB_aktiviert 0;
BA_ "GenSigSendType" SG_ 2463978714 FT_Unlock_Taster 3;
BA_ "GenSigSwitchedByIgnition" SG_ 2463978714 FT_Unlock_Taster 0;
BA_ "GenSigSendType" SG_ 2463978714 FT_Unten_Block_erw 3;
BA_ "GenSigSwitchedByIgnition" SG_ 2463978714 FT_Unten_Block_erw 0;
BA_ "GenSigSendType" SG_ 2463978714 FT_verriegelt 3;
BA_ "GenSigSwitchedByIgnition" SG_ 2463978714 FT_verriegelt 0;
BA_ "GenSigSendType" SG_ 2463978714 FT_Zuziehhilfe_aktiv 3;
BA_ "GenSigSwitchedByIgnition" SG_ 2463978714 FT_Zuziehhilfe_aktiv 0;
BA_ "GenSigSendType" SG_ 2463978714 MemFT_Pos1_EE 4;
BA_ "GenSigSwitchedByIgnition" SG_ 2463978714 MemFT_Pos1_EE 0;
BA_ "Fehlerwert" SG_ 2463978714 MemFT_Pos1_EE 3;
BA_ "GenSigSendType" SG_ 2463978714 MemFT_Pos2 4;
BA_ "GenSigSwitchedByIgnition" SG_ 2463978714 MemFT_Pos2 0;
BA_ "Fehlerwert" SG_ 2463978714 MemFT_Pos2 3;
BA_ "GenSigSendType" SG_ 2463978714 MemFT_Pos3 4;
BA_ "GenSigSwitchedByIgnition" SG_ 2463978714 MemFT_Pos3 0;
BA_ "Fehlerwert" SG_ 2463978714 MemFT_Pos3 3;
BA_ "GenSigSendType" SG_ 2463978714 MemFT_Pos4 4;
BA_ "GenSigSwitchedByIgnition" SG_ 2463978714 MemFT_Pos4 0;
BA_ "Fehlerwert" SG_ 2463978714 MemFT_Pos4 3;
BA_ "GenSigSendType" SG_ 2463978714 MTFT_M_Taste 3;
BA_ "GenSigSwitchedByIgnition" SG_ 2463978714 MTFT_M_Taste 0;
BA_ "GenSigSendType" SG_ 2463978714 MTFT_On_Off 3;
BA_ "GenSigSwitchedByIgnition" SG_ 2463978714 MTFT_On_Off 0;
BA_ "GenSigSendType" SG_ 2463978714 MTFT_Pos1_EE 3;
BA_ "GenSigSwitchedByIgnition" SG_ 2463978714 MTFT_Pos1_EE 0;
BA_ "GenSigSendType" SG_ 2463978714 MTFT_Pos2 3;
BA_ "GenSigSwitchedByIgnition" SG_ 2463978714 MTFT_Pos2 0;
BA_ "GenSigSendType" SG_ 2463978714 MTFT_Pos3 3;
BA_ "GenSigSwitchedByIgnition" SG_ 2463978714 MTFT_Pos3 0;
BA_ "GenSigSendType" SG_ 2463978714 MTFT_Pos4 3;
BA_ "GenSigSwitchedByIgnition" SG_ 2463978714 MTFT_Pos4 0;
BA_ "GenSigSendType" SG_ 2463978714 MTFT_Verst_akt 3;
BA_ "GenSigSwitchedByIgnition" SG_ 2463978714 MTFT_Verst_akt 0;
BA_ "GenSigSendType" SG_ 2463978714 SOK_Doorfunctions_FS_01_Signatur 0;
BA_ "GenSigFuncType" SG_ 2463978714 SOK_Doorfunctions_FS_01_Signatur 15;
BA_ "GenSigSwitchedByIgnition" SG_ 2463978714 SOK_Doorfunctions_FS_01_Signatur 0;
BA_ "GenSigSendType" SG_ 2463978714 SP_abklappen 3;
BA_ "GenSigSwitchedByIgnition" SG_ 2463978714 SP_abklappen 0;
BA_ "GenSigSendType" SG_ 2463978714 SP_anklappen 3;
BA_ "GenSigSwitchedByIgnition" SG_ 2463978714 SP_anklappen 0;
BA_ "GenSigSendType" SG_ 2463978714 SP_ARA_Status 3;
BA_ "GenSigSendType" SG_ 2463978714 SP_Auswahl_li 3;
BA_ "GenSigSwitchedByIgnition" SG_ 2463978714 SP_Auswahl_li 0;
BA_ "GenSigSendType" SG_ 2463978714 SP_Auswahl_re 3;
BA_ "GenSigSwitchedByIgnition" SG_ 2463978714 SP_Auswahl_re 0;
BA_ "GenSigSendType" SG_ 2463978714 SP_Bordsteinfunktion 4;
BA_ "GenSigSwitchedByIgnition" SG_ 2463978714 SP_Bordsteinfunktion 0;
BA_ "GenSigSendType" SG_ 2463978714 SP_BT_links 3;
BA_ "GenSigSwitchedByIgnition" SG_ 2463978714 SP_BT_links 0;
BA_ "GenSigSendType" SG_ 2463978714 SP_BT_oben 3;
BA_ "GenSigSwitchedByIgnition" SG_ 2463978714 SP_BT_oben 0;
BA_ "GenSigSendType" SG_ 2463978714 SP_BT_rechts 3;
BA_ "GenSigSwitchedByIgnition" SG_ 2463978714 SP_BT_rechts 0;
BA_ "GenSigSendType" SG_ 2463978714 SP_BT_unten 3;
BA_ "GenSigSwitchedByIgnition" SG_ 2463978714 SP_BT_unten 0;
BA_ "GenSigSendType" SG_ 2463978714 SP_FT_links 3;
BA_ "GenSigSwitchedByIgnition" SG_ 2463978714 SP_FT_links 0;
BA_ "GenSigSendType" SG_ 2463978714 SP_FT_oben 3;
BA_ "GenSigSwitchedByIgnition" SG_ 2463978714 SP_FT_oben 0;
BA_ "GenSigSendType" SG_ 2463978714 SP_FT_rechts 3;
BA_ "GenSigSwitchedByIgnition" SG_ 2463978714 SP_FT_rechts 0;
BA_ "GenSigSendType" SG_ 2463978714 SP_FT_unten 3;
BA_ "GenSigSwitchedByIgnition" SG_ 2463978714 SP_FT_unten 0;
BA_ "GenSigSendType" SG_ 2463978714 SP_Hzg_Taster 3;
BA_ "GenSigSwitchedByIgnition" SG_ 2463978714 SP_Hzg_Taster 0;
BA_ "GenSigSendType" SG_ 2463978714 SP_normieren 3;
BA_ "GenSigSwitchedByIgnition" SG_ 2463978714 SP_normieren 0;
BA_ "GenSigSendType" SG_ 2463978714 SP_S_Klappen 3;
BA_ "GenSigSwitchedByIgnition" SG_ 2463978714 SP_S_Klappen 0;
BA_ "GenSigSendType" SG_ 2463978714 SP_S_links 3;
BA_ "GenSigSwitchedByIgnition" SG_ 2463978714 SP_S_links 0;
BA_ "GenSigSendType" SG_ 2463978714 SP_S_oben 3;
BA_ "GenSigSwitchedByIgnition" SG_ 2463978714 SP_S_oben 0;
BA_ "GenSigSendType" SG_ 2463978714 SP_S_rechts 3;
BA_ "GenSigSwitchedByIgnition" SG_ 2463978714 SP_S_rechts 0;
BA_ "GenSigSendType" SG_ 2463978714 SP_S_unten 3;
BA_ "GenSigSwitchedByIgnition" SG_ 2463978714 SP_S_unten 0;
BA_ "GenSigSendType" SG_ 2463978714 SP_Spg_Verstellschalter_Fehler 3;
BA_ "Fehlerwert" SG_ 2463978714 SP_Spg_Verstellschalter_Fehler 1;
BA_ "GenSigSendType" SG_ 2463978714 SP_Verstellschalter_Fehler 3;
BA_ "Fehlerwert" SG_ 2463978714 SP_Verstellschalter_Fehler 1;
BA_ "GenSigSendType" SG_ 2463978714 SSA_FT_Amb_Bel_Fehler 0;
BA_ "GenSigSwitchedByIgnition" SG_ 2463978714 SSA_FT_Amb_Bel_Fehler 0;
BA_ "GenSigSendType" SG_ 2463978714 SSA_FT_Amb_Bel_Status 0;
BA_ "GenSigSwitchedByIgnition" SG_ 2463978714 SSA_FT_Amb_Bel_Status 0;
BA_ "GenSigSendType" SG_ 2463978714 SSA_FT_ASP_Heizung_Fehler 0;
BA_ "GenSigSwitchedByIgnition" SG_ 2463978714 SSA_FT_ASP_Heizung_Fehler 0;
BA_ "GenSigSendType" SG_ 2463978714 SSA_FT_ASP_Klappung_Fehler 0;
BA_ "GenSigSwitchedByIgnition" SG_ 2463978714 SSA_FT_ASP_Klappung_Fehler 0;
BA_ "GenSigSendType" SG_ 2463978714 SSA_FT_ASP_Spiegelglas_Fehler 0;
BA_ "GenSigSwitchedByIgnition" SG_ 2463978714 SSA_FT_ASP_Spiegelglas_Fehler 0;
BA_ "GenSigSendType" SG_ 2463978714 SSA_FT_ASP_Spiegelglas_Pos_X 0;
BA_ "GenSigSwitchedByIgnition" SG_ 2463978714 SSA_FT_ASP_Spiegelglas_Pos_X 0;
BA_ "Fehlerwert" SG_ 2463978714 SSA_FT_ASP_Spiegelglas_Pos_X 127;
BA_ "GenSigSendType" SG_ 2463978714 SSA_FT_ASW_Fehler 0;
BA_ "GenSigSwitchedByIgnition" SG_ 2463978714 SSA_FT_ASW_Fehler 0;
BA_ "GenSigSendType" SG_ 2463978714 SSA_FT_ASW_Status 3;
BA_ "GenSigSwitchedByIgnition" SG_ 2463978714 SSA_FT_ASW_Status 0;
BA_ "GenSigSendType" SG_ 2463978714 SSA_FT_el_Tuerantrieb_Fehler 0;
BA_ "GenSigSwitchedByIgnition" SG_ 2463978714 SSA_FT_el_Tuerantrieb_Fehler 0;
BA_ "GenSigSendType" SG_ 2463978714 SSA_FT_el_Tuerantrieb_Status 3;
BA_ "GenSigSwitchedByIgnition" SG_ 2463978714 SSA_FT_el_Tuerantrieb_Status 0;
BA_ "GenSigSendType" SG_ 2463978714 SSA_FT_FH_Bewegungsrichutng 3;
BA_ "GenSigSwitchedByIgnition" SG_ 2463978714 SSA_FT_FH_Bewegungsrichutng 0;
BA_ "GenSigSendType" SG_ 2463978714 SSA_FT_FH_Fehler 0;
BA_ "GenSigSwitchedByIgnition" SG_ 2463978714 SSA_FT_FH_Fehler 0;
BA_ "GenSigSendType" SG_ 2463978714 SSA_FT_FH_Normierung 3;
BA_ "GenSigSwitchedByIgnition" SG_ 2463978714 SSA_FT_FH_Normierung 0;
BA_ "GenSigSendType" SG_ 2463978714 SSA_FT_FH_Thermoschutz 3;
BA_ "GenSigSwitchedByIgnition" SG_ 2463978714 SSA_FT_FH_Thermoschutz 0;
BA_ "GenSigSendType" SG_ 2463978714 SSA_FT_Tuerverschluss_Fehler 0;
BA_ "GenSigSwitchedByIgnition" SG_ 2463978714 SSA_FT_Tuerverschluss_Fehler 0;
BA_ "GenSigSendType" SG_ 2463978714 SSA_FT_Tuerverschluss_Status 3;
BA_ "GenSigSwitchedByIgnition" SG_ 2463978714 SSA_FT_Tuerverschluss_Status 0;
BA_ "GenSigSendType" SG_ 2463978714 SSA_FT_ZV_Fehler 0;
BA_ "GenSigSwitchedByIgnition" SG_ 2463978714 SSA_FT_ZV_Fehler 0;
BA_ "GenSigSendType" SG_ 2463978714 SSA_FT_ZV_Status 0;
BA_ "GenSigSwitchedByIgnition" SG_ 2463978714 SSA_FT_ZV_Status 0;
BA_ "Fehlerwert" SG_ 2463978714 SSA_FT_ZV_Status 15;
BA_ "GenSigSendType" SG_ 2463978714 SSA_FT_ZZH_Fehler 3;
BA_ "GenSigSwitchedByIgnition" SG_ 2463978714 SSA_FT_ZZH_Fehler 0;
BA_ "GenSigSendType" SG_ 2463978714 SSA_FT_ZZH_Status 3;
BA_ "GenSigSwitchedByIgnition" SG_ 2463978714 SSA_FT_ZZH_Status 0;
BA_ "GenSigSendType" SG_ 2463978714 SSR_Temp_Freigabe 3;
BA_ "GenSigSwitchedByIgnition" SG_ 2463978714 SSR_Temp_Freigabe 0;
BA_ "GenSigSendType" SG_ 2463978714 SWA_HMI_Diagnose 0;
BA_ "GenSigSwitchedByIgnition" SG_ 2463978714 SWA_HMI_Diagnose 0;
BA_ "GenSigSendType" SG_ 2463978714 TBF_FS_Touch_Event 3;
BA_ "GenSigSwitchedByIgnition" SG_ 2463978714 TBF_FS_Touch_Event 0;
BA_ "GenSigSendType" SG_ 2463978714 TSG_FlHz_FS_FnAbbruchHzKreis_A 0;
BA_ "GenSigSwitchedByIgnition" SG_ 2463978714 TSG_FlHz_FS_FnAbbruchHzKreis_A 0;
BA_ "GenSigSendType" SG_ 2463978714 TSG_FlHz_FS_FnAbbruchHzKreis_B 0;
BA_ "GenSigSwitchedByIgnition" SG_ 2463978714 TSG_FlHz_FS_FnAbbruchHzKreis_B 0;
BA_ "GenSigSendType" SG_ 2463978714 TSG_FlHz_FS_NTC_A 0;
BA_ "GenSigStartValue" SG_ 2463978714 TSG_FlHz_FS_NTC_A 127;
BA_ "GenSigSwitchedByIgnition" SG_ 2463978714 TSG_FlHz_FS_NTC_A 0;
BA_ "GenSigSendType" SG_ 2463978714 TSG_FlHz_FS_NTC_B 0;
BA_ "GenSigStartValue" SG_ 2463978714 TSG_FlHz_FS_NTC_B 127;
BA_ "GenSigSwitchedByIgnition" SG_ 2463978714 TSG_FlHz_FS_NTC_B 0;
BA_ "GenSigSendType" SG_ 2463978714 TSG_FlHz_FS_Unterbrech_HzK_A 3;
BA_ "GenSigSwitchedByIgnition" SG_ 2463978714 TSG_FlHz_FS_Unterbrech_HzK_A 0;
BA_ "GenSigSendType" SG_ 2463978714 TSG_FlHz_FS_Unterbrech_HzK_B 3;
BA_ "GenSigSwitchedByIgnition" SG_ 2463978714 TSG_FlHz_FS_Unterbrech_HzK_B 0;
BA_ "GenSigSendType" SG_ 2463978714 TSG_FS_Spiegel_angeklappt 3;
BA_ "GenSigSwitchedByIgnition" SG_ 2463978714 TSG_FS_Spiegel_angeklappt 0;
BA_REL_ "GenSigTimeoutTime" BU_SG_REL_ BCM SG_ 1714 DGN_Verlernzaehler 5000;
BA_REL_ "GenSigTimeoutTime" BU_SG_REL_ BCM SG_ 1714 KBI_Kilometerstand 5000;
BA_REL_ "GenSigTimeoutTime" BU_SG_REL_ BCM SG_ 1714 UH_Jahr 5000;
BA_REL_ "GenSigTimeoutTime" BU_SG_REL_ BCM SG_ 1714 UH_Monat 5000;
BA_REL_ "GenSigTimeoutTime" BU_SG_REL_ BCM SG_ 1714 UH_Tag 5000;
BA_REL_ "GenSigTimeoutTime" BU_SG_REL_ BCM SG_ 1714 UH_Stunde 5000;
BA_REL_ "GenSigTimeoutTime" BU_SG_REL_ BCM SG_ 1714 UH_Minute 5000;
BA_REL_ "GenSigTimeoutTime" BU_SG_REL_ BCM SG_ 1714 UH_Sekunde 5000;
BA_REL_ "GenSigTimeoutTime" BU_SG_REL_ BCM SG_ 1714 Kombi_02_alt 5000;
BA_REL_ "GenSigTimeoutTime" BU_SG_REL_ Gateway_Max SG_ 851 DiETa_Klima 800;
BA_REL_ "GenSigTimeoutTime" BU_SG_REL_ Gateway_Max SG_ 851 DiETa_Mode 800;
BA_REL_ "GenSigTimeoutTime" BU_SG_REL_ Gateway_Max SG_ 851 DiETa_Parken 800;
BA_REL_ "GenSigTimeoutTime" BU_SG_REL_ Gateway_Max SG_ 851 DiETa_FAS_Stufe 800;
BA_REL_ "GenSigTimeoutTime" BU_SG_REL_ Gateway_Max SG_ 851 DiETa_Mode2 800;
BA_REL_ "GenSigTimeoutTime" BU_SG_REL_ Gateway_Max SG_ 1520 DI_KL_58xd 2000;
BA_REL_ "GenSigTimeoutTime" BU_SG_REL_ TSGGen3_BFS SG_ 1714 DGN_Verlernzaehler 5000;
BA_REL_ "GenSigTimeoutTime" BU_SG_REL_ TSGGen3_BFS SG_ 1714 KBI_Kilometerstand 5000;
BA_REL_ "GenSigTimeoutTime" BU_SG_REL_ TSGGen3_BFS SG_ 1714 UH_Jahr 5000;
BA_REL_ "GenSigTimeoutTime" BU_SG_REL_ TSGGen3_BFS SG_ 1714 UH_Monat 5000;
BA_REL_ "GenSigTimeoutTime" BU_SG_REL_ TSGGen3_BFS SG_ 1714 UH_Tag 5000;
BA_REL_ "GenSigTimeoutTime" BU_SG_REL_ TSGGen3_BFS SG_ 1714 UH_Stunde 5000;
BA_REL_ "GenSigTimeoutTime" BU_SG_REL_ TSGGen3_BFS SG_ 1714 UH_Minute 5000;
BA_REL_ "GenSigTimeoutTime" BU_SG_REL_ TSGGen3_BFS SG_ 1714 UH_Sekunde 5000;
BA_REL_ "GenSigTimeoutTime" BU_SG_REL_ TSGGen3_BFS SG_ 1520 DI_KL_58xd 2000;
BA_REL_ "GenSigTimeoutTime" BU_SG_REL_ TSGGen3_BFS SG_ 1520 DI_KL_58xs 2000;
BA_REL_ "GenSigTimeoutTime" BU_SG_REL_ TSGGen3_BFS SG_ 1520 DI_KL_58xt 2000;
BA_REL_ "GenSigTimeoutTime" BU_SG_REL_ TSGGen3_BFS SG_ 2463978714 DoorFunctions_FS_01_CRC 1000;
BA_REL_ "GenSigTimeoutTime" BU_SG_REL_ TSGGen3_BFS SG_ 2463978714 DoorFunctions_FS_01_BZ 1000;
BA_REL_ "GenSigTimeoutTime" BU_SG_REL_ TSGGen3_BFS SG_ 2463978714 FT_Tuer_geoeffnet 1000;
BA_REL_ "GenSigTimeoutTime" BU_SG_REL_ TSGGen3_BFS SG_ 2463978714 FT_verriegelt 1000;
BA_REL_ "GenSigTimeoutTime" BU_SG_REL_ TSGGen3_BFS SG_ 2463978714 FT_gesafet 1000;
BA_REL_ "GenSigTimeoutTime" BU_SG_REL_ TSGGen3_BFS SG_ 2463978714 FT_Schluesselschalter_auf 1000;
BA_REL_ "GenSigTimeoutTime" BU_SG_REL_ TSGGen3_BFS SG_ 2463978714 FT_Schluesselschalter_zu 1000;
BA_REL_ "GenSigTimeoutTime" BU_SG_REL_ TSGGen3_BFS SG_ 2463978714 FT_Unlock_Taster 1000;
BA_REL_ "GenSigTimeoutTime" BU_SG_REL_ TSGGen3_BFS SG_ 2463978714 FT_Lock_Taster 1000;
BA_REL_ "GenSigTimeoutTime" BU_SG_REL_ TSGGen3_BFS SG_ 2463978714 FT_FH_Bew_hoch 1000;
BA_REL_ "GenSigTimeoutTime" BU_SG_REL_ TSGGen3_BFS SG_ 2463978714 FT_FH_Bew_tief 1000;
BA_REL_ "GenSigTimeoutTime" BU_SG_REL_ TSGGen3_BFS SG_ 2463978714 ASW_wakeup 1000;
BA_REL_ "GenSigTimeoutTime" BU_SG_REL_ TSGGen3_BFS SG_ 2463978714 FT_Oben_Block_erw 1000;
BA_REL_ "GenSigTimeoutTime" BU_SG_REL_ TSGGen3_BFS SG_ 2463978714 FT_Unten_Block_erw 1000;
BA_REL_ "GenSigTimeoutTime" BU_SG_REL_ TSGGen3_BFS SG_ 2463978714 FT_Kisi_li_aktiv 1000;
BA_REL_ "GenSigTimeoutTime" BU_SG_REL_ TSGGen3_BFS SG_ 2463978714 FT_Kisi_re_aktiv 1000;
BA_REL_ "GenSigTimeoutTime" BU_SG_REL_ TSGGen3_BFS SG_ 2463978714 FT_Kisi_Taster_li 1000;
BA_REL_ "GenSigTimeoutTime" BU_SG_REL_ TSGGen3_BFS SG_ 2463978714 FT_Kisi_Taster_re 1000;
BA_REL_ "GenSigTimeoutTime" BU_SG_REL_ TSGGen3_BFS SG_ 2463978714 FT_BFS_Fond_Freigabe 1000;
BA_REL_ "GenSigTimeoutTime" BU_SG_REL_ TSGGen3_BFS SG_ 2463978714 FT_SP_Heizung_Status 1000;
BA_REL_ "GenSigTimeoutTime" BU_SG_REL_ TSGGen3_BFS SG_ 2463978714 FT_Tuerschloss_defekt 1000;
BA_REL_ "GenSigTimeoutTime" BU_SG_REL_ TSGGen3_BFS SG_ 2463978714 FS_Status_eTAG 1000;
BA_REL_ "GenSigTimeoutTime" BU_SG_REL_ TSGGen3_BFS SG_ 2463978714 SP_FT_oben 1000;
BA_REL_ "GenSigTimeoutTime" BU_SG_REL_ TSGGen3_BFS SG_ 2463978714 SP_FT_unten 1000;
BA_REL_ "GenSigTimeoutTime" BU_SG_REL_ TSGGen3_BFS SG_ 2463978714 SP_FT_links 1000;
BA_REL_ "GenSigTimeoutTime" BU_SG_REL_ TSGGen3_BFS SG_ 2463978714 SP_FT_rechts 1000;
BA_REL_ "GenSigTimeoutTime" BU_SG_REL_ TSGGen3_BFS SG_ 2463978714 SP_BT_oben 1000;
BA_REL_ "GenSigTimeoutTime" BU_SG_REL_ TSGGen3_BFS SG_ 2463978714 SP_BT_unten 1000;
BA_REL_ "GenSigTimeoutTime" BU_SG_REL_ TSGGen3_BFS SG_ 2463978714 SP_BT_links 1000;
BA_REL_ "GenSigTimeoutTime" BU_SG_REL_ TSGGen3_BFS SG_ 2463978714 SP_BT_rechts 1000;
BA_REL_ "GenSigTimeoutTime" BU_SG_REL_ TSGGen3_BFS SG_ 2463978714 SP_abklappen 1000;
BA_REL_ "GenSigTimeoutTime" BU_SG_REL_ TSGGen3_BFS SG_ 2463978714 SP_anklappen 1000;
BA_REL_ "GenSigTimeoutTime" BU_SG_REL_ TSGGen3_BFS SG_ 2463978714 SP_normieren 1000;
BA_REL_ "GenSigTimeoutTime" BU_SG_REL_ TSGGen3_BFS SG_ 2463978714 SP_Hzg_Taster 1000;
BA_REL_ "GenSigTimeoutTime" BU_SG_REL_ TSGGen3_BFS SG_ 2463978714 SP_Bordsteinfunktion 1000;
BA_REL_ "GenSigTimeoutTime" BU_SG_REL_ TSGGen3_BFS SG_ 2463978714 SP_S_oben 1000;
BA_REL_ "GenSigTimeoutTime" BU_SG_REL_ TSGGen3_BFS SG_ 2463978714 SP_S_unten 1000;
BA_REL_ "GenSigTimeoutTime" BU_SG_REL_ TSGGen3_BFS SG_ 2463978714 SP_S_links 1000;
BA_REL_ "GenSigTimeoutTime" BU_SG_REL_ TSGGen3_BFS SG_ 2463978714 SP_S_rechts 1000;
BA_REL_ "GenSigTimeoutTime" BU_SG_REL_ TSGGen3_BFS SG_ 2463978714 SP_Auswahl_li 1000;
BA_REL_ "GenSigTimeoutTime" BU_SG_REL_ TSGGen3_BFS SG_ 2463978714 SP_Auswahl_re 1000;
BA_REL_ "GenSigTimeoutTime" BU_SG_REL_ TSGGen3_BFS SG_ 2463978714 SP_ARA_Status 1000;
BA_REL_ "GenSigTimeoutTime" BU_SG_REL_ TSGGen3_BFS SG_ 2463978714 SP_S_Klappen 1000;
BA_REL_ "GenSigTimeoutTime" BU_SG_REL_ TSGGen3_BFS SG_ 2463978714 FT_SP_Heizung_ein 1000;
BA_REL_ "GenSigTimeoutTime" BU_SG_REL_ TSGGen3_BFS SG_ 2463978714 FT_Kisi_Taster_li_02 1000;
BA_REL_ "GenSigTimeoutTime" BU_SG_REL_ TSGGen3_BFS SG_ 2463978714 FT_Kisi_Taster_re_02 1000;
BA_REL_ "GenSigTimeoutTime" BU_SG_REL_ TSGGen3_BFS SG_ 2463978714 FT_TCR_Mode_aktiv 1000;
BA_REL_ "GenSigTimeoutTime" BU_SG_REL_ TSGGen3_FS SG_ 1714 DGN_Verlernzaehler 5000;
BA_REL_ "GenSigTimeoutTime" BU_SG_REL_ TSGGen3_FS SG_ 1714 KBI_Kilometerstand 5000;
BA_REL_ "GenSigTimeoutTime" BU_SG_REL_ TSGGen3_FS SG_ 1714 UH_Jahr 5000;
BA_REL_ "GenSigTimeoutTime" BU_SG_REL_ TSGGen3_FS SG_ 1714 UH_Monat 5000;
BA_REL_ "GenSigTimeoutTime" BU_SG_REL_ TSGGen3_FS SG_ 1714 UH_Tag 5000;
BA_REL_ "GenSigTimeoutTime" BU_SG_REL_ TSGGen3_FS SG_ 1714 UH_Stunde 5000;
BA_REL_ "GenSigTimeoutTime" BU_SG_REL_ TSGGen3_FS SG_ 1714 UH_Minute 5000;
BA_REL_ "GenSigTimeoutTime" BU_SG_REL_ TSGGen3_FS SG_ 1714 UH_Sekunde 5000;
BA_REL_ "GenSigTimeoutTime" BU_SG_REL_ TSGGen3_FS SG_ 1520 DI_KL_58xd 2000;
BA_REL_ "GenSigTimeoutTime" BU_SG_REL_ TSGGen3_FS SG_ 1520 DI_KL_58xs 2000;
BA_REL_ "GenSigTimeoutTime" BU_SG_REL_ TSGGen3_FS SG_ 1520 DI_KL_58xt 2000;
BA_REL_ "GenSigTimeoutTime" BU_SG_REL_ TSGGen3_FS SG_ 2463978728 DoorFunctions_BFS_01_CRC 1000;
BA_REL_ "GenSigTimeoutTime" BU_SG_REL_ TSGGen3_FS SG_ 2463978728 DoorFunctions_BFS_01_BZ 1000;
BA_REL_ "GenSigTimeoutTime" BU_SG_REL_ TSGGen3_FS SG_ 2463978728 BT_Tuer_geoeffnet 1000;
BA_REL_ "GenSigTimeoutTime" BU_SG_REL_ TSGGen3_FS SG_ 2463978728 BT_verriegelt 1000;
BA_REL_ "GenSigTimeoutTime" BU_SG_REL_ TSGGen3_FS SG_ 2463978728 BT_Unlock_Taster 1000;
BA_REL_ "GenSigTimeoutTime" BU_SG_REL_ TSGGen3_FS SG_ 2463978728 BT_Lock_Taster 1000;
BA_REL_ "GenSigTimeoutTime" BU_SG_REL_ TSGGen3_FS SG_ 2463978728 BT_TAG_betaetigt 1000;
BA_REL_ "GenSigTimeoutTime" BU_SG_REL_ TSGGen3_FS SG_ 2463978728 BT_TIG_betaetigt 1000;
BA_REL_ "GenSigTimeoutTime" BU_SG_REL_ TSGGen3_FS SG_ 2463978728 BT_EC_Spiegel_Helligkeit 1000;
BA_REL_ "GenSigTimeoutTime" BU_SG_REL_ TSGGen3_FS SG_ 2463978728 BT_Tuer_Status 1000;
BA_REL_ "GenSigTimeoutTime" BU_SG_REL_ TSGGen3_FS SG_ 2463978728 BT_Sp_Blk_def 1000;
BA_REL_ "GenSigTimeoutTime" BU_SG_REL_ TSGGen3_FS SG_ 2463978728 BT_FH_Oeffnung 1000;
BA_REL_ "GenSigTimeoutTime" BU_SG_REL_ TSGGen3_FS SG_ 2463978728 BT_FH_Bew_hoch 1000;
BA_REL_ "GenSigTimeoutTime" BU_SG_REL_ TSGGen3_FS SG_ 2463978728 BT_FH_Bew_tief 1000;
BA_REL_ "GenSigTimeoutTime" BU_SG_REL_ TSGGen3_FS SG_ 2463978728 BT_Kisi_Fehler 1000;
BA_REL_ "GenSigTimeoutTime" BU_SG_REL_ TSGGen3_FS SG_ 2463978728 BT_FH_normiert 1000;
BA_REL_ "GenSigTimeoutTime" BU_SG_REL_ TSGGen3_FS SG_ 2463978728 BT_SP_ausgerastet 1000;
BA_REL_ "GenSigTimeoutTime" BU_SG_REL_ TSGGen3_FS SG_ 2463978728 BT_SP_lr_aktiv 1000;
BA_REL_ "GenSigTimeoutTime" BU_SG_REL_ TSGGen3_FS SG_ 2463978728 BT_SP_ht_aktiv 1000;
BA_REL_ "GenSigTimeoutTime" BU_SG_REL_ TSGGen3_FS SG_ 2463978728 BT_Oben_Block_erw 1000;
BA_REL_ "GenSigTimeoutTime" BU_SG_REL_ TSGGen3_FS SG_ 2463978728 BT_Unten_Block_erw 1000;
BA_REL_ "GenSigTimeoutTime" BU_SG_REL_ TSGGen3_FS SG_ 2463978728 BT_Tuer_Status_QBit 1000;
BA_REL_ "GenSigTimeoutTime" BU_SG_REL_ TSGGen3_FS SG_ 2463978728 BFS_Status_eTAG 1000;
BA_REL_ "GenSigTimeoutTime" BU_SG_REL_ TSGGen3_FS SG_ 2463978728 BT_TCR_Mode_aktiv 1000;
BA_REL_ "GenSigTimeoutTime" BU_SG_REL_ TSGGen3_FS SG_ 2463978728 BT_SP_Heizung_Status 1000;
BA_REL_ "GenSigTimeoutTime" BU_SG_REL_ TSGGen3_FS SG_ 2463978728 BT_FH_Pos_oben 1000;
BA_REL_ "GenSigTimeoutTime" BU_SG_REL_ TSGGen3_FS SG_ 2463978728 BT_Tuerschloss_defekt 1000;
BA_REL_ "GenSigTimeoutTime" BU_SG_REL_ TSGGen3_FS SG_ 2463978728 BT_SWA_HMI_defekt 1000;
BA_REL_ "GenSigTimeoutTime" BU_SG_REL_ TSGGen3_FS SG_ 2463978728 BT_ASW_HMI_defekt 1000;
BA_REL_ "GenSigTimeoutTime" BU_SG_REL_ TSGGen3_FS SG_ 2463978728 SSA_BFT_ASW_Fehler 1000;
BA_REL_ "GenSigTimeoutTime" BU_SG_REL_ TSGGen3_HBFS SG_ 1714 DGN_Verlernzaehler 5000;
BA_REL_ "GenSigTimeoutTime" BU_SG_REL_ TSGGen3_HBFS SG_ 1714 KBI_Kilometerstand 5000;
BA_REL_ "GenSigTimeoutTime" BU_SG_REL_ TSGGen3_HBFS SG_ 1714 UH_Jahr 5000;
BA_REL_ "GenSigTimeoutTime" BU_SG_REL_ TSGGen3_HBFS SG_ 1714 UH_Monat 5000;
BA_REL_ "GenSigTimeoutTime" BU_SG_REL_ TSGGen3_HBFS SG_ 1714 UH_Tag 5000;
BA_REL_ "GenSigTimeoutTime" BU_SG_REL_ TSGGen3_HBFS SG_ 1714 UH_Stunde 5000;
BA_REL_ "GenSigTimeoutTime" BU_SG_REL_ TSGGen3_HBFS SG_ 1714 UH_Minute 5000;
BA_REL_ "GenSigTimeoutTime" BU_SG_REL_ TSGGen3_HBFS SG_ 1714 UH_Sekunde 5000;
BA_REL_ "GenSigTimeoutTime" BU_SG_REL_ TSGGen3_HBFS SG_ 1520 DI_KL_58xd 2000;
BA_REL_ "GenSigTimeoutTime" BU_SG_REL_ TSGGen3_HBFS SG_ 1520 DI_KL_58xs 2000;
BA_REL_ "GenSigTimeoutTime" BU_SG_REL_ TSGGen3_HBFS SG_ 1520 DI_KL_58xt 2000;
BA_REL_ "GenSigTimeoutTime" BU_SG_REL_ TSGGen3_HBFS SG_ 2463978728 DoorFunctions_BFS_01_CRC 1000;
BA_REL_ "GenSigTimeoutTime" BU_SG_REL_ TSGGen3_HBFS SG_ 2463978728 DoorFunctions_BFS_01_BZ 1000;
BA_REL_ "GenSigTimeoutTime" BU_SG_REL_ TSGGen3_HBFS SG_ 2463978728 BT_TSG_hinten_verbaut 1000;
BA_REL_ "GenSigTimeoutTime" BU_SG_REL_ TSGGen3_HBFS SG_ 2463978728 BT_Oben_Block_erw 1000;
BA_REL_ "GenSigTimeoutTime" BU_SG_REL_ TSGGen3_HBFS SG_ 2463978728 BT_Unten_Block_erw 1000;
BA_REL_ "GenSigTimeoutTime" BU_SG_REL_ TSGGen3_HBFS SG_ 2463978728 BT_TCR_Mode_aktiv 1000;
BA_REL_ "GenSigTimeoutTime" BU_SG_REL_ TSGGen3_HBFS SG_ 2463978728 BT_FH_Pos_oben 1000;
BA_REL_ "GenSigTimeoutTime" BU_SG_REL_ TSGGen3_HBFS SG_ 2463978728 BT_Tuerschloss_defekt 1000;
BA_REL_ "GenSigTimeoutTime" BU_SG_REL_ TSGGen3_HBFS SG_ 2463978728 SSA_BFT_ASW_Fehler 1000;
BA_REL_ "GenSigTimeoutTime" BU_SG_REL_ TSGGen3_HBFS SG_ 2463978714 DoorFunctions_FS_01_CRC 1000;
BA_REL_ "GenSigTimeoutTime" BU_SG_REL_ TSGGen3_HBFS SG_ 2463978714 DoorFunctions_FS_01_BZ 1000;
BA_REL_ "GenSigTimeoutTime" BU_SG_REL_ TSGGen3_HBFS SG_ 2463978714 FT_Tuer_geoeffnet 1000;
BA_REL_ "GenSigTimeoutTime" BU_SG_REL_ TSGGen3_HBFS SG_ 2463978714 FT_verriegelt 1000;
BA_REL_ "GenSigTimeoutTime" BU_SG_REL_ TSGGen3_HBFS SG_ 2463978714 FT_gesafet 1000;
BA_REL_ "GenSigTimeoutTime" BU_SG_REL_ TSGGen3_HBFS SG_ 2463978714 FT_Schluesselschalter_auf 1000;
BA_REL_ "GenSigTimeoutTime" BU_SG_REL_ TSGGen3_HBFS SG_ 2463978714 FT_Schluesselschalter_zu 1000;
BA_REL_ "GenSigTimeoutTime" BU_SG_REL_ TSGGen3_HBFS SG_ 2463978714 FT_Unlock_Taster 1000;
BA_REL_ "GenSigTimeoutTime" BU_SG_REL_ TSGGen3_HBFS SG_ 2463978714 FT_Lock_Taster 1000;
BA_REL_ "GenSigTimeoutTime" BU_SG_REL_ TSGGen3_HBFS SG_ 2463978714 FT_FH_Bew_hoch 1000;
BA_REL_ "GenSigTimeoutTime" BU_SG_REL_ TSGGen3_HBFS SG_ 2463978714 FT_FH_Bew_tief 1000;
BA_REL_ "GenSigTimeoutTime" BU_SG_REL_ TSGGen3_HBFS SG_ 2463978714 ASW_wakeup 1000;
BA_REL_ "GenSigTimeoutTime" BU_SG_REL_ TSGGen3_HBFS SG_ 2463978714 FT_Oben_Block_erw 1000;
BA_REL_ "GenSigTimeoutTime" BU_SG_REL_ TSGGen3_HBFS SG_ 2463978714 FT_Unten_Block_erw 1000;
BA_REL_ "GenSigTimeoutTime" BU_SG_REL_ TSGGen3_HBFS SG_ 2463978714 FT_Kisi_li_aktiv 1000;
BA_REL_ "GenSigTimeoutTime" BU_SG_REL_ TSGGen3_HBFS SG_ 2463978714 FT_Kisi_re_aktiv 1000;
BA_REL_ "GenSigTimeoutTime" BU_SG_REL_ TSGGen3_HBFS SG_ 2463978714 FT_Kisi_Taster_li 1000;
BA_REL_ "GenSigTimeoutTime" BU_SG_REL_ TSGGen3_HBFS SG_ 2463978714 FT_Kisi_Taster_re 1000;
BA_REL_ "GenSigTimeoutTime" BU_SG_REL_ TSGGen3_HBFS SG_ 2463978714 FT_BFS_Fond_Freigabe 1000;
BA_REL_ "GenSigTimeoutTime" BU_SG_REL_ TSGGen3_HBFS SG_ 2463978714 FT_SP_Heizung_Status 1000;
BA_REL_ "GenSigTimeoutTime" BU_SG_REL_ TSGGen3_HBFS SG_ 2463978714 FT_Tuerschloss_defekt 1000;
BA_REL_ "GenSigTimeoutTime" BU_SG_REL_ TSGGen3_HBFS SG_ 2463978714 FS_Status_eTAG 1000;
BA_REL_ "GenSigTimeoutTime" BU_SG_REL_ TSGGen3_HBFS SG_ 2463978714 SSR_Temp_Freigabe 1000;
BA_REL_ "GenSigTimeoutTime" BU_SG_REL_ TSGGen3_HBFS SG_ 2463978714 FT_Kisi_Taster_li_02 1000;
BA_REL_ "GenSigTimeoutTime" BU_SG_REL_ TSGGen3_HBFS SG_ 2463978714 FT_Kisi_Taster_re_02 1000;
BA_REL_ "GenSigTimeoutTime" BU_SG_REL_ TSGGen3_HBFS SG_ 2463978714 FT_TCR_Mode_aktiv 1000;
BA_REL_ "GenSigTimeoutTime" BU_SG_REL_ TSGGen3_HFS SG_ 1714 DGN_Verlernzaehler 5000;
BA_REL_ "GenSigTimeoutTime" BU_SG_REL_ TSGGen3_HFS SG_ 1714 KBI_Kilometerstand 5000;
BA_REL_ "GenSigTimeoutTime" BU_SG_REL_ TSGGen3_HFS SG_ 1714 UH_Jahr 5000;
BA_REL_ "GenSigTimeoutTime" BU_SG_REL_ TSGGen3_HFS SG_ 1714 UH_Monat 5000;
BA_REL_ "GenSigTimeoutTime" BU_SG_REL_ TSGGen3_HFS SG_ 1714 UH_Tag 5000;
BA_REL_ "GenSigTimeoutTime" BU_SG_REL_ TSGGen3_HFS SG_ 1714 UH_Stunde 5000;
BA_REL_ "GenSigTimeoutTime" BU_SG_REL_ TSGGen3_HFS SG_ 1714 UH_Minute 5000;
BA_REL_ "GenSigTimeoutTime" BU_SG_REL_ TSGGen3_HFS SG_ 1714 UH_Sekunde 5000;
BA_REL_ "GenSigTimeoutTime" BU_SG_REL_ TSGGen3_HFS SG_ 1520 DI_KL_58xd 2000;
BA_REL_ "GenSigTimeoutTime" BU_SG_REL_ TSGGen3_HFS SG_ 1520 DI_KL_58xs 2000;
BA_REL_ "GenSigTimeoutTime" BU_SG_REL_ TSGGen3_HFS SG_ 1520 DI_KL_58xt 2000;
BA_REL_ "GenSigTimeoutTime" BU_SG_REL_ TSGGen3_HFS SG_ 2463978728 DoorFunctions_BFS_01_CRC 1000;
BA_REL_ "GenSigTimeoutTime" BU_SG_REL_ TSGGen3_HFS SG_ 2463978728 DoorFunctions_BFS_01_BZ 1000;
BA_REL_ "GenSigTimeoutTime" BU_SG_REL_ TSGGen3_HFS SG_ 2463978728 BT_Oben_Block_erw 1000;
BA_REL_ "GenSigTimeoutTime" BU_SG_REL_ TSGGen3_HFS SG_ 2463978728 BT_Unten_Block_erw 1000;
BA_REL_ "GenSigTimeoutTime" BU_SG_REL_ TSGGen3_HFS SG_ 2463978728 BT_TCR_Mode_aktiv 1000;
BA_REL_ "GenSigTimeoutTime" BU_SG_REL_ TSGGen3_HFS SG_ 2463978728 BT_FH_Pos_oben 1000;
BA_REL_ "GenSigTimeoutTime" BU_SG_REL_ TSGGen3_HFS SG_ 2463978728 BT_Tuerschloss_defekt 1000;
BA_REL_ "GenSigTimeoutTime" BU_SG_REL_ TSGGen3_HFS SG_ 2463978728 SSA_BFT_ASW_Fehler 1000;
BA_REL_ "GenSigTimeoutTime" BU_SG_REL_ TSGGen3_HFS SG_ 2463978714 DoorFunctions_FS_01_CRC 1000;
BA_REL_ "GenSigTimeoutTime" BU_SG_REL_ TSGGen3_HFS SG_ 2463978714 DoorFunctions_FS_01_BZ 1000;
BA_REL_ "GenSigTimeoutTime" BU_SG_REL_ TSGGen3_HFS SG_ 2463978714 FT_Tuer_geoeffnet 1000;
BA_REL_ "GenSigTimeoutTime" BU_SG_REL_ TSGGen3_HFS SG_ 2463978714 FT_verriegelt 1000;
BA_REL_ "GenSigTimeoutTime" BU_SG_REL_ TSGGen3_HFS SG_ 2463978714 FT_gesafet 1000;
BA_REL_ "GenSigTimeoutTime" BU_SG_REL_ TSGGen3_HFS SG_ 2463978714 FT_Schluesselschalter_auf 1000;
BA_REL_ "GenSigTimeoutTime" BU_SG_REL_ TSGGen3_HFS SG_ 2463978714 FT_Schluesselschalter_zu 1000;
BA_REL_ "GenSigTimeoutTime" BU_SG_REL_ TSGGen3_HFS SG_ 2463978714 FT_Unlock_Taster 1000;
BA_REL_ "GenSigTimeoutTime" BU_SG_REL_ TSGGen3_HFS SG_ 2463978714 FT_Lock_Taster 1000;
BA_REL_ "GenSigTimeoutTime" BU_SG_REL_ TSGGen3_HFS SG_ 2463978714 FT_TSG_hinten_verbaut 1000;
BA_REL_ "GenSigTimeoutTime" BU_SG_REL_ TSGGen3_HFS SG_ 2463978714 ASW_wakeup 1000;
BA_REL_ "GenSigTimeoutTime" BU_SG_REL_ TSGGen3_HFS SG_ 2463978714 FT_Oben_Block_erw 1000;
BA_REL_ "GenSigTimeoutTime" BU_SG_REL_ TSGGen3_HFS SG_ 2463978714 FT_Unten_Block_erw 1000;
BA_REL_ "GenSigTimeoutTime" BU_SG_REL_ TSGGen3_HFS SG_ 2463978714 FT_Kisi_li_aktiv 1000;
BA_REL_ "GenSigTimeoutTime" BU_SG_REL_ TSGGen3_HFS SG_ 2463978714 FT_Kisi_re_aktiv 1000;
BA_REL_ "GenSigTimeoutTime" BU_SG_REL_ TSGGen3_HFS SG_ 2463978714 FT_Kisi_Taster_li 1000;
BA_REL_ "GenSigTimeoutTime" BU_SG_REL_ TSGGen3_HFS SG_ 2463978714 FT_Kisi_Taster_re 1000;
BA_REL_ "GenSigTimeoutTime" BU_SG_REL_ TSGGen3_HFS SG_ 2463978714 FT_BFS_Fond_Freigabe 1000;
BA_REL_ "GenSigTimeoutTime" BU_SG_REL_ TSGGen3_HFS SG_ 2463978714 FT_SP_Heizung_Status 1000;
BA_REL_ "GenSigTimeoutTime" BU_SG_REL_ TSGGen3_HFS SG_ 2463978714 FT_Tuerschloss_defekt 1000;
BA_REL_ "GenSigTimeoutTime" BU_SG_REL_ TSGGen3_HFS SG_ 2463978714 SSR_Temp_Freigabe 1000;
BA_REL_ "GenSigTimeoutTime" BU_SG_REL_ TSGGen3_HFS SG_ 2463978714 FT_Kisi_Taster_li_02 1000;
BA_REL_ "GenSigTimeoutTime" BU_SG_REL_ TSGGen3_HFS SG_ 2463978714 FT_Kisi_Taster_re_02 1000;
BA_REL_ "GenSigTimeoutTime" BU_SG_REL_ TSGGen3_HFS SG_ 2463978714 FT_TCR_Mode_aktiv 1000;
BA_REL_ "GenSigTimeoutTime" BU_SG_REL_ WLC_01_CFD SG_ 1714 DGN_Verlernzaehler 5000;
BA_REL_ "GenSigTimeoutTime" BU_SG_REL_ WLC_01_CFD SG_ 1714 KBI_Kilometerstand 5000;
BA_REL_ "GenSigTimeoutTime" BU_SG_REL_ WLC_01_CFD SG_ 1714 UH_Jahr 5000;
BA_REL_ "GenSigTimeoutTime" BU_SG_REL_ WLC_01_CFD SG_ 1714 UH_Monat 5000;
BA_REL_ "GenSigTimeoutTime" BU_SG_REL_ WLC_01_CFD SG_ 1714 UH_Tag 5000;
BA_REL_ "GenSigTimeoutTime" BU_SG_REL_ WLC_01_CFD SG_ 1714 UH_Stunde 5000;
BA_REL_ "GenSigTimeoutTime" BU_SG_REL_ WLC_01_CFD SG_ 1714 UH_Minute 5000;
BA_REL_ "GenSigTimeoutTime" BU_SG_REL_ WLC_01_CFD SG_ 1714 UH_Sekunde 5000;
VAL_ 1714 DGN_Verlernzaehler 255 "ungültiger Zählerstand oder kein gültiger Fahrzyklus" ;
VAL_ 1714 KBI_Kilometerstand 1048574 "Init" 1048575 "Fehler" ;
VAL_ 1714 UH_Monat 0 "Init" 14 "Relatives_Datum" 15 "Fehler" ;
VAL_ 1714 UH_Tag 0 "Init" ;
VAL_ 1714 Vehicle_Driving_Cycle 0 "kein_Driving_Cycle_erkannt" 1 "Driving_Cycle_erkannt" ;
VAL_ 1714 Kombi_02_alt 0 "aktuell" 1 "veraltet" ;
VAL_ 1714 Uhrzeit_01_alt 0 "aktuell" 1 "veraltet" ;
VAL_ 851 DiETa_Status 0 "DiETa_betriebsbereit" 2 "Init" 3 "Fehler_oder_defekt" ;
VAL_ 851 DiETa_ResponseError 0 "normal" 1 "Fehler" ;
VAL_ 851 DiETa_Car 0 "Init_oder_nicht_verbaut" 1 "Taste_unbetaetigt" 2 "Taste_betaetigt" 3 "Fehler" ;
VAL_ 851 DiETa_Klima 0 "Init_oder_nicht_verbaut" 1 "Taste_unbetaetigt" 2 "Taste_betaetigt" 3 "Fehler" ;
VAL_ 851 DiETa_Mode 0 "Init_oder_nicht_verbaut" 1 "Taste_unbetaetigt" 2 "Taste_betaetigt" 3 "Fehler" ;
VAL_ 851 DiETa_Parken 0 "Init_oder_nicht_verbaut" 1 "Taste_unbetaetigt" 2 "Taste_betaetigt" 3 "Fehler" ;
VAL_ 851 DiETa_FSH_Taste 0 "Init_oder_nicht_verbaut" 1 "Taste_unbetaetigt" 2 "Taste_betaetigt" 3 "Fehler" ;
VAL_ 851 DiETa_HSH_Taste 0 "Init_oder_nicht_verbaut" 1 "Taste_unbetaetigt" 2 "Taste_betaetigt" 3 "Fehler" ;
VAL_ 851 DiETa_Warnblink_Taste 0 "Init_oder_nicht_verbaut" 1 "Taste_unbetaetigt" 2 "Taste_betaetigt" 3 "Fehler" ;
VAL_ 851 DiETa_FAS_Stufe 0 "Init_oder_nicht_verbaut" 1 "Taste_unbetaetigt" 2 "Taste_betaetigt" 3 "Fehler" ;
VAL_ 851 DiETa_PAO_ON_Status 0 "LED_Aus" 1 "LED_Ein" 2 "LED_Blinkt" 3 "LED_defekt" ;
VAL_ 851 DiETa_PAO_OFF_Status 0 "LED_Aus" 1 "LED_Ein" 2 "LED_Blinkt" 3 "LED_defekt" ;
VAL_ 851 DiETa_Defrost_Taste 0 "Init_oder_nicht_verbaut" 1 "Taste_unbetaetigt" 2 "Taste_betaetigt" 3 "Fehler" ;
VAL_ 851 DiETa_Mode2 0 "Init_oder_nicht_verbaut" 1 "Taste_unbetaetigt" 2 "Taste_betaetigt" 3 "Fehler" ;
VAL_ 851 DiETa_Lock_Unlock_Taste 0 "Init" 1 "Taste_unbetaetigt" 2 "Taste_betaetigt_unlock" 3 "Taste_betaetigt_lock" 4 "Reserviert" 5 "Reserviert" 6 "Reserviert" 7 "Fehler" ;
VAL_ 851 DiETa_Mode_roh 0 "Taste_unbetaetigt" 1 "Taste_betaetigt" ;
VAL_ 851 ESP_Off_Taster 0 "Taste_nicht_betaetigt" 1 "Taste_entprellt_betaetigt" 2 "Init_oder_nicht_verbaut" 3 "Fehler" ;
VAL_ 851 DiETa_Touch_Event 0 "nicht_betaetigt" 1 "Tippen" 2 "Wischen_Slide" 3 "Geste" 4 "Doppeltippen" 5 "Longpress_1" 6 "Longpress_2" 7 "Longpress_3" 8 "Press" 9 "Strongpress" 10 "reserviert" 11 "reserviert" 12 "reserviert" 13 "reserviert" 14 "Taktgeber_Inkrement" 15 "Fehler" ;
VAL_ 1520 DI_KL_58xd 254 "Init" 255 "Fehler" ;
VAL_ 1520 DI_KL_58xs 126 "Init" 127 "Fehler" ;
VAL_ 1520 DI_KL_58xt 126 "Init" 127 "Fehler" ;
VAL_ 1520 BCM1_Stellgroesse_Kl_58s 125 "Nicht_verbaut" 126 "Init" 127 "Fehler" ;
VAL_ 2463978728 eTAB_BFS_Oeffnen_Betaet 0 "Init_keine_Annaeherung" 1 "Betaetigung_Oeffnen_erkannt" ;
VAL_ 2463978728 eTAB_BFS_Oeffnen_Annaeh 0 "Init_keine_Annaeherung" 1 "Annaeherung_Oeffnen_erkannt" ;
VAL_ 2463978728 eTAB_BFS_Schliessen_Betaet 0 "Init_keine_Annaeherung" 1 "Betaetigung_Schliessen_erkannt" ;
VAL_ 2463978728 eTAB_BFS_Schliessen_Annaeh 0 "Init_keine_Annaeherung" 1 "Annaeherung_Schliessen_erkannt" ;
VAL_ 2463978728 BT_Tuer_geoeffnet 0 "geschlossen" 1 "offen" ;
VAL_ 2463978728 BT_verriegelt 0 "Init" 1 "verriegelt" ;
VAL_ 2463978728 BT_gesafet 0 "Init" 1 "gesafet" ;
VAL_ 2463978728 BT_Schluesselschalter_auf 0 "Init" 1 "Schluesselschalter_auf_betaetigt" ;
VAL_ 2463978728 BT_Schluesselschalter_zu 0 "Init" 1 "Schluesselschalter_zu_betaetigt" ;
VAL_ 2463978728 BT_Unlock_Taster 0 "Init" 1 "Unlock_Taster_betaetigt" ;
VAL_ 2463978728 BT_Lock_Taster 0 "Init" 1 "Lock_Taster_betaetigt" ;
VAL_ 2463978728 BT_Sperrklinke 0 "Schloss_in_Vorraste_und_Hauptraste" 1 "Tuer_auf_oder_Tuer_Position_zwischen_Vor_und_Hauptraste" ;
VAL_ 2463978728 BT_TAG_betaetigt 0 "Init" 1 "Tuerinnengriff_betaetigt" ;
VAL_ 2463978728 BT_TIG_betaetigt 0 "Init" 1 "Tuerinnengriff_betaetigt" ;
VAL_ 2463978728 BT_Tuer_Status 0 "Init" 1 "Tuer_geschlossen" 2 "Tuer_offen" 3 "Fehler" ;
VAL_ 2463978728 BT_TSG_hinten_verbaut 0 "nicht verbaut" 1 "verbaut" ;
VAL_ 2463978728 BT_Sp_Blk_def 0 "iO" 1 "Spiegel_Blinker_defekt" ;
VAL_ 2463978728 BT_FH_S_ManHoch 0 "Init" 1 "FH_Schalter_man_hoch_gedrueckt" ;
VAL_ 2463978728 BT_FH_S_AutoHoch 0 "Init" 1 "FH_Schalter_auto_hoch_gedrueckt" ;
VAL_ 2463978728 BT_FH_S_ManTief 0 "Init" 1 "FH_Schalter_man_tief_gedrueckt" ;
VAL_ 2463978728 BT_FH_S_AutoTief 0 "Init" 1 "FH_Schalter_auto_tief_gedrueckt" ;
VAL_ 2463978728 BT_FH_Bew_hoch 0 "Init" 1 "FH_ist_in_Bewegung_hoch" ;
VAL_ 2463978728 BT_FH_Bew_tief 0 "Init" 1 "FH_ist_in_Bewegung_tief" ;
VAL_ 2463978728 BT_FH_Fang 0 "ausserhalb_Fangbereich" 1 "innerhalb_Fangbereich" ;
VAL_ 2463978728 BT_FH_Block 0 "Init" 1 "Fensterheber_Block" ;
VAL_ 2463978728 BT_FH_Thermo 0 "Init" 1 "Thermoschutz_aktiv" ;
VAL_ 2463978728 BT_UEKB_aktiviert 0 "Init" 1 "aktiv" ;
VAL_ 2463978728 BT_Kisi_Fehler 0 "kein_Fehler" 1 "Fehler" ;
VAL_ 2463978728 BT_FH_normiert 0 "Init" 1 "Fenster_normiert" ;
VAL_ 2463978728 BT_Schliesstaster 0 "nicht_betaetigt" 1 "betaetigt" ;
VAL_ 2463978728 BT_Zuziehhilfe_aktiv 0 "Init" 1 "Zuziehhilfe_aktiv" ;
VAL_ 2463978728 BT_SP_ausgerastet 0 "Init" 1 "Spiegel_ausgerastet" ;
VAL_ 2463978728 BT_SP_lr_aktiv 0 "Init" 1 "Spiegel_xAchse_aktiv" ;
VAL_ 2463978728 BT_SP_ht_aktiv 0 "Init" 1 "Spiegel_yAchse_aktiv" ;
VAL_ 2463978728 BT_SP_Heizung_aktiv 0 "BF_Spiegelheizung_aus" 1 "BF_Spiegelheizung_ein" ;
VAL_ 2463978728 BT_Oben_Block_erw 0 "Fensterheber_nicht_in_Blockerwar" 1 "Fensterheber_in_Blockerwartung_o" ;
VAL_ 2463978728 BT_Unten_Block_erw 0 "Fensterheber_nicht_in_Blockerwar" 1 "Fensterheber_in_Blockerwartung_u" ;
VAL_ 2463978728 BT_Tuer_Status_QBit 0 "Status_Tuerkontakt_sicher" 1 "Status_Tuerkontakt_unsicher" ;
VAL_ 2463978728 BFS_Status_eTAG 0 "Init" 1 "Griff_ausgefahren" 2 "Griff_eingefahren" 3 "Fehler" ;
VAL_ 2463978728 BT_TCR_Mode_aktiv 0 "TCR_Mode_deaktiv" 1 "TCR_Mode_aktiv" ;
VAL_ 2463978728 BT_Lock_Unlock_Taster 0 "nicht_betaetigt" 1 "betaetigt" ;
VAL_ 2463978728 BT_SP_Heizung_Status 0 "Init" 1 "Status_Spiegelheizung_ein" ;
VAL_ 2463978728 ASW_Warnung_aktiv_BFS 0 "nicht_angefordert" 1 "angefordert" ;
VAL_ 2463978728 BT_FH_Pos_oben 1 "Scheibe oben (nach Absenken auf Position) " ;
VAL_ 2463978728 BT_Tuerschloss_defekt 0 "Tuerschloss_funktionsfaehig" 1 "Tuerschloss_defekt" ;
VAL_ 2463978728 BT_Tueroeffnen_Warnung 0 "Tuerwarnung_nicht_aktiv" 1 "Tuerwarnung_aktiv" ;
VAL_ 2463978728 BT_Lock_Taster_inv 0 "Lock Taster betätigt" 1 "Lock Taster nicht betätigt" ;
VAL_ 2463978728 BT_Schluesselschalter_zu_inv 0 "Schlüsselschalter betätigt" 1 "Schlüsselschalter nicht betätigt" ;
VAL_ 2463978728 BT_SWA_HMI_defekt 0 "SWA_kein_Fehler" 1 "SWA_Fehler" ;
VAL_ 2463978728 BT_ASW_HMI_defekt 0 "ASW_kein_Fehler" 1 "ASW_Fehler" ;
VAL_ 2463978728 BT_Schloss_oeffnen_Ansteuerung 0 "Init" 1 "deaktiv_nicht_ansteuern" 2 "aktiv_oeffnen_ansteuern" 3 "Fehler" ;
VAL_ 2463978728 BT_Schloss_Status_OeH_Motor 0 "Init" 1 "OeH_Motor_Grundstellung" 2 "OeH_Motor_perm_offen" 3 "Fehler" ;
VAL_ 2463978728 MTBT_Pos1 0 "Taste_nicht_gedrueckt" 1 "Postionstaste_1_BT_gedrueckt" ;
VAL_ 2463978728 MTBT_Pos2 0 "Taste_nicht_gedrueckt" 1 "Postionstaste_2_BT_gedrueckt" ;
VAL_ 2463978728 MTBT_Pos3 0 "Taste_nicht_gedrueckt" 1 "Postionstaste_3_BT_gedrueckt" ;
VAL_ 2463978728 MTBT_Pos4 0 "Taste_nicht_gedrueckt" 1 "Postionstaste_4_BT_gedrueckt" ;
VAL_ 2463978728 MTBT_On_Off 0 "Taste_nicht_gedrueckt" 1 "OnOff_Taste_BT_gedrueckt" ;
VAL_ 2463978728 MTBT_M_Taste 0 "Taste_nicht_gedrueckt" 1 "MTaste_BT_gedrueckt" ;
VAL_ 2463978728 TSG_FlHz_BFS_Unterbrech_HzK_B 0 "keine_Unterbrechung" 1 "Unterbrechung" ;
VAL_ 2463978728 TSG_FlHz_BFS_NTC_A 125 "Fehler_NTC_OpenLoad_KS_Plus" 126 "Fehler_NTC_Overload_KS_Minus" 127 "Init" ;
VAL_ 2463978728 TSG_FlHz_BFS_FnAbbruchHzKreis_A 0 "OK" 1 "FunktionsAbbruch" ;
VAL_ 2463978728 TSG_FlHz_BFS_NTC_B 125 "Fehler_NTC_OpenLoad_KS_Plus" 126 "Fehler_NTC_Overload_KS_Minus" 127 "Init" ;
VAL_ 2463978728 TSG_FlHz_BFS_FnAbbruchHzKreis_B 0 "OK" 1 "FunktionsAbbruch" ;
VAL_ 2463978728 SSA_BFT_ASP_Spiegelglas_Fehler 0 "in_Ordnung" 1 "nicht_verbaut" 2 "Unterspannung" 3 "Ueberspannung" 4 "elektrischer_Fehler" 5 "Bedingung_nicht_erfuellt" ;
VAL_ 2463978728 SSA_BFT_ASW_Fehler 0 "iO" 1 "nicht_verbaut" 2 "Unterspannung" 3 "Ueberspannung" 4 "el_Fehler" 5 "Bedingung_nicht_erfuellt" ;
VAL_ 2463978728 SSA_BFT_ASW_Status 0 "Init" 1 "InfoStufe_aktiv" 2 "Warnstufe_aktiv" ;
VAL_ 2463978728 SSA_BFT_el_Tuerantrieb_Fehler 0 "iO" 1 "nicht_verbaut" 2 "Unterspannung" 3 "Ueberspannung" 4 "el_Fehler" 5 "Bedingung_nicht_erfuellt" ;
VAL_ 2463978728 SSA_BFT_FH_Bewegungsrichutng 0 "Stillstand" 1 "FH_in_Bewegung_Schliessen" 2 "FH_in_Bewegung_Oeffnen" ;
VAL_ 2463978728 SSA_BFT_FH_Fehler 0 "iO" 1 "nicht_verbaut" 2 "Unterspannung" 3 "Ueberspannung" 4 "el_Fehler" 5 "Bedingung_nicht_erfuellt" ;
VAL_ 2463978728 SSA_BFT_Tuerverschluss_Status 0 "Init" 1 "Tuer_geschlossen" 2 "Tuer_offen" ;
VAL_ 2463978728 SSA_BFT_ZZH_Fehler 0 "in_Ordnung" 1 "nicht_verbaut" 2 "Unterspannung" 3 "Ueberspannung" 4 "elektrischer_Fehler" 5 "Bedingung_nicht_erfuellt" ;
VAL_ 2463978728 SSA_BFT_ZZH_Status 0 "Init" 1 "Zuziehvorgang_aktiv" ;
VAL_ 2463978728 BFT_HSK_Taste 0 "Taste_HSK_auf_nicht_gedrueckt" 1 "Taste_HSK_auf_gedrueckt" ;
VAL_ 2463978728 SSA_BFT_ASP_Klappung_Status 0 "Init" 1 "angeklappt_Garagenstellung" 2 "abgeklappt_Fahrstellung" 3 "In_Bewegung" ;
VAL_ 2463978728 SSA_BFT_ASP_Spiegelglas_Pos_Y 127 "Fehler" ;
VAL_ 2463978728 SSA_BFT_ZV_Ansteuern 0 "Init" 1 "entriegelnentsafen" 2 "verriegelnentsafen" 3 "verriegelnsafen" 255 "Fehler" ;
VAL_ 2463978728 SSA_BFT_FH_Thermoschutz 0 "Thermoschutz_deaktiv" 1 "Thermoschutz_aktiv" ;
VAL_ 2463978728 SSA_BFT_Amb_Bel_Status 0 "Init" 1 "an" 2 "aus" ;
VAL_ 2463978728 SSA_BFT_Tuerverschluss_Fehler 0 "i.O." 1 "nicht verbaut" 2 "Unterspannung" 3 "Ueberspannung" 4 "el. Fehler" 5 "Bedingung nicht erfuellt" ;
VAL_ 2463978728 SSA_BFT_FH_Normierung 0 "nicht_normiert" 1 "normiert" ;
VAL_ 2463978728 SSA_BFT_el_Tuerantrieb_Status 0 "Init" 1 "offen" 2 "geschlossen" ;
VAL_ 2463978728 SSA_BFT_ASP_Klappung_Fehler 0 "i.O." 1 "nicht verbaut" 2 "Unterspannung" 3 "Ueberspannung" 4 "el. Fehler" 5 "Bedingung nicht erfuellt" ;
VAL_ 2463978728 SSA_BFT_ZV_Fehler 0 "i.O." 1 "nicht verbaut" 2 "Unterspannung" 3 "Ueberspannung" 4 "el. Fehler" 5 "Bedingung nicht erfuellt" ;
VAL_ 2463978728 SSA_BFT_Amb_Bel_Fehler 0 "iO" 1 "nicht_verbaut" 2 "Unterspannung" 3 "Ueberspannung" 4 "el_Fehler" 5 "Bedingung_nicht_erfuellt" ;
VAL_ 2463978728 ASW_Warnung_Aussenlicht_BFS_Li 0 "ASW_Warnung_nicht_aktiv" 1 "ASW_Warnung_aktiv" ;
VAL_ 2463978728 ASW_Warnung_Aussenlicht_BFS_Re 0 "ASW_Warnung_nicht_aktiv" 1 "ASW_Warnung_aktiv" ;
VAL_ 2463978728 SSA_BFT_ASP_Heizung_Fehler 0 "iO" 1 "nicht_verbaut" 2 "Unterspannung" 3 "Ueberspannung" 4 "el_Fehler" 5 "Bedingung_nicht_erfuellt" ;
VAL_ 2463978728 BT_ASW_Warnton 0 "kein_warnton" 1 "warnton_links" 2 "warnton_rechts" 3 "Fehler" ;
VAL_ 2463978728 BT_ASW_Warnung_Aussenlicht 0 "kein_licht" 1 "licht_links" 2 "licht_rechts" 3 "Fehler" ;
VAL_ 2463978728 BFS_Push_Tuergriff 0 "nicht_erkannt" 1 "erkannt" ;
VAL_ 2463978728 BFS_Status_eTAG_ext 0 "Griff_eingefahren" 1 "Griff_ausgefahren" 2 "Griff_verfaehrt" 3 "init" 4 "Fehler" ;
VAL_ 2463978714 eTAB_FS_Oeffnen_Annaeh 0 "Init_keine_Annaeherung" 1 "Annaeherung_Oeffnen_erkannt" ;
VAL_ 2463978714 eTAB_FS_Oeffnen_Betaet 0 "Init_keine_Annaeherung" 1 "Betaetigung_Oeffnen_erkannt" ;
VAL_ 2463978714 eTAB_FS_Schliessen_Annaeh 0 "Init_keine_Annaeherung" 1 "Annaeherung_Schliessen_erkannt" ;
VAL_ 2463978714 eTAB_FS_Schliessen_Betaet 0 "Init_keine_Annaeherung" 1 "Betaetigung_Schliessen_erkannt" ;
VAL_ 2463978714 FT_Tuer_geoeffnet 0 "geschlossen" 1 "Tuer_offen" ;
VAL_ 2463978714 FT_verriegelt 0 "Init" 1 "verriegelt" ;
VAL_ 2463978714 FT_gesafet 0 "Init" 1 "gesafet" ;
VAL_ 2463978714 FT_Schluesselschalter_auf 0 "Init" 1 "Schluesselschalter_auf_betaetigt" ;
VAL_ 2463978714 FT_Schluesselschalter_zu 1 "Schluesselschalter zu betaetigt" ;
VAL_ 2463978714 FT_Unlock_Taster 0 "Init" 1 "Unlock_Taster_betaetigt" ;
VAL_ 2463978714 FT_Lock_Taster 0 "Init" 1 "Lock_Taster_betaetigt" ;
VAL_ 2463978714 FT_Sperrklinke 0 "Schloss_in_Vorraste_und_Hauptraste" 1 "Tuer_auf_oder_Tuer_Position_zwischen_Vor_und_Hauptraste" ;
VAL_ 2463978714 FT_TAG_betaetigt 0 "nicht_betaetigt" 1 "betaetigt" ;
VAL_ 2463978714 FT_TIG_betaetigt 0 "nicht_betaetigt" 1 "betaetigt" ;
VAL_ 2463978714 FT_IRUE_Taste 0 "Init" 1 "IRUE_Taste_betaetigt" ;
VAL_ 2463978714 FT_HD_Taste 0 "nicht_betaetigt" 1 "Heckdeckeltaste_betaetigt" ;
VAL_ 2463978714 FT_TD_Taste_Fehler 0 "iO" 1 "defekt" ;
VAL_ 2463978714 FT_TD_Taste 0 "Init" 1 "Tankdeckel_Taster_betaetigt" ;
VAL_ 2463978714 eTAB_FS_Bowdenzug_Auswerfen 0 "nicht_auswerfen" 1 "auswerfen" ;
VAL_ 2463978714 FT_HD_Taste_2 0 "Taste_nicht_gedrueckt" 1 "Taste_gedrueckt" ;
VAL_ 2463978714 FT_Lock_Unlock_Taster 0 "nicht_betaetigt" 1 "betaetigt" ;
VAL_ 2463978714 FT_TSG_hinten_verbaut 0 "nicht verbaut" 1 "verbaut" ;
VAL_ 2463978714 FT_Sp_Blk_def 0 "iO" 1 "defekt" ;
VAL_ 2463978714 FT_FH_S_ManHoch 0 "Init" 1 "FH_Schalter_man_hoch_betaetigt" ;
VAL_ 2463978714 FT_FH_S_AutoHoch 0 "Init" 1 "FH_Schalter_auto_hoch_betaetigt" ;
VAL_ 2463978714 FT_FH_S_ManTief 0 "Init" 1 "FH_Schalter_man_tief_betaetigt" ;
VAL_ 2463978714 FT_FH_S_AutoTief 0 "Init" 1 "FH_Schalter_auto_tief_betaetigt" ;
VAL_ 2463978714 FT_FH_Bew_hoch 0 "Init" 1 "FH_in_Bewegung_hoch" ;
VAL_ 2463978714 FT_FH_Bew_tief 0 "Init" 1 "FH_in_Bewegung_tief" ;
VAL_ 2463978714 FT_FH_Fang 0 "ausserhalb_Fangbereich" 1 "innerhalb_Fangbereich" ;
VAL_ 2463978714 FT_FH_Block 0 "Init" 1 "Fenster_Block" ;
VAL_ 2463978714 FT_FH_Thermo 0 "Init" 1 "Thermoschutz_aktiv" ;
VAL_ 2463978714 FT_UEKB_aktiviert 0 "Init" 1 "UEKB_aktiv" ;
VAL_ 2463978714 ASW_HMI_defekt 0 "iO" 1 "defekt" ;
VAL_ 2463978714 FT_FH_normiert 0 "Init" 1 "Fenster_normiert" ;
VAL_ 2463978714 FT_Schliesstaster 1 "Schliesstaster_betaetigt" ;
VAL_ 2463978714 FT_Zuziehhilfe_aktiv 0 "Init" 1 "Zuziehilfe_aktiv" ;
VAL_ 2463978714 FT_SP_ausgerastet 0 "Init" 1 "Spiegel_ausgerastet" ;
VAL_ 2463978714 FT_SP_lr_aktiv 0 "Init" 1 "Spiegel_xAchse_aktiv" ;
VAL_ 2463978714 FT_SP_ht_aktiv 0 "Init" 1 "Spiegel_yAchse_aktiv" ;
VAL_ 2463978714 ASW_wakeup 0 "Sleep" 1 "Wakeup" ;
VAL_ 2463978714 FT_Oben_Block_erw 0 "Fensterheber_nicht_in_Blockerwar" 1 "Fensterheber_in_Blockerwartung_o" ;
VAL_ 2463978714 FT_Unten_Block_erw 0 "Fensterheber_nicht_in_Blockerwar" 1 "Fensterheber_in_Blockerwartung_u" ;
VAL_ 2463978714 FT_Kisi_li_aktiv 0 "inaktiv" 1 "aktiv" ;
VAL_ 2463978714 FT_Kisi_re_aktiv 0 "inaktiv" 1 "aktiv" ;
VAL_ 2463978714 FT_Kisi_Taster_li 0 "nicht_betaetigt" 1 "betaetigt" ;
VAL_ 2463978714 FT_Kisi_Taster_re 0 "nicht_betaetigt" 1 "betaetigt" ;
VAL_ 2463978714 FT_BFS_Fond_Freigabe 0 "Init" 1 "Freigabe_fuer_Fondbedienung_BFS" ;
VAL_ 2463978714 FT_Kisi_Fehler 0 "kein_Fehler" 1 "Fehler" ;
VAL_ 2463978714 FT_Daemmglas 0 "Normalglas_verbaut" 1 "Daemmglas_verbaut" ;
VAL_ 2463978714 FT_SP_Heizung_Status 0 "Init" 1 "Status_Spiegelheizung_ein" ;
VAL_ 2463978714 ASW_Warnung_aktiv_FS 0 "nicht_angefordert" 1 "angefordert" ;
VAL_ 2463978714 FT_FH_Pos_oben 1 "Scheibe oben (nach Absenken auf Position) " ;
VAL_ 2463978714 FT_Tuerschloss_defekt 0 "Tuerschloss_funktionsfaehig" 1 "Tuerschloss_defekt" ;
VAL_ 2463978714 FT_SWA_Taster 0 "Taster_nicht_betaetigt" 1 "Taster_betaetigt" ;
VAL_ 2463978714 SWA_HMI_Diagnose 0 "kein_Fehler_erkannt" 1 "Fehler_Taster_erkannt" 2 "Fehler_LED_erkannt" 3 "Fehler_LED_und_Taster_erkannt" ;
VAL_ 2463978714 FS_Status_eTAG 0 "Init" 1 "Griff_ausgefahren" 2 "Griff_eingefahren" 3 "Fehler" ;
VAL_ 2463978714 FT_Schloss_oeffnen_Ansteuerung 0 "Init" 1 "deaktiv_nicht_ansteuern" 2 "aktiv_oeffnen_ansteuern" 3 "Fehler" ;
VAL_ 2463978714 FT_Schloss_Status_OeH_Motor 0 "Init" 1 "OeH_Motor_Grundstellung" 2 "OeH_Motor_perm_offen" 3 "Fehler" ;
VAL_ 2463978714 MTFT_Pos1_EE 0 "Taste_nicht_gedrueckt" 1 "Postionstaste_1_FT_gedrueckt" ;
VAL_ 2463978714 MTFT_Pos2 0 "Taste_nicht_gedrueckt" 1 "Postionstaste_2_FT_gedrueckt" ;
VAL_ 2463978714 MTFT_Pos3 0 "Taste_nicht_gedrueckt" 1 "Postionstaste_3_FT_gedrueckt" ;
VAL_ 2463978714 MTFT_Pos4 0 "Taste_nicht_gedrueckt" 1 "Postionstaste_4_FT_gedrueckt" ;
VAL_ 2463978714 MTFT_On_Off 0 "Taste_nicht_gedrueckt" 1 "On-Off Taste FT gedrückt" ;
VAL_ 2463978714 MTFT_Verst_akt 0 "Verstellung_nicht_aktiv" 1 "Verstellung_aktiv" ;
VAL_ 2463978714 MTFT_M_Taste 0 "Taste_nicht_gedrueckt" 1 "MTaste_FT_gedrueckt" ;
VAL_ 2463978714 TSG_FlHz_FS_Unterbrech_HzK_A 0 "keine_Unterbrechung" 1 "Unterbrechung" ;
VAL_ 2463978714 TSG_FlHz_FS_Unterbrech_HzK_B 0 "keine_Unterbrechung" 1 "Unterbrechung" ;
VAL_ 2463978714 TSG_FlHz_FS_NTC_A 125 "Fehler_NTC_OpenLoad_KS_Plus" 126 "Fehler_NTC_Overload_KS_Minus" 127 "Init" ;
VAL_ 2463978714 TSG_FlHz_FS_FnAbbruchHzKreis_A 0 "OK" 1 "FunktionsAbbruch" ;
VAL_ 2463978714 TSG_FlHz_FS_NTC_B 125 "Fehler_NTC_OpenLoad_KS_Plus" 126 "Fehler_NTC_Overload_KS_Minus" 127 "Init" ;
VAL_ 2463978714 TSG_FlHz_FS_FnAbbruchHzKreis_B 0 "OK" 1 "FunktionsAbbruch" ;
VAL_ 2463978714 SSA_FT_ASP_Klappung_Fehler 0 "in_Ordnung" 1 "nicht_verbaut" 2 "Unterspannung" 3 "Ueberspannung" 4 "elektrischer_Fehler" 5 "Bedingung_nicht_erfuellt" ;
VAL_ 2463978714 SSA_FT_ASP_Spiegelglas_Fehler 0 "in_Ordnung" 1 "nicht_verbaut" 2 "Unterspannung" 3 "Ueberspannung" 4 "elektrischer_Fehler" 5 "Bedingung_nicht_erfuellt" ;
VAL_ 2463978714 SSA_FT_ASW_Fehler 0 "iO" 1 "nicht_verbaut" 2 "Unterspannung" 3 "Ueberspannung" 4 "el_Fehler" 5 "Bedingung_nicht_erfuellt" ;
VAL_ 2463978714 SSA_FT_ASW_Status 0 "Init" 1 "InfoStufe_aktiv" 2 "Warnstufe_aktiv" ;
VAL_ 2463978714 SSA_FT_el_Tuerantrieb_Fehler 0 "iO" 1 "nicht_verbaut" 2 "Unterspannung" 3 "Ueberspannung" 4 "el_Fehler" 5 "Bedingung_nicht_erfuellt" ;
VAL_ 2463978714 SSA_FT_el_Tuerantrieb_Status 0 "Init" 1 "offen" 2 "geschlossen" ;
VAL_ 2463978714 SSA_FT_FH_Bewegungsrichutng 0 "Stillstand" 1 "FH_in_Bewegung_Schliessen" 2 "FH_in_Bewegung_Oeffnen" ;
VAL_ 2463978714 SSA_FT_FH_Fehler 0 "iO" 1 "nicht_verbaut" 2 "Unterspannung" 3 "Ueberspannung" 4 "el_Fehler" 5 "Bedingung_nicht_erfuellt" ;
VAL_ 2463978714 SSA_FT_FH_Normierung 0 "nicht_normiert" 1 "normiert" ;
VAL_ 2463978714 SSA_FT_FH_Thermoschutz 0 "Thermoschutz_deaktiv" 1 "Thermoschutz_aktiv" ;
VAL_ 2463978714 SSA_FT_Tuerverschluss_Status 0 "Init" 1 "Tuer_geschlossen" 2 "Tuer_offen" ;
VAL_ 2463978714 SSA_FT_ZZH_Fehler 0 "in_Ordnung" 1 "nicht_verbaut" 2 "Unterspannung" 3 "Ueberspannung" 4 "elektrischer_Fehler" 5 "Bedingung_nicht_erfuellt" ;
VAL_ 2463978714 SSA_FT_ZZH_Status 0 "Init" 1 "Zuziehvorgang_aktiv" ;
VAL_ 2463978714 SSR_Temp_Freigabe 0 "SSR_Deaktiviert" 1 "SSR_Freigegeben" ;
VAL_ 2463978714 ASW_Warnung_Aussenlicht_FS_Li 0 "ASW_Warnung_nicht_aktiv" 1 "ASW_Warnung_aktiv" ;
VAL_ 2463978714 ASW_Warnung_Aussenlicht_FS_Re 0 "ASW_Warnung_nicht_aktiv" 1 "ASW_Warnung_aktiv" ;
VAL_ 2463978714 MemFT_Pos3 0 "aus" 1 "ein" 2 "Init" 3 "Fehler" ;
VAL_ 2463978714 FT_ASW_Warnton 0 "kein_warnton" 1 "warnton_links" 2 "warnton_rechts" 3 "Fehler" ;
VAL_ 2463978714 FT_ASW_Warnung_Aussenlicht 0 "kein_licht" 1 "licht_links" 2 "licht_rechts" 3 "Fehler" ;
VAL_ 2463978714 MemFT_Pos2 0 "aus" 1 "ein" 2 "Init" 3 "Fehler" ;
VAL_ 2463978714 MemFT_Pos4 0 "aus" 1 "ein" 2 "Init" 3 "Fehler" ;
VAL_ 2463978714 MemFT_Pos1_EE 0 "aus" 1 "ein" 2 "Init" 3 "Fehler" ;
VAL_ 2463978714 SP_FT_oben 0 "nicht_betaetigt" 1 "betaetigt" ;
VAL_ 2463978714 SP_FT_unten 0 "nicht_betaetigt" 1 "betaetigt" ;
VAL_ 2463978714 SP_FT_links 0 "nicht_betaetigt" 1 "betaetigt" ;
VAL_ 2463978714 SP_FT_rechts 0 "nicht_betaetigt" 1 "betaetigt" ;
VAL_ 2463978714 SP_BT_oben 0 "nicht_betaetigt" 1 "betaetigt" ;
VAL_ 2463978714 SP_BT_unten 0 "nicht_betaetigt" 1 "betaetigt" ;
VAL_ 2463978714 SP_BT_links 0 "nicht_betaetigt" 1 "betaetigt" ;
VAL_ 2463978714 SP_BT_rechts 0 "nicht_betaetigt" 1 "betaetigt" ;
VAL_ 2463978714 SP_abklappen 0 "Spiegel_abklappen_nicht_aktiv" 1 "Spiegel_abklappen_aktiv" ;
VAL_ 2463978714 SP_anklappen 0 "Spiegle_anklappen_nicht_aktiv" 1 "Spiegel_anklappen_aktiv" ;
VAL_ 2463978714 SP_normieren 0 "Spiegel_nicht_normiert" 1 "Spiegel_normiert" ;
VAL_ 2463978714 SP_Spg_Verstellschalter_Fehler 0 "kein_Fehler" 1 "Fehler" ;
VAL_ 2463978714 SP_Hzg_Taster 0 "nicht_betaetigt" 1 "betaetigt" ;
VAL_ 2463978714 SP_Bordsteinfunktion 0 "Bordsteinfunktion_FS/BFS_inaktiv" 1 "Bordsteinfunktion_BFS_aktiv" 2 "Bordsteinfunktion_FS_aktiv" 3 "Bordsteinfunktion_FS/BFS_aktiv" ;
VAL_ 2463978714 SP_S_oben 1 "Spiegelschalter in Stellung oben" ;
VAL_ 2463978714 SP_S_unten 1 "Spiegelschalter in Stellung unten" ;
VAL_ 2463978714 SP_S_links 1 "Spiegelschalter in Stellung links" ;
VAL_ 2463978714 SP_S_rechts 1 "Spiegelschalter in Stellung rechts" ;
VAL_ 2463978714 SP_Auswahl_li 1 "Spiegelschalter in Stellung Auswahl links" ;
VAL_ 2463978714 SP_Auswahl_re 1 "Spiegelschalter in Stellung Auswahl rechts" ;
VAL_ 2463978714 SP_ARA_Status 0 "TSG nicht im ARA-Modus" 1 "TSG im ARA-Modus" ;
VAL_ 2463978714 SP_S_Klappen 1 "Spiegelschalter in Stellung Klappen" ;
VAL_ 2463978714 SP_Verstellschalter_Fehler 0 "kein_Fehler" 1 "Fehler" ;
VAL_ 2463978714 FT_Tuer_Status 0 "Init" 1 "Tuer_geschlossen" 2 "Tuer_offen" 3 "Fehler" ;
VAL_ 2463978714 FT_Tuer_Status_QBit 0 "Status_Tuerkontakt_sicher" 1 "Status_Tuerkontakt_unsicher" ;
VAL_ 2463978714 FT_BFS_Tuer_Status 0 "Init" 1 "Tuer_geschlossen" 2 "Tuer_offen" 3 "Fehler" ;
VAL_ 2463978714 FT_HBFS_Tuer_Status 0 "Init" 1 "Tuer_geschlossen" 2 "Tuer_offen" 3 "Fehler" ;
VAL_ 2463978714 FT_HFS_Tuer_Status 0 "Init" 1 "Tuer_geschlossen" 2 "Tuer_offen" 3 "Fehler" ;
VAL_ 2463978714 FT_Tueroeffnen_Warnung 0 "Tuerwarnung_nicht_aktiv" 1 "Tuerwarnung_aktiv" ;
VAL_ 2463978714 FT_SP_Heizung_ein 0 "Aus" 1 "Ein" ;
VAL_ 2463978714 FT_Kisi_Taster_li_02 0 "nicht_betaetigt" 1 "betaetigt" ;
VAL_ 2463978714 FT_Kisi_Taster_re_02 0 "nicht_betaetigt" 1 "betaetigt" ;
VAL_ 2463978714 FT_TD_Taste_Status 0 "kein_Fehler" 1 "Kurzschluss_nach_Minus" 2 "Kurzschluss_nach_Plus" 3 "Leitungsunterbrechung" ;
VAL_ 2463978714 FT_TCR_Mode_aktiv 0 "TCR_Mode_deaktiv" 1 "TCR_Mode_aktiv" ;
VAL_ 2463978714 TBF_FS_Touch_Event 0 "nicht_betaetigt" 1 "Tippen" 2 "Wischen" 3 "Geste" 4 "Doppeltippen" 5 "Longpress_1" 6 "Longpress_2" 7 "reserviert" 8 "reserviert" 9 "reserviert" 10 "reserviert" 11 "reserviert" 12 "reserviert" 13 "reserviert" 14 "reserviert" 15 "reserviert" ;
VAL_ 2463978714 FT_KiSi_Status_Soll_HBFS 0 "inaktiv" 1 "aktiv" ;
VAL_ 2463978714 FT_KiSi_Status_Soll_HFS 0 "inaktiv" 1 "aktiv" ;
VAL_ 2463978714 FS_Push_Tuergriff 0 "nicht_erkannt" 1 "erkannt" ;
VAL_ 2463978714 TSG_FS_Spiegel_angeklappt 0 "Spiegel_ausgeklappt" 1 "Spiegel_eingeklappt" ;
VAL_ 2463978714 FT_Cargolock_bet 0 "nicht_betaetigt" 1 "betaetigt" ;
VAL_ 2463978714 SSA_FT_ASP_Heizung_Fehler 0 "i.O." 1 "nicht verbaut" 2 "Unterspannung" 3 "Ueberspannung" 4 "el. Fehler" 5 "Bedingung nicht erfuellt" ;
VAL_ 2463978714 SSA_FT_Amb_Bel_Fehler 0 "iO" 1 "nicht_verbaut" 2 "Unterspannung" 3 "Ueberspannung" 4 "el_Fehler" 5 "Bedingung_nicht_erfuellt" ;
VAL_ 2463978714 SSA_FT_Amb_Bel_Status 0 "Init" 1 "an" 2 "aus" ;
VAL_ 2463978714 SSA_FT_ASP_Spiegelglas_Pos_X 127 "Fehler" ;
VAL_ 2463978714 SSA_FT_ZV_Status 0 "Init" 1 "entriegeltentsafet" 2 "verriegeltentsafet" 3 "verriegeltgesafet" 15 "Fehler" ;
VAL_ 2463978714 FS_Status_eTAG_ext 0 "Griff_eingefahren" 1 "Griff_ausgefahren" 2 "Griff_verfaehrt" 3 "init" 4 "Fehler" ;
VAL_ 2463978714 SSA_FT_Tuerverschluss_Fehler 0 "i.O." 1 "nicht verbaut" 2 "Unterspannung" 3 "Ueberspannung" 4 "el. Fehler" 5 "Bedingung nicht erfuellt" ;
VAL_ 2463978714 SSA_FT_ZV_Fehler 0 "i.O." 1 "nicht verbaut" 2 "Unterspannung" 3 "Ueberspannung" 4 "el. Fehler" 5 "Bedingung nicht erfuellt" ;
VAL_ 2463978714 FT_HD_Taste_auf 0 "Taste_HD_auf_nicht_gedrueckt" 1 "Taste_HD_auf_gedrueckt" ;
VAL_ 2463978714 FT_HD_Taste_zu 0 "Taste_HD_zu_nicht_gedrueckt" 1 "Taste_HD_zu_gedrueckt" ;
